VERSION "canboat-J1939-curated"

NS_ :

BS_:

BU_: Vector__XXX
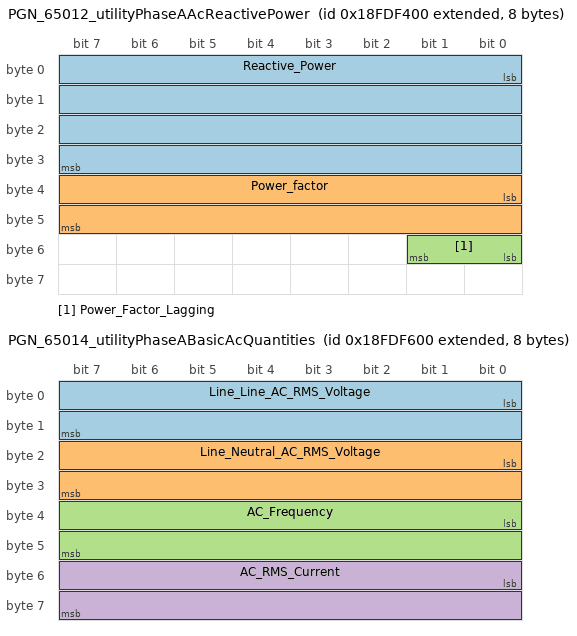
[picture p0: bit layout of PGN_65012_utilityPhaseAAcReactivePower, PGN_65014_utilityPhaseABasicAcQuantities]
BO_ 2566779904 PGN_65012_utilityPhaseAAcReactivePower: 8 Vector__XXX
 SG_ Reactive_Power : 0|32@1- (1.0,0) [-2147483648|2147483647] "" Vector__XXX
 SG_ Power_factor : 32|16@1+ (6.103515625e-05,0) [0.0|3.99993896484375] "Cos Phi" Vector__XXX
 SG_ Power_Factor_Lagging : 48|2@1+ (1.0,0) [0|3] "" Vector__XXX

BO_ 2566780160 PGN_65013_utilityPhaseAAcPower: 8 Vector__XXX
 SG_ Real_Power : 0|32@1- (1.0,0) [-2147483648|2147483647] "" Vector__XXX
 SG_ Apparent_Power : 32|32@1- (1.0,0) [-2147483648|2147483647] "" Vector__XXX

BO_ 2566780416 PGN_65014_utilityPhaseABasicAcQuantities: 8 Vector__XXX
 SG_ Line_Line_AC_RMS_Voltage : 0|16@1+ (1.0,0) [0|65535] "" Vector__XXX
 SG_ Line_Neutral_AC_RMS_Voltage : 16|16@1+ (1.0,0) [0|65535] "" Vector__XXX
 SG_ AC_Frequency : 32|16@1+ (0.0078125,0) [0.0|511.9921875] "" Vector__XXX
 SG_ AC_RMS_Current : 48|16@1+ (1.0,0) [0|65535] "" Vector__XXX

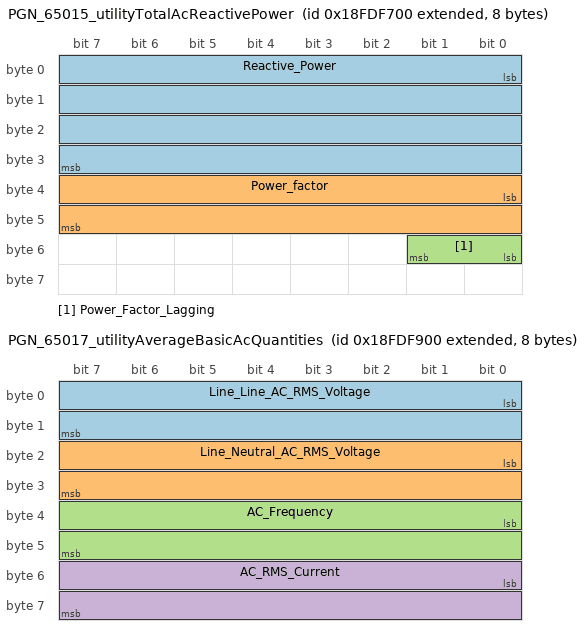
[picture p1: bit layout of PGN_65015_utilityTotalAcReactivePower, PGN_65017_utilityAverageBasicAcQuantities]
BO_ 2566780672 PGN_65015_utilityTotalAcReactivePower: 8 Vector__XXX
 SG_ Reactive_Power : 0|32@1- (1.0,0) [-2147483648|2147483647] "" Vector__XXX
 SG_ Power_factor : 32|16@1+ (6.103515625e-05,0) [0.0|3.99993896484375] "Cos Phi" Vector__XXX
 SG_ Power_Factor_Lagging : 48|2@1+ (1.0,0) [0|3] "" Vector__XXX

BO_ 2566780928 PGN_65016_utilityTotalAcPower: 8 Vector__XXX
 SG_ Real_Power : 0|32@1- (1.0,0) [-2147483648|2147483647] "" Vector__XXX
 SG_ Apparent_Power : 32|32@1- (1.0,0) [-2147483648|2147483647] "" Vector__XXX

BO_ 2566781184 PGN_65017_utilityAverageBasicAcQuantities: 8 Vector__XXX
 SG_ Line_Line_AC_RMS_Voltage : 0|16@1+ (1.0,0) [0|65535] "" Vector__XXX
 SG_ Line_Neutral_AC_RMS_Voltage : 16|16@1+ (1.0,0) [0|65535] "" Vector__XXX
 SG_ AC_Frequency : 32|16@1+ (0.0078125,0) [0.0|511.9921875] "" Vector__XXX
 SG_ AC_RMS_Current : 48|16@1+ (1.0,0) [0|65535] "" Vector__XXX

BO_ 2566781440 PGN_65018_generatorTotalAcEnergy: 8 Vector__XXX
 SG_ Total_Energy_Export : 0|32@1+ (1.0,0) [0|4294967295] "" Vector__XXX
 SG_ Total_Energy_Import : 32|32@1+ (1.0,0) [0|4294967295] "" Vector__XXX

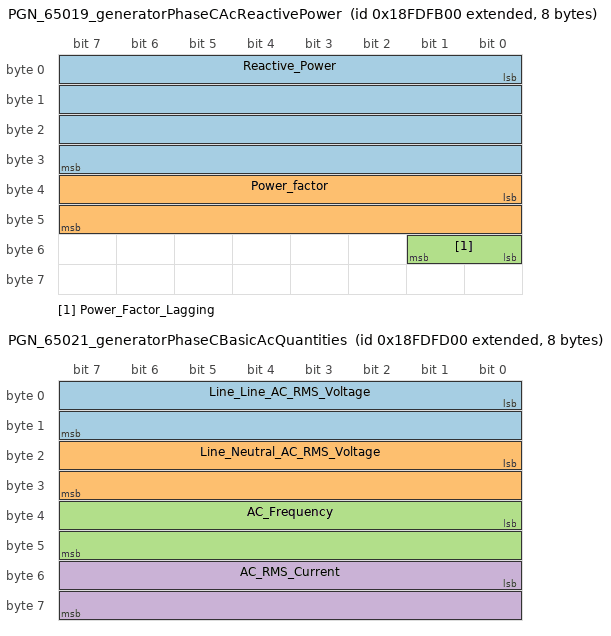
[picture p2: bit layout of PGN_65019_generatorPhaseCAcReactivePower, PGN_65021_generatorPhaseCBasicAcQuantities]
BO_ 2566781696 PGN_65019_generatorPhaseCAcReactivePower: 8 Vector__XXX
 SG_ Reactive_Power : 0|32@1- (1.0,0) [-2147483648|2147483647] "" Vector__XXX
 SG_ Power_factor : 32|16@1+ (6.103515625e-05,0) [0.0|3.99993896484375] "Cos Phi" Vector__XXX
 SG_ Power_Factor_Lagging : 48|2@1+ (1.0,0) [0|3] "" Vector__XXX

BO_ 2566781952 PGN_65020_generatorPhaseCAcPower: 8 Vector__XXX
 SG_ Real_Power : 0|32@1- (1.0,0) [-2147483648|2147483647] "" Vector__XXX
 SG_ Apparent_Power : 32|32@1- (1.0,0) [-2147483648|2147483647] "" Vector__XXX

BO_ 2566782208 PGN_65021_generatorPhaseCBasicAcQuantities: 8 Vector__XXX
 SG_ Line_Line_AC_RMS_Voltage : 0|16@1+ (1.0,0) [0|65535] "" Vector__XXX
 SG_ Line_Neutral_AC_RMS_Voltage : 16|16@1+ (1.0,0) [0|65535] "" Vector__XXX
 SG_ AC_Frequency : 32|16@1+ (0.0078125,0) [0.0|511.9921875] "" Vector__XXX
 SG_ AC_RMS_Current : 48|16@1+ (1.0,0) [0|65535] "" Vector__XXX

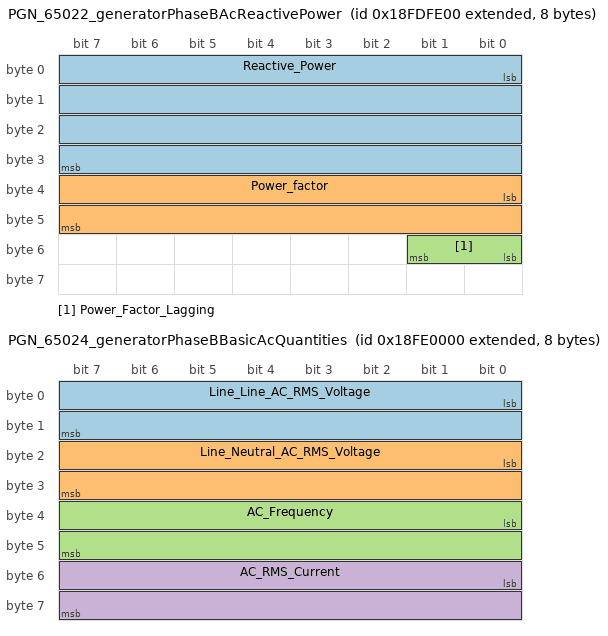
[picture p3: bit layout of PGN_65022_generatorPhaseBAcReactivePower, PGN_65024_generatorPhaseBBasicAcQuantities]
BO_ 2566782464 PGN_65022_generatorPhaseBAcReactivePower: 8 Vector__XXX
 SG_ Reactive_Power : 0|32@1- (1.0,0) [-2147483648|2147483647] "" Vector__XXX
 SG_ Power_factor : 32|16@1+ (6.103515625e-05,0) [0.0|3.99993896484375] "Cos Phi" Vector__XXX
 SG_ Power_Factor_Lagging : 48|2@1+ (1.0,0) [0|3] "" Vector__XXX

BO_ 2566782720 PGN_65023_generatorPhaseBAcPower: 8 Vector__XXX
 SG_ Real_Power : 0|32@1- (1.0,0) [-2147483648|2147483647] "" Vector__XXX
 SG_ Apparent_Power : 32|32@1- (1.0,0) [-2147483648|2147483647] "" Vector__XXX

BO_ 2566782976 PGN_65024_generatorPhaseBBasicAcQuantities: 8 Vector__XXX
 SG_ Line_Line_AC_RMS_Voltage : 0|16@1+ (1.0,0) [0|65535] "" Vector__XXX
 SG_ Line_Neutral_AC_RMS_Voltage : 16|16@1+ (1.0,0) [0|65535] "" Vector__XXX
 SG_ AC_Frequency : 32|16@1+ (0.0078125,0) [0.0|511.9921875] "" Vector__XXX
 SG_ AC_RMS_Current : 48|16@1+ (1.0,0) [0|65535] "" Vector__XXX

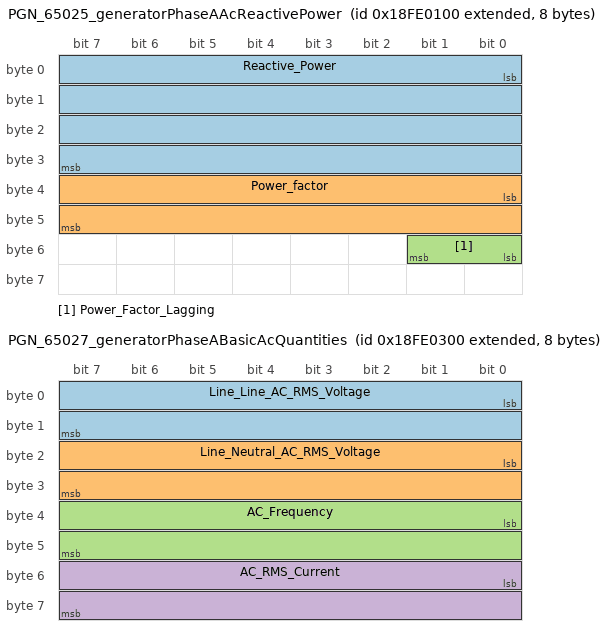
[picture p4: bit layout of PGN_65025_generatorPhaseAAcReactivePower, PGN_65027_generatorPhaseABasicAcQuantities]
BO_ 2566783232 PGN_65025_generatorPhaseAAcReactivePower: 8 Vector__XXX
 SG_ Reactive_Power : 0|32@1- (1.0,0) [-2147483648|2147483647] "" Vector__XXX
 SG_ Power_factor : 32|16@1+ (6.103515625e-05,0) [0.0|3.99993896484375] "Cos Phi" Vector__XXX
 SG_ Power_Factor_Lagging : 48|2@1+ (1.0,0) [0|3] "" Vector__XXX

BO_ 2566783488 PGN_65026_generatorPhaseAAcPower: 8 Vector__XXX
 SG_ Real_Power : 0|32@1- (1.0,0) [-2147483648|2147483647] "" Vector__XXX
 SG_ Apparent_Power : 32|32@1- (1.0,0) [-2147483648|2147483647] "" Vector__XXX

BO_ 2566783744 PGN_65027_generatorPhaseABasicAcQuantities: 8 Vector__XXX
 SG_ Line_Line_AC_RMS_Voltage : 0|16@1+ (1.0,0) [0|65535] "" Vector__XXX
 SG_ Line_Neutral_AC_RMS_Voltage : 16|16@1+ (1.0,0) [0|65535] "" Vector__XXX
 SG_ AC_Frequency : 32|16@1+ (0.0078125,0) [0.0|511.9921875] "" Vector__XXX
 SG_ AC_RMS_Current : 48|16@1+ (1.0,0) [0|65535] "" Vector__XXX

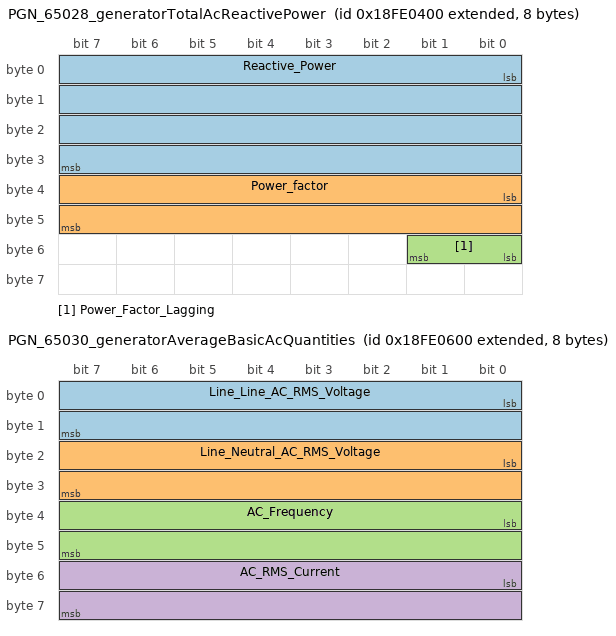
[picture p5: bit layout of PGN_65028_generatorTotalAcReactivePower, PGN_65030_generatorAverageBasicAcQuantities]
BO_ 2566784000 PGN_65028_generatorTotalAcReactivePower: 8 Vector__XXX
 SG_ Reactive_Power : 0|32@1- (1.0,0) [-2147483648|2147483647] "" Vector__XXX
 SG_ Power_factor : 32|16@1+ (6.103515625e-05,0) [0.0|3.99993896484375] "Cos Phi" Vector__XXX
 SG_ Power_Factor_Lagging : 48|2@1+ (1.0,0) [0|3] "" Vector__XXX

BO_ 2566784256 PGN_65029_generatorTotalAcPower: 8 Vector__XXX
 SG_ Real_Power : 0|32@1- (1.0,0) [-2147483648|2147483647] "" Vector__XXX
 SG_ Apparent_Power : 32|32@1- (1.0,0) [-2147483648|2147483647] "" Vector__XXX

BO_ 2566784512 PGN_65030_generatorAverageBasicAcQuantities: 8 Vector__XXX
 SG_ Line_Line_AC_RMS_Voltage : 0|16@1+ (1.0,0) [0|65535] "" Vector__XXX
 SG_ Line_Neutral_AC_RMS_Voltage : 16|16@1+ (1.0,0) [0|65535] "" Vector__XXX
 SG_ AC_Frequency : 32|16@1+ (0.0078125,0) [0.0|511.9921875] "" Vector__XXX
 SG_ AC_RMS_Current : 48|16@1+ (1.0,0) [0|65535] "" Vector__XXX

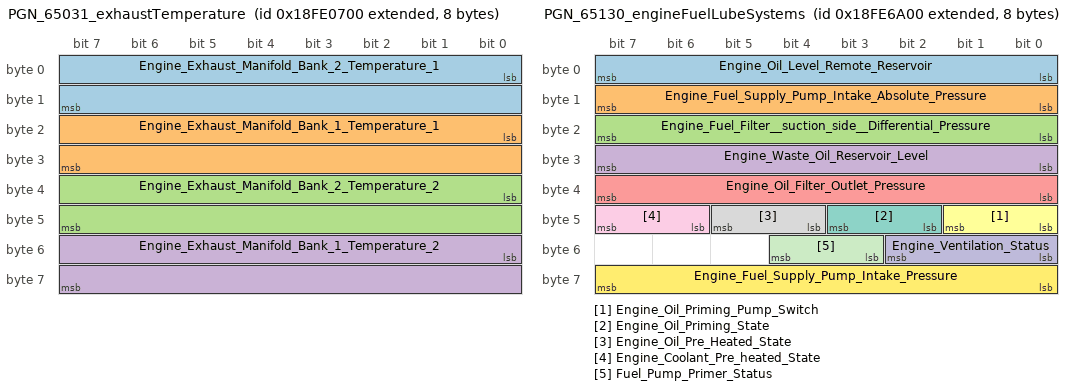
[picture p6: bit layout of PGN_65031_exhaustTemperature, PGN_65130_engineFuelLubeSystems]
BO_ 2566784768 PGN_65031_exhaustTemperature: 8 Vector__XXX
 SG_ Engine_Exhaust_Manifold_Bank_2_Temperature_1 : 0|16@1+ (0.03125,0) [0.0|2047.96875] "" Vector__XXX
 SG_ Engine_Exhaust_Manifold_Bank_1_Temperature_1 : 16|16@1+ (0.03125,0) [0.0|2047.96875] "" Vector__XXX
 SG_ Engine_Exhaust_Manifold_Bank_2_Temperature_2 : 32|16@1+ (0.03125,0) [0.0|2047.96875] "" Vector__XXX
 SG_ Engine_Exhaust_Manifold_Bank_1_Temperature_2 : 48|16@1+ (0.03125,0) [0.0|2047.96875] "" Vector__XXX

BO_ 2566810112 PGN_65130_engineFuelLubeSystems: 8 Vector__XXX
 SG_ Engine_Oil_Level_Remote_Reservoir : 0|8@1+ (0.4,0) [0.0|102.0] "%" Vector__XXX
 SG_ Engine_Fuel_Supply_Pump_Intake_Absolute_Pressure : 8|8@1+ (2000.0,0) [0.0|510000.0] "" Vector__XXX
 SG_ Engine_Fuel_Filter__suction_side__Differential_Pressure : 16|8@1+ (2000.0,0) [0.0|510000.0] "" Vector__XXX
 SG_ Engine_Waste_Oil_Reservoir_Level : 24|8@1+ (0.4,0) [0.0|102.0] "%" Vector__XXX
 SG_ Engine_Oil_Filter_Outlet_Pressure : 32|8@1+ (4.0,0) [0.0|1020.0] "kPa" Vector__XXX
 SG_ Engine_Oil_Priming_Pump_Switch : 40|2@1+ (1.0,0) [0|3] "" Vector__XXX
 SG_ Engine_Oil_Priming_State : 42|2@1+ (1.0,0) [0|3] "" Vector__XXX
 SG_ Engine_Oil_Pre_Heated_State : 44|2@1+ (1.0,0) [0|3] "" Vector__XXX
 SG_ Engine_Coolant_Pre_heated_State : 46|2@1+ (1.0,0) [0|3] "" Vector__XXX
 SG_ Engine_Ventilation_Status : 48|3@1+ (1.0,0) [0|7] "" Vector__XXX
 SG_ Fuel_Pump_Primer_Status : 51|2@1+ (1.0,0) [0|3] "" Vector__XXX
 SG_ Engine_Fuel_Supply_Pump_Intake_Pressure : 56|8@1+ (2000.0,0) [0.0|510000.0] "" Vector__XXX

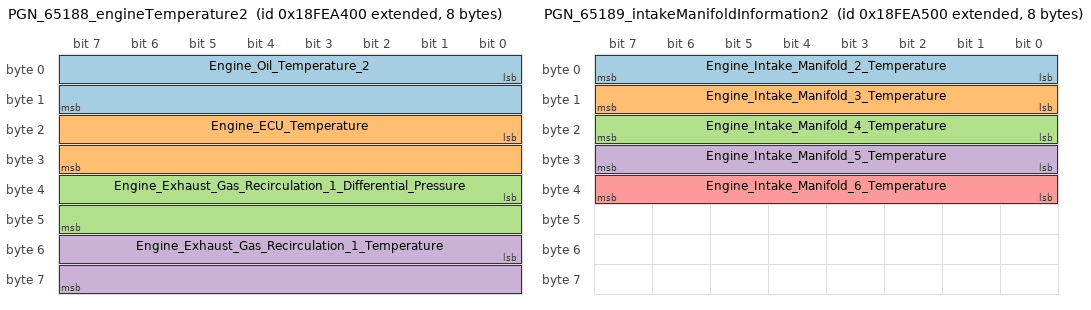
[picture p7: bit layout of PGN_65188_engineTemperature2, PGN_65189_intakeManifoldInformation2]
BO_ 2566824960 PGN_65188_engineTemperature2: 8 Vector__XXX
 SG_ Engine_Oil_Temperature_2 : 0|16@1+ (0.03125,0) [0.0|2047.96875] "" Vector__XXX
 SG_ Engine_ECU_Temperature : 16|16@1+ (0.03125,0) [0.0|2047.96875] "" Vector__XXX
 SG_ Engine_Exhaust_Gas_Recirculation_1_Differential_Pressure : 32|16@1+ (0.0078125,0) [0.0|511.9921875] "kPa" Vector__XXX
 SG_ Engine_Exhaust_Gas_Recirculation_1_Temperature : 48|16@1+ (0.03125,0) [0.0|2047.96875] "" Vector__XXX

BO_ 2566825216 PGN_65189_intakeManifoldInformation2: 8 Vector__XXX
 SG_ Engine_Intake_Manifold_2_Temperature : 0|8@1+ (1.0,0) [0|255] "" Vector__XXX
 SG_ Engine_Intake_Manifold_3_Temperature : 8|8@1+ (1.0,0) [0|255] "" Vector__XXX
 SG_ Engine_Intake_Manifold_4_Temperature : 16|8@1+ (1.0,0) [0|255] "" Vector__XXX
 SG_ Engine_Intake_Manifold_5_Temperature : 24|8@1+ (1.0,0) [0|255] "" Vector__XXX
 SG_ Engine_Intake_Manifold_6_Temperature : 32|8@1+ (1.0,0) [0|255] "" Vector__XXX

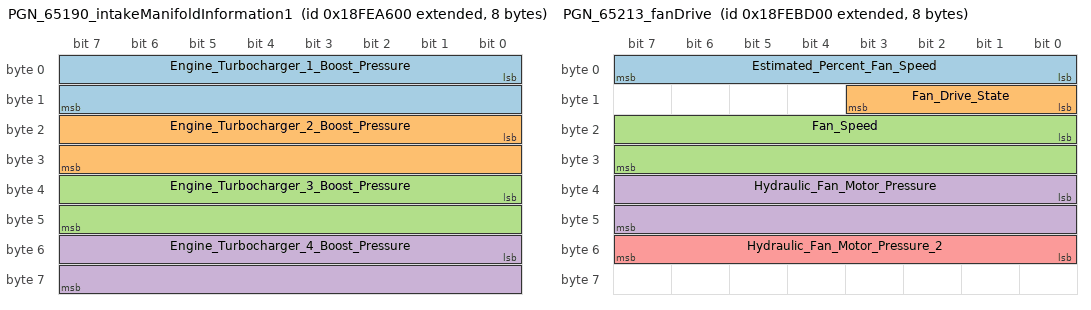
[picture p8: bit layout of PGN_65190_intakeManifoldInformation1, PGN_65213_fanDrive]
BO_ 2566825472 PGN_65190_intakeManifoldInformation1: 8 Vector__XXX
 SG_ Engine_Turbocharger_1_Boost_Pressure : 0|16@1+ (0.125,0) [0.0|8191.875] "kPa" Vector__XXX
 SG_ Engine_Turbocharger_2_Boost_Pressure : 16|16@1+ (0.125,0) [0.0|8191.875] "kPa" Vector__XXX
 SG_ Engine_Turbocharger_3_Boost_Pressure : 32|16@1+ (0.125,0) [0.0|8191.875] "kPa" Vector__XXX
 SG_ Engine_Turbocharger_4_Boost_Pressure : 48|16@1+ (0.125,0) [0.0|8191.875] "kPa" Vector__XXX

BO_ 2566828288 PGN_65201_ecuHistory: 8 Vector__XXX
 SG_ Total_ECU_Distance : 0|32@1+ (0.125,0) [0.0|536870911.875] "km" Vector__XXX
 SG_ Total_ECU_Run_Time : 32|32@1+ (0.05,0) [0.0|214748364.75] "h" Vector__XXX

BO_ 2566831360 PGN_65213_fanDrive: 8 Vector__XXX
 SG_ Estimated_Percent_Fan_Speed : 0|8@1+ (0.4,0) [0.0|102.0] "%" Vector__XXX
 SG_ Fan_Drive_State : 8|4@1+ (1.0,0) [0|15] "" Vector__XXX
 SG_ Fan_Speed : 16|16@1+ (0.125,0) [0.0|8191.875] "rpm" Vector__XXX
 SG_ Hydraulic_Fan_Motor_Pressure : 32|16@1+ (1000.0,0) [0.0|65535000.0] "" Vector__XXX
 SG_ Hydraulic_Fan_Motor_Pressure_2 : 48|8@1+ (500.0,0) [0.0|127500.0] "" Vector__XXX

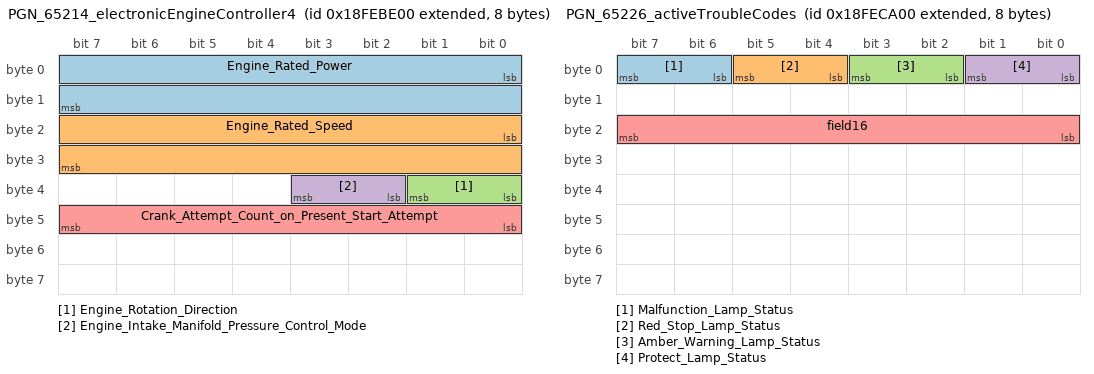
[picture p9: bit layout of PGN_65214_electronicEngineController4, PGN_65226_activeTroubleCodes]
BO_ 2566831616 PGN_65214_electronicEngineController4: 8 Vector__XXX
 SG_ Engine_Rated_Power : 0|16@1+ (0.5,0) [0.0|32767.5] "kW" Vector__XXX
 SG_ Engine_Rated_Speed : 16|16@1+ (0.125,0) [0.0|8191.875] "rpm" Vector__XXX
 SG_ Engine_Rotation_Direction : 32|2@1+ (1.0,0) [0|3] "" Vector__XXX
 SG_ Engine_Intake_Manifold_Pressure_Control_Mode : 34|2@1+ (1.0,0) [0|3] "" Vector__XXX
 SG_ Crank_Attempt_Count_on_Present_Start_Attempt : 40|8@1+ (1.0,0) [0|255] "" Vector__XXX

BO_ 2566834688 PGN_65226_activeTroubleCodes: 8 Vector__XXX
 SG_ Malfunction_Lamp_Status : 6|2@1+ (1.0,0) [0|3] "" Vector__XXX
 SG_ Red_Stop_Lamp_Status : 4|2@1+ (1.0,0) [0|3] "" Vector__XXX
 SG_ Amber_Warning_Lamp_Status : 2|2@1+ (1.0,0) [0|3] "" Vector__XXX
 SG_ Protect_Lamp_Status : 0|2@1+ (1.0,0) [0|3] "" Vector__XXX
 SG_ field16 : 16|8@1+ (1.0,0) [0|255] "" Vector__XXX

BO_ 2566838272 PGN_65240_isoCommandedAddress: 9 Vector__XXX
 SG_ Unique_Number : 0|21@1+ (1.0,0) [0|2097151] "" Vector__XXX
 SG_ Manufacturer_Code : 21|11@1+ (1.0,0) [0|2047] "Manufacturer Code" Vector__XXX
 SG_ Device_Instance_Lower : 32|3@1+ (1.0,0) [0|7] "" Vector__XXX
 SG_ Device_Instance_Upper : 35|5@1+ (1.0,0) [0|31] "" Vector__XXX
 SG_ Device_Function : 40|8@1+ (1.0,0) [0|255] "" Vector__XXX
 SG_ Device_Class : 49|7@1+ (1.0,0) [0|127] "" Vector__XXX
 SG_ System_Instance : 56|4@1+ (1.0,0) [0|15] "" Vector__XXX
 SG_ Industry_Code : 60|3@1+ (1.0,0) [0|7] "" Vector__XXX
 SG_ New_Source_Address : 64|8@1+ (1.0,0) [0|255] "" Vector__XXX

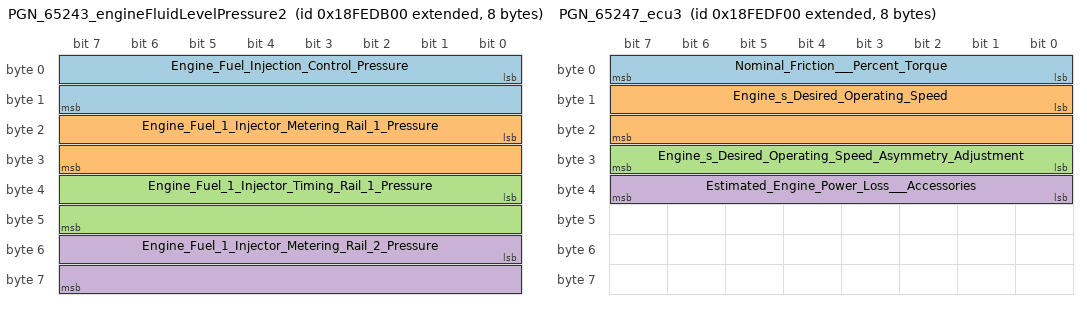
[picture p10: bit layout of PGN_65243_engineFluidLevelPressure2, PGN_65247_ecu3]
BO_ 2566839040 PGN_65243_engineFluidLevelPressure2: 8 Vector__XXX
 SG_ Engine_Fuel_Injection_Control_Pressure : 0|16@1+ (0.00390625,0) [0.0|255.99609375] "MPa" Vector__XXX
 SG_ Engine_Fuel_1_Injector_Metering_Rail_1_Pressure : 16|16@1+ (0.00390625,0) [0.0|255.99609375] "MPa" Vector__XXX
 SG_ Engine_Fuel_1_Injector_Timing_Rail_1_Pressure : 32|16@1+ (0.00390625,0) [0.0|255.99609375] "MPa" Vector__XXX
 SG_ Engine_Fuel_1_Injector_Metering_Rail_2_Pressure : 48|16@1+ (0.00390625,0) [0.0|255.99609375] "MPa" Vector__XXX

BO_ 2566839296 PGN_65244_idleOperation: 8 Vector__XXX
 SG_ Engine_Total_Idle_Fuel_Used : 0|32@1+ (0.5,0) [0.0|2147483647.5] "" Vector__XXX
 SG_ Engine_Total_Idle_Hours : 32|32@1+ (180.0,0) [0.0|773094113100.0] "" Vector__XXX

BO_ 2566840064 PGN_65247_ecu3: 8 Vector__XXX
 SG_ Nominal_Friction___Percent_Torque : 0|8@1- (1.0,0) [-128|127] "%" Vector__XXX
 SG_ Engine_s_Desired_Operating_Speed : 8|16@1+ (0.125,0) [0.0|8191.875] "rpm" Vector__XXX
 SG_ Engine_s_Desired_Operating_Speed_Asymmetry_Adjustment : 24|8@1+ (1.0,0) [0|255] "" Vector__XXX
 SG_ Estimated_Engine_Power_Loss___Accessories : 32|8@1+ (1.0,0) [0|255] "%" Vector__XXX

BO_ 2566841600 PGN_65253_engineHours: 8 Vector__XXX
 SG_ Engine_Total_Hours_of_Operation : 0|32@1+ (180.0,0) [0.0|773094113100.0] "" Vector__XXX
 SG_ Engine_Total_Revolutions : 32|32@1+ (1000.0,0) [0.0|4294967295000.0] "r" Vector__XXX

BO_ 2566842624 PGN_65257_fuelConsumptionLiquid1: 8 Vector__XXX
 SG_ Engine_Trip_Fuel : 0|32@1+ (0.5,0) [0.0|2147483647.5] "" Vector__XXX
 SG_ Engine_Total_Fuel_Used : 32|32@1+ (0.5,0) [0.0|2147483647.5] "" Vector__XXX

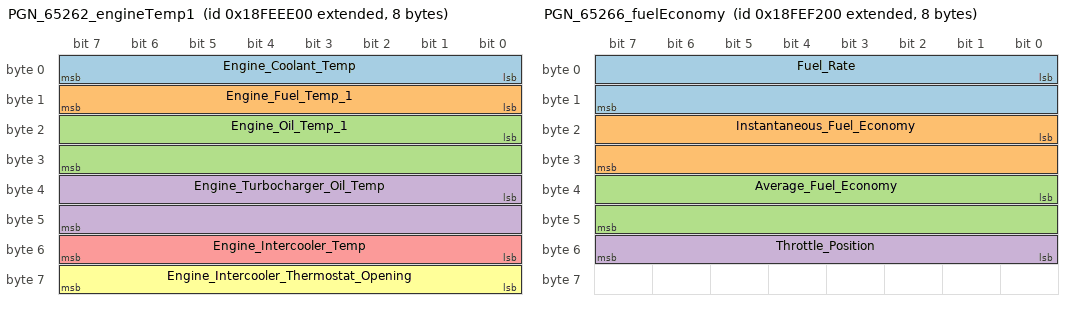
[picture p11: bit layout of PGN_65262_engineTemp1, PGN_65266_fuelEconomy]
BO_ 2566843904 PGN_65262_engineTemp1: 8 Vector__XXX
 SG_ Engine_Coolant_Temp : 0|8@1+ (1.0,0) [0|255] "" Vector__XXX
 SG_ Engine_Fuel_Temp_1 : 8|8@1+ (1.0,0) [0|255] "" Vector__XXX
 SG_ Engine_Oil_Temp_1 : 16|16@1+ (0.03125,0) [0.0|2047.96875] "" Vector__XXX
 SG_ Engine_Turbocharger_Oil_Temp : 32|16@1+ (0.03125,0) [0.0|2047.96875] "" Vector__XXX
 SG_ Engine_Intercooler_Temp : 48|8@1+ (1.0,0) [0|255] "" Vector__XXX
 SG_ Engine_Intercooler_Thermostat_Opening : 56|8@1+ (0.4,0) [0.0|102.0] "%" Vector__XXX

BO_ 2566844928 PGN_65266_fuelEconomy: 8 Vector__XXX
 SG_ Fuel_Rate : 0|16@1+ (0.05,0) [0.0|3276.75] "" Vector__XXX
 SG_ Instantaneous_Fuel_Economy : 16|16@1+ (0.001953125,0) [0.0|127.998046875] "" Vector__XXX
 SG_ Average_Fuel_Economy : 32|16@1+ (0.001953125,0) [0.0|127.998046875] "" Vector__XXX
 SG_ Throttle_Position : 48|8@1+ (0.4,0) [0.0|102.0] "%" Vector__XXX

BO_ 2566845696 PGN_65269_ambientConditions: 8 Vector__XXX
 SG_ Barometric_Pressure : 0|8@1+ (500.0,0) [0.0|127500.0] "" Vector__XXX

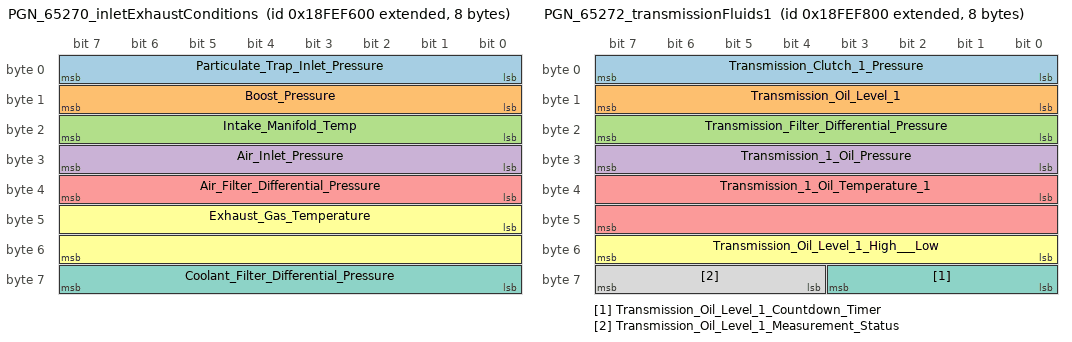
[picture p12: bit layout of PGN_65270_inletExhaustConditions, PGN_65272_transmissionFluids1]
BO_ 2566845952 PGN_65270_inletExhaustConditions: 8 Vector__XXX
 SG_ Particulate_Trap_Inlet_Pressure : 0|8@1+ (2000.0,0) [0.0|510000.0] "" Vector__XXX
 SG_ Boost_Pressure : 8|8@1+ (2000.0,0) [0.0|510000.0] "" Vector__XXX
 SG_ Intake_Manifold_Temp : 16|8@1+ (1.0,0) [0|255] "" Vector__XXX
 SG_ Air_Inlet_Pressure : 24|8@1+ (2000.0,0) [0.0|510000.0] "" Vector__XXX
 SG_ Air_Filter_Differential_Pressure : 32|8@1+ (50.0,0) [0.0|12750.0] "" Vector__XXX
 SG_ Exhaust_Gas_Temperature : 40|16@1+ (0.03125,0) [0.0|2047.96875] "" Vector__XXX
 SG_ Coolant_Filter_Differential_Pressure : 56|8@1+ (500.0,0) [0.0|127500.0] "" Vector__XXX

BO_ 2566846208 PGN_65271_vehicleElectricalPower: 8 Vector__XXX
 SG_ Battery_Voltage : 32|16@1+ (0.05,0) [0.0|3276.75] "" Vector__XXX

BO_ 2566846464 PGN_65272_transmissionFluids1: 8 Vector__XXX
 SG_ Transmission_Clutch_1_Pressure : 0|8@1+ (16.0,0) [0.0|4080.0] "kPa" Vector__XXX
 SG_ Transmission_Oil_Level_1 : 8|8@1+ (0.4,0) [0.0|102.0] "%" Vector__XXX
 SG_ Transmission_Filter_Differential_Pressure : 16|8@1+ (2000.0,0) [0.0|510000.0] "" Vector__XXX
 SG_ Transmission_1_Oil_Pressure : 24|8@1+ (16.0,0) [0.0|4080.0] "kPa" Vector__XXX
 SG_ Transmission_1_Oil_Temperature_1 : 32|16@1+ (0.03125,0) [0.0|2047.96875] "" Vector__XXX
 SG_ Transmission_Oil_Level_1_High___Low : 48|8@1+ (0.5,0) [0.0|127.5] "L" Vector__XXX
 SG_ Transmission_Oil_Level_1_Countdown_Timer : 56|4@1+ (1.0,0) [0|15] "" Vector__XXX
 SG_ Transmission_Oil_Level_1_Measurement_Status : 60|4@1+ (1.0,0) [0|15] "" Vector__XXX

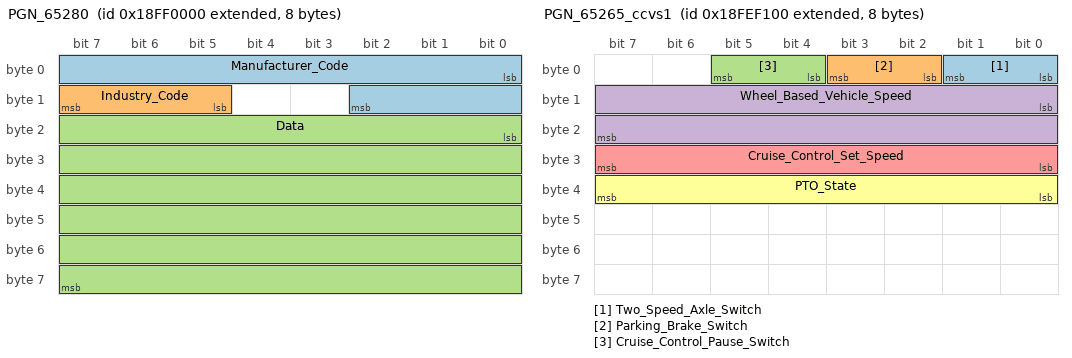
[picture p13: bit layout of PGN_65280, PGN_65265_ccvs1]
BO_ 2566848512 PGN_65280: 8 Vector__XXX
 SG_ Manufacturer_Code : 0|11@1+ (1.0,0) [0|2047] "" Vector__XXX
 SG_ Industry_Code : 13|3@1+ (1.0,0) [0|7] "" Vector__XXX
 SG_ Data : 16|48@1+ (1.0,0) [0|281474976710655] "" Vector__XXX

BO_ 2582446080 PGN_126208: 223 Vector__XXX
 SG_ Data : 0|1784@1+ (1.0,0) [0|1090215279796298345343057319992441691038624747443985361781209060500115864369550760897269927218265076257224706224150656474098235960303036328065314058501678867531182833105052489870268422279120576700031813116210596361941430020414688522690787050244934600671795757515093047026287646566366777283893649942831776083163858446641848270013788759459916945946844663111358071639842481472666169361795887031940572252862030682746818684507336852618633070135215708762463263460541984102045620907003420426453486084172633338261276848631947315738747720031010815] "" Vector__XXX

BO_ 2582577152 PGN_126720: 223 Vector__XXX
 SG_ Manufacturer_Code : 0|11@1+ (1.0,0) [0|2047] "" Vector__XXX
 SG_ Industry_Code : 13|3@1+ (1.0,0) [0|7] "" Vector__XXX
 SG_ Data : 16|1768@1+ (1.0,0) [0|16635364987126134419907490844611231857889171561340108669757218330385068731224834608417815051548234195819468783937845710359164977421616154908223175941492902641772198991471137845920843845811776377869137773379678289214194183661112800944378464511794046030758602257005203964634516091405743061582849883160885255175229773660916874237270946647032424101972117051870087763059119895517977437771543686400460392041962138103436564399831189767740372774280024852942859855049773927338342604171805121253257539126169331943684033945189625789470637817855] "" Vector__XXX

BO_ 2582642688 PGN_126976: 223 Vector__XXX
 SG_ Data : 0|1784@1+ (1.0,0) [0|1090215279796298345343057319992441691038624747443985361781209060500115864369550760897269927218265076257224706224150656474098235960303036328065314058501678867531182833105052489870268422279120576700031813116210596361941430020414688522690787050244934600671795757515093047026287646566366777283893649942831776083163858446641848270013788759459916945946844663111358071639842481472666169361795887031940572252862030682746818684507336852618633070135215708762463263460541984102045620907003420426453486084172633338261276848631947315738747720031010815] "" Vector__XXX

BO_ 2583625728 PGN_130816: 223 Vector__XXX
 SG_ Data : 0|1784@1+ (1.0,0) [0|1090215279796298345343057319992441691038624747443985361781209060500115864369550760897269927218265076257224706224150656474098235960303036328065314058501678867531182833105052489870268422279120576700031813116210596361941430020414688522690787050244934600671795757515093047026287646566366777283893649942831776083163858446641848270013788759459916945946844663111358071639842481472666169361795887031940572252862030682746818684507336852618633070135215708762463263460541984102045620907003420426453486084172633338261276848631947315738747720031010815] "" Vector__XXX

BO_ 2566844672 PGN_65265_ccvs1: 8 Vector__XXX
 SG_ Two_Speed_Axle_Switch : 0|2@1+ (1.0,0) [0|3] "" Vector__XXX
 SG_ Parking_Brake_Switch : 2|2@1+ (1.0,0) [0|3] "" Vector__XXX
 SG_ Cruise_Control_Pause_Switch : 4|2@1+ (1.0,0) [0|3] "" Vector__XXX
 SG_ Wheel_Based_Vehicle_Speed : 8|16@1+ (0.00390625,0) [0.0|255.99609375] "km/h" Vector__XXX
 SG_ Cruise_Control_Set_Speed : 24|8@1+ (1.0,0) [0|255] "" Vector__XXX
 SG_ PTO_State : 32|8@1+ (1.0,0) [0|255] "" Vector__XXX

CM_ BO_ 2566779904 "J1939: PGN 65012 - Utility Phase A AC Reactive Power (type: Single)";
CM_ BO_ 2566780160 "J1939: PGN 65013 - Utility Phase A AC Power (type: Single)";
CM_ BO_ 2566780416 "J1939: PGN 65014 - Utility Phase A Basic AC Quantities (type: Single)";
CM_ BO_ 2566780672 "J1939: PGN 65015 - Utility Total AC Reactive Power (type: Single)";
CM_ BO_ 2566780928 "J1939: PGN 65016 - Utility Total AC Power (type: Single)";
CM_ BO_ 2566781184 "J1939: PGN 65017 - Utility Average Basic AC Quantities (type: Single)";
CM_ BO_ 2566781440 "J1939: PGN 65018 - Generator Total AC Energy (type: Single)";
CM_ BO_ 2566781696 "J1939: PGN 65019 - Generator Phase C AC Reactive Power (type: Single)";
CM_ BO_ 2566781952 "J1939: PGN 65020 - Generator Phase C AC Power (type: Single)";
CM_ BO_ 2566782208 "J1939: PGN 65021 - Generator Phase C Basic AC Quantities (type: Single)";
CM_ BO_ 2566782464 "J1939: PGN 65022 - Generator Phase B AC Reactive Power (type: Single)";
CM_ BO_ 2566782720 "J1939: PGN 65023 - Generator Phase B AC Power (type: Single)";
CM_ BO_ 2566782976 "J1939: PGN 65024 - Generator Phase B Basic AC Quantities (type: Single)";
CM_ BO_ 2566783232 "J1939: PGN 65025 - Generator Phase A AC Reactive Power (type: Single)";
CM_ BO_ 2566783488 "J1939: PGN 65026 - Generator Phase A AC Power (type: Single)";
CM_ BO_ 2566783744 "J1939: PGN 65027 - Generator Phase A Basic AC Quantities (type: Single)";
CM_ BO_ 2566784000 "J1939: PGN 65028 - Generator Total AC Reactive Power (type: Single)";
CM_ BO_ 2566784256 "J1939: PGN 65029 - Generator Total AC Power (type: Single)";
CM_ BO_ 2566784512 "J1939: PGN 65030 - Generator Average Basic AC Quantities (type: Single)";
CM_ BO_ 2566784768 "J1939: PGN 65031 - Exhaust Temperature (type: Single)";
CM_ BO_ 2566810112 "J1939: PGN 65130 - Engine Fuel/Lube Systems (type: Single)";
CM_ BO_ 2566824960 "J1939: PGN 65188 - Engine Temperature 2 (type: Single)";
CM_ BO_ 2566825216 "J1939: PGN 65189 - Intake Manifold Information 2 (type: Single)";
CM_ BO_ 2566825472 "J1939: PGN 65190 - Intake Manifold Information 1 (type: Single)";
CM_ BO_ 2566828288 "J1939: PGN 65201 - ECU History (type: Single)";
CM_ BO_ 2566831360 "J1939: PGN 65213 - Fan Drive (type: Single)";
CM_ BO_ 2566831616 "J1939: PGN 65214 - Electronic Engine Controller 4 (type: Single)";
CM_ BO_ 2566834688 "J1939: PGN 65226 - Active Trouble Codes (type: Single)";
CM_ BO_ 2566838272 "J1939: PGN 65240 - ISO Commanded Address (type: ISO)";
CM_ BO_ 2566839040 "J1939: PGN 65243 - Engine Fluid Level/Pressure 2 (type: Single)";
CM_ BO_ 2566839296 "J1939: PGN 65244 - Idle Operation (type: Single)";
CM_ BO_ 2566840064 "J1939: PGN 65247 - ECU #3 (type: Single)";
CM_ BO_ 2566841600 "J1939: PGN 65253 - Engine Hours, Revolutions (type: Single)";
CM_ BO_ 2566842624 "J1939: PGN 65257 - Fuel Consumption (Liquid) 1 (type: Single)";
CM_ BO_ 2566843904 "J1939: PGN 65262 - Engine Temp #1 (type: Single)";
CM_ BO_ 2566844928 "J1939: PGN 65266 - Fuel Economy (type: Single)";
CM_ BO_ 2566845696 "J1939: PGN 65269 - Ambient Conditions (type: Single)";
CM_ BO_ 2566845952 "J1939: PGN 65270 - Inlet/Exhaust Conditions (type: Single)";
CM_ BO_ 2566846208 "J1939: PGN 65271 - Vehicle Electrical Power (type: Single)";
CM_ BO_ 2566846464 "J1939: PGN 65272 - Transmission Fluids 1 (type: Single)";
CM_ BO_ 2566848512 "J1939: PGN 65280 - 0xFF00-0xFFFF: Manufacturer Proprietary single-frame non-addressed (type: Single)";
CM_ BO_ 2582446080 "J1939: PGN 126208 - 0x1ED00 - 0x1EE00: Standardized fast-packet addressed (type: Fast)";
CM_ BO_ 2582577152 "J1939: PGN 126720 - 0x1EF00-0x1EFFF: Manufacturer Proprietary fast-packet addressed (type: Fast)";
CM_ BO_ 2582642688 "J1939: PGN 126976 - 0x1F000-0x1FEFF: Standardized mixed single/fast packet non-addressed (type: Mixed)";
CM_ BO_ 2583625728 "J1939: PGN 130816 - 0x1FF00-0x1FFFF: Manufacturer Specific fast-packet non-addressed (type: Fast)";
CM_ BO_ 2566844672 "J1939: PGN 65265 - Cruise Control / Vehicle Speed 1 (CCVS1) (type: Single)";
CM_ SG_ 2566779904 Reactive_Power "canboat type: POWER_FIX32_VAR_OFFSET";
CM_ SG_ 2566779904 Power_factor "canboat type: UINT16";
CM_ SG_ 2566779904 Power_Factor_Lagging "canboat type: LOOKUP";
CM_ SG_ 2566780160 Real_Power "canboat type: POWER_FIX32_OFFSET";
CM_ SG_ 2566780160 Apparent_Power "canboat type: POWER_FIX32_VA_OFFSET";
CM_ SG_ 2566780416 Line_Line_AC_RMS_Voltage "canboat type: VOLTAGE_UFIX16_V";
CM_ SG_ 2566780416 Line_Neutral_AC_RMS_Voltage "canboat type: VOLTAGE_UFIX16_V";
CM_ SG_ 2566780416 AC_Frequency "canboat type: FREQUENCY_UFIX16";
CM_ SG_ 2566780416 AC_RMS_Current "canboat type: CURRENT_UFIX16_A";
CM_ SG_ 2566780672 Reactive_Power "canboat type: POWER_FIX32_VAR_OFFSET";
CM_ SG_ 2566780672 Power_factor "canboat type: UINT16";
CM_ SG_ 2566780672 Power_Factor_Lagging "canboat type: LOOKUP";
CM_ SG_ 2566780928 Real_Power "canboat type: POWER_FIX32_OFFSET";
CM_ SG_ 2566780928 Apparent_Power "canboat type: POWER_FIX32_VA_OFFSET";
CM_ SG_ 2566781184 Line_Line_AC_RMS_Voltage "canboat type: VOLTAGE_UFIX16_V";
CM_ SG_ 2566781184 Line_Neutral_AC_RMS_Voltage "canboat type: VOLTAGE_UFIX16_V";
CM_ SG_ 2566781184 AC_Frequency "canboat type: FREQUENCY_UFIX16";
CM_ SG_ 2566781184 AC_RMS_Current "canboat type: CURRENT_UFIX16_A";
CM_ SG_ 2566781440 Total_Energy_Export "canboat type: ENERGY_UINT32";
CM_ SG_ 2566781440 Total_Energy_Import "canboat type: ENERGY_UINT32";
CM_ SG_ 2566781696 Reactive_Power "canboat type: POWER_FIX32_VAR_OFFSET";
CM_ SG_ 2566781696 Power_factor "canboat type: UINT16";
CM_ SG_ 2566781696 Power_Factor_Lagging "canboat type: LOOKUP";
CM_ SG_ 2566781952 Real_Power "canboat type: POWER_FIX32_OFFSET";
CM_ SG_ 2566781952 Apparent_Power "canboat type: POWER_FIX32_VA_OFFSET";
CM_ SG_ 2566782208 Line_Line_AC_RMS_Voltage "canboat type: VOLTAGE_UFIX16_V";
CM_ SG_ 2566782208 Line_Neutral_AC_RMS_Voltage "canboat type: VOLTAGE_UFIX16_V";
CM_ SG_ 2566782208 AC_Frequency "canboat type: FREQUENCY_UFIX16";
CM_ SG_ 2566782208 AC_RMS_Current "canboat type: CURRENT_UFIX16_A";
CM_ SG_ 2566782464 Reactive_Power "canboat type: POWER_FIX32_VAR_OFFSET";
CM_ SG_ 2566782464 Power_factor "canboat type: UINT16";
CM_ SG_ 2566782464 Power_Factor_Lagging "canboat type: LOOKUP";
CM_ SG_ 2566782720 Real_Power "canboat type: POWER_FIX32_OFFSET";
CM_ SG_ 2566782720 Apparent_Power "canboat type: POWER_FIX32_VA_OFFSET";
CM_ SG_ 2566782976 Line_Line_AC_RMS_Voltage "canboat type: VOLTAGE_UFIX16_V";
CM_ SG_ 2566782976 Line_Neutral_AC_RMS_Voltage "canboat type: VOLTAGE_UFIX16_V";
CM_ SG_ 2566782976 AC_Frequency "canboat type: FREQUENCY_UFIX16";
CM_ SG_ 2566782976 AC_RMS_Current "canboat type: CURRENT_UFIX16_A";
CM_ SG_ 2566783232 Reactive_Power "canboat type: POWER_FIX32_VAR_OFFSET";
CM_ SG_ 2566783232 Power_factor "canboat type: UINT16";
CM_ SG_ 2566783232 Power_Factor_Lagging "canboat type: LOOKUP";
CM_ SG_ 2566783488 Real_Power "canboat type: POWER_FIX32_OFFSET";
CM_ SG_ 2566783488 Apparent_Power "canboat type: POWER_FIX32_VA_OFFSET";
CM_ SG_ 2566783744 Line_Line_AC_RMS_Voltage "canboat type: VOLTAGE_UFIX16_V";
CM_ SG_ 2566783744 Line_Neutral_AC_RMS_Voltage "canboat type: VOLTAGE_UFIX16_V";
CM_ SG_ 2566783744 AC_Frequency "canboat type: FREQUENCY_UFIX16";
CM_ SG_ 2566783744 AC_RMS_Current "canboat type: CURRENT_UFIX16_A";
CM_ SG_ 2566784000 Reactive_Power "canboat type: POWER_FIX32_VAR_OFFSET";
CM_ SG_ 2566784000 Power_factor "canboat type: UINT16";
CM_ SG_ 2566784000 Power_Factor_Lagging "canboat type: LOOKUP";
CM_ SG_ 2566784256 Real_Power "canboat type: POWER_FIX32_OFFSET";
CM_ SG_ 2566784256 Apparent_Power "canboat type: POWER_FIX32_VA_OFFSET";
CM_ SG_ 2566784512 Line_Line_AC_RMS_Voltage "canboat type: VOLTAGE_UFIX16_V";
CM_ SG_ 2566784512 Line_Neutral_AC_RMS_Voltage "canboat type: VOLTAGE_UFIX16_V";
CM_ SG_ 2566784512 AC_Frequency "canboat type: FREQUENCY_UFIX16";
CM_ SG_ 2566784512 AC_RMS_Current "canboat type: CURRENT_UFIX16_A";
CM_ SG_ 2566784768 Engine_Exhaust_Manifold_Bank_2_Temperature_1 "SPN 2433; canboat type: TEMPERATURE_UFIX16_J1939";
CM_ SG_ 2566784768 Engine_Exhaust_Manifold_Bank_1_Temperature_1 "SPN 2434; canboat type: TEMPERATURE_UFIX16_J1939";
CM_ SG_ 2566784768 Engine_Exhaust_Manifold_Bank_2_Temperature_2 "SPN 5969; canboat type: TEMPERATURE_UFIX16_J1939";
CM_ SG_ 2566784768 Engine_Exhaust_Manifold_Bank_1_Temperature_2 "SPN 5970; canboat type: TEMPERATURE_UFIX16_J1939";
CM_ SG_ 2566810112 Engine_Oil_Level_Remote_Reservoir "SPN 1380; canboat type: PERCENTAGE_UINT8";
CM_ SG_ 2566810112 Engine_Fuel_Supply_Pump_Intake_Absolute_Pressure "SPN 1381; canboat type: PRESSURE_UINT8_2KPA";
CM_ SG_ 2566810112 Engine_Fuel_Filter__suction_side__Differential_Pressure "SPN 1382; canboat type: PRESSURE_UINT8_2KPA";
CM_ SG_ 2566810112 Engine_Waste_Oil_Reservoir_Level "SPN 3548; canboat type: PERCENTAGE_UINT8";
CM_ SG_ 2566810112 Engine_Oil_Filter_Outlet_Pressure "SPN 3549, 4 kPa per bit; canboat type: NUMBER";
CM_ SG_ 2566810112 Engine_Oil_Priming_Pump_Switch "SPN 3550; canboat type: NUMBER";
CM_ SG_ 2566810112 Engine_Oil_Priming_State "SPN 3551; canboat type: NUMBER";
CM_ SG_ 2566810112 Engine_Oil_Pre_Heated_State "SPN 3552; canboat type: NUMBER";
CM_ SG_ 2566810112 Engine_Coolant_Pre_heated_State "SPN 3553; canboat type: NUMBER";
CM_ SG_ 2566810112 Engine_Ventilation_Status "SPN 3554; canboat type: NUMBER";
CM_ SG_ 2566810112 Fuel_Pump_Primer_Status "SPN 4083; canboat type: NUMBER";
CM_ SG_ 2566810112 Engine_Fuel_Supply_Pump_Intake_Pressure "SPN 7104; canboat type: PRESSURE_UINT8_2KPA";
CM_ SG_ 2566824960 Engine_Oil_Temperature_2 "SPN 1135; canboat type: TEMPERATURE_UFIX16_J1939";
CM_ SG_ 2566824960 Engine_ECU_Temperature "SPN 1136; canboat type: TEMPERATURE_UFIX16_J1939";
CM_ SG_ 2566824960 Engine_Exhaust_Gas_Recirculation_1_Differential_Pressure "SPN 411, 1/128 kPa per bit with a -250 kPa offset; canboat type: NUMBER";
CM_ SG_ 2566824960 Engine_Exhaust_Gas_Recirculation_1_Temperature "SPN 412; canboat type: TEMPERATURE_UFIX16_J1939";
CM_ SG_ 2566825216 Engine_Intake_Manifold_2_Temperature "SPN 1131; canboat type: TEMPERATURE_UINT8_OFFSET";
CM_ SG_ 2566825216 Engine_Intake_Manifold_3_Temperature "SPN 1132; canboat type: TEMPERATURE_UINT8_OFFSET";
CM_ SG_ 2566825216 Engine_Intake_Manifold_4_Temperature "SPN 1133; canboat type: TEMPERATURE_UINT8_OFFSET";
CM_ SG_ 2566825216 Engine_Intake_Manifold_5_Temperature "SPN 1802; canboat type: TEMPERATURE_UINT8_OFFSET";
CM_ SG_ 2566825216 Engine_Intake_Manifold_6_Temperature "SPN 1803; canboat type: TEMPERATURE_UINT8_OFFSET";
CM_ SG_ 2566825472 Engine_Turbocharger_1_Boost_Pressure "SPN 1127, 0.125 kPa per bit; canboat type: NUMBER";
CM_ SG_ 2566825472 Engine_Turbocharger_2_Boost_Pressure "SPN 1128, 0.125 kPa per bit; canboat type: NUMBER";
CM_ SG_ 2566825472 Engine_Turbocharger_3_Boost_Pressure "SPN 1129, 0.125 kPa per bit; canboat type: NUMBER";
CM_ SG_ 2566825472 Engine_Turbocharger_4_Boost_Pressure "SPN 1130, 0.125 kPa per bit; canboat type: NUMBER";
CM_ SG_ 2566828288 Total_ECU_Distance "SPN 1032, 0.125 kilometre per bit; canboat type: NUMBER";
CM_ SG_ 2566828288 Total_ECU_Run_Time "SPN 1033, 0.05 hour per bit; canboat type: NUMBER";
CM_ SG_ 2566831360 Estimated_Percent_Fan_Speed "SPN 975; canboat type: PERCENTAGE_UINT8";
CM_ SG_ 2566831360 Fan_Drive_State "SPN 977; canboat type: NUMBER";
CM_ SG_ 2566831360 Fan_Speed "SPN 1639; canboat type: ROTATION_UFIX16_RPM_HIGHRES";
CM_ SG_ 2566831360 Hydraulic_Fan_Motor_Pressure "SPN 4211; canboat type: PRESSURE_UFIX16_KPA";
CM_ SG_ 2566831360 Hydraulic_Fan_Motor_Pressure_2 "SPN 4212; canboat type: PRESSURE_UINT8_KPA";
CM_ SG_ 2566831616 Engine_Rated_Power "SPN 166, 0.5 kW per bit; canboat type: NUMBER";
CM_ SG_ 2566831616 Engine_Rated_Speed "SPN 189; canboat type: ROTATION_UFIX16_RPM_HIGHRES";
CM_ SG_ 2566831616 Engine_Rotation_Direction "SPN 3669; canboat type: NUMBER";
CM_ SG_ 2566831616 Engine_Intake_Manifold_Pressure_Control_Mode "SPN 5465; canboat type: NUMBER";
CM_ SG_ 2566831616 Crank_Attempt_Count_on_Present_Start_Attempt "SPN 3671; canboat type: NUMBER";
CM_ SG_ 2566834688 Malfunction_Lamp_Status "Fault Lamps; canboat type: BINARY";
CM_ SG_ 2566834688 Red_Stop_Lamp_Status "Fault Lamps; canboat type: BINARY";
CM_ SG_ 2566834688 Amber_Warning_Lamp_Status "Fault Lamps; canboat type: BINARY";
CM_ SG_ 2566834688 Protect_Lamp_Status "Fault Lamps; canboat type: BINARY";
CM_ SG_ 2566834688 field16 "canboat type: NUMBER";
CM_ SG_ 2566838272 Unique_Number "ISO Identity Number; canboat type: BINARY";
CM_ SG_ 2566838272 Manufacturer_Code "canboat type: LOOKUP";
CM_ SG_ 2566838272 Device_Instance_Lower "ISO ECU Instance; canboat type: UNSIGNED_INTEGER";
CM_ SG_ 2566838272 Device_Instance_Upper "ISO Function Instance; canboat type: UNSIGNED_INTEGER";
CM_ SG_ 2566838272 Device_Function "ISO Function; canboat type: INDIRECT_LOOKUP";
CM_ SG_ 2566838272 Device_Class "canboat type: LOOKUP";
CM_ SG_ 2566838272 System_Instance "ISO Device Class Instance; canboat type: UNSIGNED_INTEGER";
CM_ SG_ 2566838272 Industry_Code "canboat type: LOOKUP";
CM_ SG_ 2566838272 New_Source_Address "canboat type: UINT8";
CM_ SG_ 2566839040 Engine_Fuel_Injection_Control_Pressure "SPN 164, 1/256 MPa per bit; canboat type: NUMBER";
CM_ SG_ 2566839040 Engine_Fuel_1_Injector_Metering_Rail_1_Pressure "SPN 157, 1/256 MPa per bit; canboat type: NUMBER";
CM_ SG_ 2566839040 Engine_Fuel_1_Injector_Timing_Rail_1_Pressure "SPN 156, 1/256 MPa per bit; canboat type: NUMBER";
CM_ SG_ 2566839040 Engine_Fuel_1_Injector_Metering_Rail_2_Pressure "SPN 1349, 1/256 MPa per bit; canboat type: NUMBER";
CM_ SG_ 2566839296 Engine_Total_Idle_Fuel_Used "SPN 236, 0.5 litre per bit; canboat type: VOLUME_UFIX32_HL";
CM_ SG_ 2566839296 Engine_Total_Idle_Hours "SPN 235, 0.05 hour per bit; canboat type: DURATION_UFIX32_J1939_HOURS";
CM_ SG_ 2566840064 Nominal_Friction___Percent_Torque "SPN 514; canboat type: PERCENTAGE_INT8";
CM_ SG_ 2566840064 Engine_s_Desired_Operating_Speed "SPN 515; canboat type: ROTATION_UFIX16_RPM_HIGHRES";
CM_ SG_ 2566840064 Engine_s_Desired_Operating_Speed_Asymmetry_Adjustment "SPN 519; canboat type: NUMBER";
CM_ SG_ 2566840064 Estimated_Engine_Power_Loss___Accessories "SPN 2978; canboat type: PERCENTAGE_UINT8";
CM_ SG_ 2566841600 Engine_Total_Hours_of_Operation "SPN 247, 0.05 hours per bit; canboat type: DURATION_UFIX32_J1939_HOURS";
CM_ SG_ 2566841600 Engine_Total_Revolutions "SPN 249, 1000 revolutions per bit; canboat type: NUMBER";
CM_ SG_ 2566842624 Engine_Trip_Fuel "SPN 182, 0.5 litre per bit; canboat type: VOLUME_UFIX32_HL";
CM_ SG_ 2566842624 Engine_Total_Fuel_Used "SPN 250, 0.5 litre per bit; canboat type: VOLUME_UFIX32_HL";
CM_ SG_ 2566843904 Engine_Coolant_Temp "SPN 110; canboat type: TEMPERATURE_UINT8_OFFSET";
CM_ SG_ 2566843904 Engine_Fuel_Temp_1 "SPN 174; canboat type: TEMPERATURE_UINT8_OFFSET";
CM_ SG_ 2566843904 Engine_Oil_Temp_1 "SPN 175, 0.03125 K per bit with a -273 K offset; canboat type: TEMPERATURE_UFIX16_J1939";
CM_ SG_ 2566843904 Engine_Turbocharger_Oil_Temp "SPN 176; canboat type: TEMPERATURE_UFIX16_J1939";
CM_ SG_ 2566843904 Engine_Intercooler_Temp "SPN 52; canboat type: TEMPERATURE_UINT8_OFFSET";
CM_ SG_ 2566843904 Engine_Intercooler_Thermostat_Opening "SPN 1134; canboat type: PERCENTAGE_UINT8";
CM_ SG_ 2566844928 Fuel_Rate "SPN 183, 0.05 l/h per bit; canboat type: VOLUMETRIC_FLOW_UFIX16_J1939";
CM_ SG_ 2566844928 Instantaneous_Fuel_Economy "SPN 184, 1/512 km/l per bit; canboat type: DISTANCE_PER_VOLUME_UFIX16_J1939";
CM_ SG_ 2566844928 Average_Fuel_Economy "SPN 185, 1/512 km/l per bit; canboat type: DISTANCE_PER_VOLUME_UFIX16_J1939";
CM_ SG_ 2566844928 Throttle_Position "SPN 51; canboat type: PERCENTAGE_UINT8";
CM_ SG_ 2566845696 Barometric_Pressure "canboat type: PRESSURE_UINT8_KPA";
CM_ SG_ 2566845952 Particulate_Trap_Inlet_Pressure "SPN 81; canboat type: PRESSURE_UINT8_2KPA";
CM_ SG_ 2566845952 Boost_Pressure "SPN 102; canboat type: PRESSURE_UINT8_2KPA";
CM_ SG_ 2566845952 Intake_Manifold_Temp "SPN 105; canboat type: TEMPERATURE_UINT8_OFFSET";
CM_ SG_ 2566845952 Air_Inlet_Pressure "SPN 106; canboat type: PRESSURE_UINT8_2KPA";
CM_ SG_ 2566845952 Air_Filter_Differential_Pressure "SPN 107, 0.05 kPa per bit; canboat type: PRESSURE_UINT8_005KPA";
CM_ SG_ 2566845952 Exhaust_Gas_Temperature "SPN 173; canboat type: TEMPERATURE_UFIX16_J1939";
CM_ SG_ 2566845952 Coolant_Filter_Differential_Pressure "SPN 112, 0.5 kPa per bit; canboat type: PRESSURE_UINT8_KPA";
CM_ SG_ 2566846208 Battery_Voltage "canboat type: VOLTAGE_UFIX16_50MV";
CM_ SG_ 2566846464 Transmission_Clutch_1_Pressure "SPN 123, 16 kPa per bit; canboat type: NUMBER";
CM_ SG_ 2566846464 Transmission_Oil_Level_1 "SPN 124; canboat type: PERCENTAGE_UINT8";
CM_ SG_ 2566846464 Transmission_Filter_Differential_Pressure "SPN 126; canboat type: PRESSURE_UINT8_2KPA";
CM_ SG_ 2566846464 Transmission_1_Oil_Pressure "SPN 127, 16 kPa per bit; canboat type: NUMBER";
CM_ SG_ 2566846464 Transmission_1_Oil_Temperature_1 "SPN 177; canboat type: TEMPERATURE_UFIX16_J1939";
CM_ SG_ 2566846464 Transmission_Oil_Level_1_High___Low "SPN 3027, 0.5 litre per bit with a -62.5 litre offset; canboat type: NUMBER";
CM_ SG_ 2566846464 Transmission_Oil_Level_1_Countdown_Timer "SPN 3028; canboat type: NUMBER";
CM_ SG_ 2566846464 Transmission_Oil_Level_1_Measurement_Status "SPN 3026; canboat type: NUMBER";
CM_ SG_ 2566848512 Manufacturer_Code "canboat type: LOOKUP";
CM_ SG_ 2566848512 Industry_Code "canboat type: LOOKUP";
CM_ SG_ 2566848512 Data "canboat type: BINARY";
CM_ SG_ 2582446080 Data "canboat type: BINARY";
CM_ SG_ 2582577152 Manufacturer_Code "canboat type: LOOKUP";
CM_ SG_ 2582577152 Industry_Code "canboat type: LOOKUP";
CM_ SG_ 2582577152 Data "canboat type: BINARY";
CM_ SG_ 2582642688 Data "canboat type: BINARY";
CM_ SG_ 2583625728 Data "canboat type: BINARY";
CM_ SG_ 2566844672 Two_Speed_Axle_Switch "SPN 1185, bits 1-2; canboat type: NUMBER";
CM_ SG_ 2566844672 Parking_Brake_Switch "SPN 597, bits 3-4; canboat type: NUMBER";
CM_ SG_ 2566844672 Cruise_Control_Pause_Switch "SPN 3885, bits 5-6; canboat type: NUMBER";
CM_ SG_ 2566844672 Wheel_Based_Vehicle_Speed "SPN 84: bits 9-24 (bytes 1-2), little-endian 16-bit, resolution 1/256 km/h per bit, offset 0 — SAE J1939-71; canboat type: NUMBER";
CM_ SG_ 2566844672 Cruise_Control_Set_Speed "SPN 1184: bits 33-40 (byte 4), 1 km/h per bit; canboat type: NUMBER";
CM_ SG_ 2566844672 PTO_State "SPN 73, bits 57-64 (byte 7); canboat type: NUMBER";
VAL_ 2566779904 Power_Factor_Lagging 0 "Leading" 1 "Lagging" 2 "Error" ;
VAL_ 2566780672 Power_Factor_Lagging 0 "Leading" 1 "Lagging" 2 "Error" ;
VAL_ 2566781696 Power_Factor_Lagging 0 "Leading" 1 "Lagging" 2 "Error" ;
VAL_ 2566782464 Power_Factor_Lagging 0 "Leading" 1 "Lagging" 2 "Error" ;
VAL_ 2566783232 Power_Factor_Lagging 0 "Leading" 1 "Lagging" 2 "Error" ;
VAL_ 2566784000 Power_Factor_Lagging 0 "Leading" 1 "Lagging" 2 "Error" ;
VAL_ 2566838272 Manufacturer_Code 0 "For experimental or developmental use only." 1 "Bendix Commercial Vehicle Systems LLC (formerly Allied Signal Inc.)" 2 "Allison Transmission, Inc." 3 "Ametek, US Gauge Division" 4 "Ametek-Dixson" 5 "AMP Inc." 6 "Berifors Electronics AB" 7 "Case Corp." 8 "Caterpillar Inc." 9 "Chrysler Corp." 10 "Cummins Inc (formerly Cummins Engine Co)" 11 "Dearborn Group Inc." 12 "Deere & Company, Precision Farming" 13 "Delco Electronics" 14 "Detroit Diesel Corporation" 15 "DICKEY-john Corporation" 16 "Eaton Corp" 17 "Eaton Corp, Corp Res & Dev" 18 "Eaton Corp, Transmission Div." 19 "Eaton Corp. Trucking Info Services" 20 "Eaton Ltd" 21 "Echlin Inc., Midland Brake Inc." 22 "Ford Motor Co., Electronic Concepts & Systems" 23 "Ford Motor Co., Heavy Truck" 24 "Ford Motor Co., Vehicle Controls" 25 "Daimler Trucks North America LLC (formerly Freightliner LLC)" 26 "General Motors Corp, Service Technology Grp" 27 "GMC" 28 "Grote Ind. Inc." 29 "Hino Motors Ltd." 30 "Isuzu Motors Ltd" 31 "J Pollak Corp" 32 "Jacobs Vehicle Systems" 33 "John Deere" 34 "Kelsey Hayes Co." 35 "Kenworth Truck Co." 36 "Lucas Ind." 37 "Mack Trucks Inc." 38 "Micro Processor Systems Inc." 39 "Microfirm Inc." 40 "Motorola AIEG Inc." 41 "Motorola Inc." 42 "International Truck and Engine Corporation - Engine Electronics (formerly Navistar Intl Trans Co., Engine Electronics)" 43 "International Truck and Engine Corporation - Vehicle Electronics (formerly Navistar Intl Trans Corp.)" 44 "Nippondenso Co. Ltd." 45 "PACCAR" 46 "Noregon Systems, LLC (formerly Noregon Systems, Inc)" 47 "Phillips Semiconductor" 48 "Pollak Alphabet" 49 "RE America Inc." 50 "Robert Bosch Corp" 51 "Robert Bosch GmbH" 52 "Meritor Automotive, Inc. (formerly Rockwell Automotive)" 53 "Continental Automotive Systems US, Inc. (formerly Rockwell Land Transportation)" 54 "Meritor Wabco" 55 "Ryder System Inc." 56 "SAIC" 57 "Danfoss (formerly Sauer Sundstrand Co, then Sauer-Danfoss Co)" 58 "SPX Corporation, OTC Div" 59 "VES Inc." 60 "Volvo Trucks North America Inc." 61 "Volvo Truck Corp." 62 "Wabco" 63 "ZF Industries Inc." 64 "Unused (formerly SpectraPrecision Laserplane, then SpectraPhysics)" 65 "MAN Nutzfahrzeuge AG" 66 "John Deere Construction Equipment Division" 67 "John Deere Coffeyville Works (formerly Funk Manufacturing Company)" 68 "Scania" 69 "Trimble Navigation" 70 "Flex-coil Limited" 71 "Vansco Electronics Ltd." 72 "Sisu Corporation" 73 "LeTourneau, Inc." 74 "Eaton Axle-Brake Division" 75 "Deere & Co, Agricultural Division" 76 "unused (formerly Deere & Co, Construction Division)" 77 "Deere Power Systems Group" 78 "Frank W. Murphy Manufacturing, Inc" 79 "Daimler Benz AG - Engine Division (PBM)" 80 "Twin Disc, Inc." 81 "Fire Research Corp." 82 "Bobcat/Ingersoll-Rand (formerly Melroe/Ingersoll-Rand)" 83 "Bendix VORAD Technologies (formerly Eaton VORAD Technologies)" 84 "New Holland UK Limited" 85 "Kohler Co" 86 "C. E. Niehoff & Company" 87 "J.C. Bamford Excavators Ltd (JCB)" 88 "Hemisphere GPS Inc (formerly Satloc Precision GPS)" 89 "Kverneland Group, Electronics Division" 90 "Knorr-Bremse SfN GmbH" 91 "BSG Bodensee Steuergeraete GmbH" 92 "Ag-Chem Equipment Co., Inc." 93 "Perkins Engines Company Ltd." 94 "CNH Industrial N.V. (formerly CNH Global N.V.)" 95 "Pacific Insight Electronics Corp." 96 "Mech@tronic IT GmbH" 97 "Ag Leader Technology, Inc." 98 "PTx Trimble (formerly Mueller-Elektronik GmbH & Co)" 99 "International Transmissions Ltd (ITL)" 100 "VDO Technik AG" 101 "Sensoria" 102 "AGCO (formerly AGCO GmbH & Co.)" 103 "CLAAS E-Systems GmbH (formerly CLAAS E-Systems KGaA mbH & Co. KG)" 104 "CLAAS KGaA mbH (formerly CLAAS Selbstfahrende Erntemaschinen GmbH)" 105 "Kiepe Elektrik GmbH & Co. KG" 106 "BAE Systems Controls, Inc." 107 "Grimme Landmaschinen GmbH & Co. KG" 108 "PTx Trimble (formerly WTK-Elecktronik GmbH, now a duplicate entry; use MFR ID 98)" 109 "TeeJet Technologies Denmark (formerly LH Technologies ApS)" 110 "EPIQ Sensor-Nite" 111 "Bernard Krone Holding SE & Co. KG (formerly Maschinenfabrik Bernard Krone GmbH)" 112 "MECALAC" 113 "Stress-Tek, Inc." 114 "EControls, Inc." 115 "NACCO Materials Handling Group, Inc." 116 "BEELINE Technologies" 117 "HUSCO International" 118 "Intron GmbH" 119 "IntegriNautics" 120 "RDS Technology Ltd" 121 "HED (Hydro Electronic Devices, Inc.)" 122 "FG Wilson (Engineering) Limited" 123 "Basler Electric" 124 "Hydac Electronic" 125 "Nevada Automotive Test Center" 126 "Driver Tech" 127 "Holland USA" 128 "Gerhard Duecker GmbH & Co. KG" 129 "OMNEX Control Systems Inc." 130 "Nido - Universal Machines B.V." 131 "ITT Industries" 132 "Mulag-Fahrzeugwerk" 133 "Bucher Schoerling GmbH" 134 "Iris Technology Ltd" 135 "Airmar Technology Corporation" 136 "Komatsu Ltd" 137 "Maretron" 138 "Georg Fritzmeier GmbH & Co. KG" 139 "Caterpillar Trimble Control Technologies (CTCT), LLC" 140 "Lowrance Electronics, Inc." 141 "Thales Navigation Ltd." 142 "TRW Automotive (Commercial Steering Systems)" 143 "W. Gmeiner GmbH & Co." 144 "Mercury Marine" 145 "MurCal Controls" 146 "Maxima Technologies" 147 "Nautibus electronic GmbH" 148 "Blue Water Data, Inc." 149 "Holset" 150 "Fleetguard" 151 "Raven Industries, Inc." 152 "elobau GmbH & Co. KG" 153 "Woodward, Industrial Controls Division" 154 "Westerbeke Corporation" 155 "Vetronix Corporation" 156 "ITT Industries - Cannon" 157 "ISSPRO Inc." 158 "Firestone Industrial Products Company" 159 "NTech Industries Inc" 160 "Nido" 161 "Offshore Systems (UK) Ltd" 162 "Axiomatic Technologies" 163 "BRP Inc." 164 "MTU Friedrichshafen GmbH (formerly DaimlerChrysler Off-Highway)" 165 "CPAC Systems AB" 166 "John Deere Electronic Solutions (formerly Phoenix International)" 167 "JLG Industries Inc" 168 "Xantrex" 169 "Marlin Technologies Inc." 170 "Computronics Corporation Ltd." 171 "Topcon Electronics GmbH & Co. KG (formerly Wachendorff Elektronik GmbH & Co. KG)" 172 "Yanmar Co., Ltd. (formerly Yanmar Marine USA)" 173 "Ryeso, Inc." 174 "AB Volvo Penta" 175 "Veris Technologies, Inc." 176 "Moritz Aerospace" 177 "Diagnostic Systems Associates" 178 "Continental Automotive GmbH (formerly Siemens VDO Automotive AG)" 179 "TeeJet Technologies Springfield (formerly Midwest Technologies Illinois, LLC)" 180 "Smart Power Systems" 181 "Coretronics, Inc." 182 "Vehicle Systems Engineering B.V." 183 "KDS Controls, Inc" 184 "EIA Electronics" 185 "Beede Electrical Instrument Company" 186 "Altronic, Inc" 187 "Air-Weigh" 188 "EMP Corp" 189 "QUALCOMM" 190 "Hella KGaA Hueck & Co" 191 "XRS Corporation (formerly XATA Corporation)" 192 "Floscan" 193 "Jeppesen Marine" 194 "TriMark Corporation" 195 "General Engine Products" 196 "LEMKEN GmbH & Co KG" 197 "Mechron Power Systems" 198 "Mystic Valley Communications" 199 "ACTIA Group (formerly Actia Corp)" 200 "MGM Brakes" 201 "Disenos y Tecnologia S.A." 202 "Curtis Instruments, Inc" 203 "MILtronik GmbH" 204 "The Morey Corporation" 205 "SmarTire Systems Inc" 206 "port GmbH" 207 "Otto Engineering" 208 "Drew Technologies, Inc" 209 "Bell Equip. Co. SA (PTY) LTD" 210 "Iteris, Inc." 211 "DNA Group" 212 "Sure Power Industries, Inc" 213 "CNH Belgium N.V." 214 "MC elettronica Srl" 215 "Aetna Engineering/Fireboy-Xintex" 216 "Paneltronics Inc." 217 "RM Michaelides Software & Elektronik GmbH" 218 "Gits Manufacturing Company" 219 "Cat OEM Solutions" 220 "Beede Electrical Instrument Company, Inc" 221 "SiE" 222 "Generac Power Systems, Inc." 223 "Vaueo Retarder Co., Ltd." 224 "EMMI Network, S.L." 225 "SKF" 226 "Monaco Coach Corporation" 227 "Lykketronic A/S" 228 "Unused (formerly ZF Marine Electronics)" 229 "Garmin International Inc." 230 "Saucon Technologies" 231 "Topcon Positioning Systems, Inc." 232 "TSD Integrated Controls" 233 "Yacht Monitoring Solutions Inc." 234 "Mondial electronic GmbH" 235 "SailorMade Marine Telemetry - Tetra Technology Ltd." 236 "NORAC Systems International Inc" 237 "Agtron Enterprises Inc" 238 "ZF Friedrichshafen AG" 239 "May & Scofield Ltd" 240 "Vanair Mfg" 241 "Schneider Automation SAS" 242 "Kokusandenki Co. Ltd" 243 "eRide, Inc." 244 "Techno-Matic" 245 "Capstan Ag Systems, Inc." 246 "Class 1, Inc" 247 "ePULSE" 248 "Cooper Standard Automotive Active Systems Group" 249 "Schaltbau GmbH" 250 "Kuhn Group" 251 "German Agricultural Society, Test Center (DLG)" 252 "Sensor-Technik Wiedemann GmbH" 253 "Mobile Control Systems" 254 "GE Sensing" 255 "MEAS France" 256 "Tyco Electronics AMP" 257 "Honda Motor Co., Ltd" 258 "ARAG" 259 "Bucher Automation AG (formerly Jetter AG)" 260 "Reichhardt GmbH Steuerungstechnik" 261 "Red Dot Corporation" 262 "HydraForce, Inc" 263 "IMMI" 264 "Autolync" 265 "MTS Sensor Technologie GmbH" 266 "International Thermal Research Ltd" 267 "Red Lion Controls, Inc" 268 "Accurate Technologies" 269 "Saft America Inc., Space & Defense Division" 270 "Tennant" 271 "Cole Hersee" 272 "Gross Mechanical Laboratories, Inc" 273 "Active Research Limited" 274 "LTW Technology Co., LTD" 275 "Navico Egersund AS" 276 "Aqua-Hot Heating Systems" 277 "LHP Telematics" 278 "Takata Electronics" 279 "Geometris LP" 280 "Leica Geosystems Pty Ltd" 281 "Precision Governors LLC" 282 "Medallion Instrumentation Systems" 283 "CWF Hamilton & Co Ltd" 284 "Mobile Tech Chile" 285 "Sea Recovery Corp" 286 "Coelmo srl" 287 "NTech Industries, Inc" 288 "Mitsubishi FUSO Truck & Bus Corp." 289 "Watlow" 290 "Kuebler GmbH" 291 "Groeneveld Transport Efficiency BV" 292 "IKUSI - Angel Iglesias S.A." 293 "Spyder Controls Corp." 294 "Grayhill Inc." 295 "BEP Marine" 296 "micro dynamics GmbH" 297 "Zonar Systems Inc" 298 "Holley Performance" 299 "Rauch" 300 "Systron Donner Automotive" 301 "Parker Hannifin (UK) Ltd FDE group" 302 "Nissin Kogyo Co., LTD" 303 "CTS Corporation" 304 "EmpirBus AB" 305 "NovAtel Inc" 306 "Sleipner Motor AB" 307 "MAS Technologies" 308 "Cyntrx" 309 "Krauss-Maffei Wegmann GmbH & Co. KG" 310 "TECNORD srl" 311 "Patrick Power Products" 312 "Lectronix, Inc." 313 "Ilmor Engineering, Inc." 314 "CSM GmbH" 315 "Icom Incorporated" 316 "ITT Flow Control" 317 "Navtronics Bvba" 318 "SAT Plan" 319 "Cadec Global" 320 "Miedema Landbouwwerktuigenfabriek B.V." 321 "Ultra Electronics, Electrics" 322 "MICHENKA s.r.o." 323 "Mobileye Vision Technologies Ltd." 324 "Snap-on Diagnostics" 325 "ASM Automation Sensorik Messtechnik GmbH" 326 "Akron Brass Company" 327 "Sonceboz SA" 328 "Qwerty Electronik AB" 329 "Deif A/S" 330 "Kidde Aerospace and Defense" 331 "Horton, Inc." 332 "HWH Corporation" 333 "Link Manufacturing, Ltd. (formerly Hadley Products Corporation)" 334 "Takata-Petri AG" 335 "Evo Electric Ltd" 336 "APE s.r.o." 337 "Carraro S.p.A." 338 "GRAF-SYTECO" 339 "Competence Center ISOBUS e.V." 340 "Continental AG" 341 "Boning GmbH & Co" 342 "THOMAS MAGNETE GmbH" 343 "Baumer Group" 344 "Parvus Corporation" 345 "Korean Maritime University" 346 "Control Solutions" 347 "Honeywell" 348 "Amazonen Werke H. Dreyer" 349 "Suonentieto" 350 "Noris Marine Systems GmbH & Co KG" 351 "Thrane & Thrane" 352 "SAME DEUTZ-FAHR GROUP S.p.A." 353 "Hegemon Electronics, Inc." 354 "Junkkari OY" 355 "Mastervolt International B.V." 356 "Fischer Panda Generators, Inc" 357 "Hardi International A/S" 358 "Victron Energy B.V." 359 "Ludwig Bergmann GmbH" 360 "HJS Emission Technology GmbH & Co KG (formerly HJS Fahrzeugtechnik GmbH & Co KG)" 361 "InMach" 362 "Poettinger Landtechnik GmbH (formerly Alois Poettinger Maschinenfabrik GmbH)" 363 "BEI Duncan" 364 "OEM Controls Inc." 365 "Digi-Star, LLC" 366 "Viewnyx Corp." 367 "Fliegl Agrartechnik" 368 "HANSENHOF_electronic" 369 "Power Torque Engineering Ltd" 370 "Rolls-Royce Marine AS" 371 "Heinzmann GmbH & Co. KG" 372 "Delphi" 373 "Electronic Design Inc." 374 "Northern Lights, Inc." 375 "Williams Controls Inc." 376 "Quake Global" 377 "ifm electronic gmbh" 378 "Glendinning Marine Products" 379 "Yamabiko Corporation" 380 "Suntech International Ltd." 381 "B & G" 382 "National Agriculture and Food Research Organization" 383 "MCL Industries" 384 "Camano Light" 385 "Johnson Outdoor Marine Electronics" 386 "JLG Automation BVBA" 387 "Orscheln Products, LLC" 388 "Innomatix, LLC" 389 "Benchmark Electronics, Minnesota Division" 390 "Partech Inc." 391 "Electronic Design for Industry, Inc" 392 "Tianyuan Technology Co Ltd." 393 "Harvest Tec, Inc" 394 "Capi 2 Nederland B.V." 395 "GENTEC S.R.L." 396 "Beyond Measure" 397 "Sanyo-kiki Co Ltd." 398 "Hilite International" 399 "ISEKI & Co., Ltd." 400 "Livorsi Marine" 401 "Torqeedo GmbH" 402 "Simma Software, Inc." 403 "Trackwell ADS, Inc." 404 "Com Nav Marine Ltd" 405 "Wema System AS" 406 "Vecima Networks Inc." 407 "Comtech Mobile Datacom" 408 "Corvus Energy Ltd." 409 "Transfluid S.r.L." 410 "COBO S.p.A. Divisione 3B6" 411 "Hy-Drive Technologies Ltd." 412 "WebTech Wireless Inc." 413 "Datapross Nijbroek bv" 414 "Cattron Group International" 415 "Valid Manufacturing Ltd." 416 "Kubota Corporation" 417 "KZValve" 418 "Intellistick Inc" 419 "Fusion Electronics Ltd" 420 "Vermeer Corporation, ACS Group" 421 "Vertex Standard Co, Ltd" 422 "True Heading AB" 423 "BSM Wireless, Inc." 424 "Odyne LLC" 425 "Methode Electronics Inc, MDI" 429 "Rota Engineering Ltd." 430 "Auteq Telematica S.A." 431 "Tohatsu Corporation" 432 "S&A Systems, Inc." 433 "Rowe Electronics" 434 "Stored Energy Systems" 435 "Zunhammer GmbH" 436 "Kinze Manufacturing" 437 "Digital Yacht Limited" 438 "Comar Systems Ltd" 439 "HD Hyundai (formerly Hyundai Heavy Industries)" 440 "Cummins Power Generation" 441 "PTG Reifendruckregelsysteme GmbH" 442 "HORSCH Maschinen SE & Co. KG (formerly HORSCH Maschinen GmbH)" 443 "SignalQuest, Inc." 444 "ITT Power Solutions" 445 "KAT MECHATRONIC, Electronic Product Division" 446 "CertTech, L.L.C." 447 "Great Plains Mfg." 448 "Stanadyne Corporation, Electronics Systems" 449 "Polaris Industries Inc" 450 "Dycor Technologies Ltd." 451 "Parker Hannifin Corp" 452 "WIKA Alexander Wiegand SE & Co. KG" 453 "Cooper Bussmann" 454 "NGK Spark Plug Co. Ltd" 455 "ADZ NAGANO GmbH" 456 "General Kinetics" 457 "RUSELPROM-ElectricDrive Ltd" 458 "Control Solutions, Inc." 459 "Alltek Marine Electronics Corp" 460 "San Giorgio S.E.I.N." 461 "HAWE Hydraulik SE" 462 "IHI Shibaura Machinery Corporation" 463 "PROBOTIQ" 464 "Leach International Corporation" 465 "Ashcroft Inc" 466 "Veethree Electronics and Marine LLC" 467 "Lely Industries N.V." 468 "Tyco Fire Protection Products" 469 "RA Consulting GmbH" 470 "SI-TEX Marine Electronics" 471 "Sea Cross Marine AB" 472 "Tenneco Inc." 473 "Boss Industries, Inc." 474 "Persen Technologies Inc." 475 "GME" 476 "Hummingbird Marine Electronics" 477 "OilQuick AB" 478 "OceanSat B.V." 479 "Vapor Bus International" 480 "EnerDel, Inc." 481 "Chetco Digital Instruments" 482 "Tricon Electronics" 483 "Valeo" 484 "Headsight Inc." 485 "MATT automotive" 486 "Westport Innovations Inc." 487 "DSE Test Solutions A/S" 488 "The Charles Machine Works, Inc." 489 "Appareo Systems, LLC" 490 "QuikQ" 491 "Penny and Giles Ltd" 492 "Inergy Automotive Systems" 493 "Watcheye" 494 "Synerject" 495 "HOLMER Maschinenbau GmbH" 496 "W. Gessmann GmbH" 497 "SENTRON Sistemas Embarcados" 498 "Innovative Design Solutions, Inc." 499 "LCJ Capteurs" 500 "Oxbo International Corporation" 501 "Agrotronix S.A." 502 "Attwood Corporation" 503 "Naviop S.R.L." 504 "Vesper Marine" 505 "Yetter Farm Equipment" 506 "IHI STAR Machinery Corporation" 507 "ISOBUS Test Center" 508 "Transtech Innovations" 509 "MOTORTECH GmbH" 510 "Marinesoft Co. Ltd" 511 "Sulky" 512 "Inpower LLC" 513 "Precision Technology" 514 "DISTek Integration, Inc." 515 "GINAF Trucks Nederland B.V." 516 "AVAT Automation GmbH" 517 "Noland Engineering" 518 "Transas USA Inc." 519 "Peeters Landbouwmachines b.v." 520 "Trapeze" 521 "Clever Devices Ltd." 522 "Nebraska Tractor Test Laboratory" 523 "Reggio Emilia Innovazione" 524 "Vomax Instrumentation Pty. Ltd." 525 "Rust Sales INC" 526 "LOFA Industries, Inc" 527 "GKN Walterscheid GmbH" 528 "Hoganas AB, Electric Drive Systems" 529 "National Instruments Korea" 530 "NMEA" 531 "Genge & Thoma AG" 532 "Onwa Marine Electronics Co Ltd." 533 "Doran Manufacturing, LLC" 534 "Webasto Thermo & Comfort SE" 535 "MOTORPAL, a.s." 536 "SSI Technologies" 537 "Schrader Electronics Ltd." 538 "Crop Ventures, Inc." 539 "Mobileview" 540 "Dinex A/S" 541 "Total Fire Systems, Inc." 542 "Dinamica Generale s.p.a." 543 "BAUER Maschinen GmbH" 544 "Au Group Electronics" 545 "GS Global Resources (formerly GS Hydraulics)" 546 "Maruyama Mfg Co, Inc." 547 "Thomson Linear LLC" 548 "TM4 Inc." 549 "ROAD Deutschland GmbH" 550 "SUN-A Corporation" 551 "Wexler CSD Ltd." 552 "Matsuyama Plow Mfg Co, Ltd" 553 "KIB Electronics" 554 "iris-GmbH infrared & intelligent sensors" 555 "Sasaki Corporation" 556 "HD Hyundai Infracore Norway (formerly Doosan Infracore Norway)" 557 "Rockson Automation GmbH" 558 "Davis Instruments Corp." 559 "Four Peaks Navigation" 560 "Iowa State University, Agricultural and Biosystems Engineering" 561 "b-plus GmbH" 562 "Bombardier Transportation GmbH" 563 "LOHR Sistemas Eletronicos LTDA" 564 "Auto Power Electronic" 565 "Micro-Trak Systems, Inc." 566 "Geode Technology, Inc." 567 "Lithiumstart LLC" 568 "Makersan Ltd. Co." 569 "LORD MicroStrain Sensing Systems" 570 "frenzel + berg electronic GmbH & Co. KG" 571 "Marinecraft Co., Ltd." 572 "Fasse Valves" 573 "Orolia Ltd" 574 "Vishay Precision Group" 575 "Lytx" 576 "Vectia" 577 "Denchi Power Ltd (formerly ABSL Power Solutions Limited)" 578 "advanSea" 579 "KVH Industries, Inc." 580 "San Jose Technology, Inc." 581 "Väderstad AB" 582 "Innovative Software Engineering" 583 "Yachtcontrol" 584 "CarMedialab GmbH" 585 "Industrial Electronic Controls" 586 "Suzuki Motor Corp" 587 "JCA Electronics" 588 "Vignal Systems" 589 "MICO, Inc." 590 "ARGO-HYTOS GMBH" 591 "United States Coast Guard" 592 "tecsis GmbH" 593 "Sensata Technologies" 594 "Kongsberg Automotive" 595 "CustomWare" 596 "Brunelco Electronic Innovators B.V." 597 "Hydac Filter Systems GmbH" 598 "ABB Turbo Systems Ltd" 599 "Spudnik Equipment Co, LLC" 600 "Aquatic AV" 601 "Navitas Systems" 602 "Nomad Digital Ltd." 603 "Kereval" 604 "Rototilt Group AB (formerly Indexator Rototilt Systems AB)" 605 "Aventics GmbH" 606 "Intellian Technologies" 607 "Knappco/Civacon" 608 "Gale Banks Engineering" 609 "Walvoil S.p.A." 610 "Trail Tech" 611 "Esterline" 612 "Samwon IT" 613 "HKS Co., Ltd." 614 "ARLT Technologies GmbH" 615 "Networkfleet, Verizon Telematics" 616 "SMART-TEC s.r.o." 617 "Zero Emission Vehicles" 618 "Evrard SA" 619 "Right Weigh Load Scales" 620 "BorgWarner Inc. (formerly Sevcon Ltd.)" 621 "Hagie Manufacturing Company" 622 "Floyd Bell Inc" 623 "Xirgo Technologies" 624 "Blackbox Machine Control Pty Ltd" 625 "Global MRV Inc." 626 "AVL DiTEST GmbH" 627 "Radio Ocean" 628 "Falck Schmidt Defence Systems" 629 "Agri Info Design, Ltd." 630 "SmartDrive Systems Inc." 631 "Reltima" 632 "Pepperl+Fuchs GmbH" 633 "TORC Robotics" 634 "Rocky Research" 635 "Argo Tractors S.p.A." 636 "Divelbiss Corporation" 637 "Bavaria Yachtbau GmbH" 638 "KVH Industries, Inc." 639 "Startec s.r.l." 640 "Power Solutions International" 641 "Diverse Yacht Services" 642 "Moog / Aspen Motion Technologies" 643 "Bogballe A/S" 644 "KUS USA" 645 "esd electronic system design gmbh" 646 "Veenhuis Machines B.V." 647 "Siloking" 648 "OJSC Ekran" 649 "Control-Q B.V." 650 "Seiko Epson Corp." 651 "Takakita Co, Ltd." 652 "MicroControl GmbH & Co. KG" 653 "AEV, spol. s r. o." 654 "Kohler Power Systems, Detroit Engine Development Center (DEDC)" 655 "Genge & Thoma AG" 656 "PRO SOLUS do Brasil" 657 "Terzo Power Systems" 658 "Shenzhen Jiuzhou Himunication Technology Co., Ltd" 659 "Data Panel Corp." 660 "Auto-Gaz Centrum" 661 "SPAL Automotive S.r.l." 662 "Kissling Elektrotechnik GmbH" 663 "Delta Systems, Inc" 664 "Level Developments Ltd" 665 "Gebr. Bode GmbH & Co. KG" 666 "Schaeffler Technologies AG & Co., KG" 667 "Bartec" 668 "MacDon Industries Ltd." 669 "Quantum Fuel Systems Technologies Worldwide, Inc" 670 "STEMCO LP" 671 "Innovative Controls Inc." 672 "OPTIMA Concept" 673 "Caruelle Nicolas" 674 "Yara International ASA" 675 "Kawasaki Motors, Ltd. (formerly Kawasaki Motors Corp., USA)" 676 "Danfoss IXA A/S" 677 "DSA Daten- und Systemtechnik GmbH" 678 "KeepTruckin, Inc." 679 "OXE Marine AB (formerly Cimco Marine AB)" 680 "AMVAC Chemical Corporation" 681 "BEDIA Motorentechnik GmbH & Co. KG" 682 "Eckelmann AG" 683 "Fosen Elektro" 684 "KEB" 685 "ANEDO (formerly ANEDO Ltd.)" 686 "Taigene Electric Machinery Corp." 687 "Flight Systems, Inc." 688 "Rockford Corp" 689 "Aarcomm Systems Inc" 690 "LINAK A/S" 691 "Digitroll Agricultural Electronics" 692 "Tanhay Corporation" 693 "Agility Fuel Solutions (formerly Agility Fuel Systems)" 694 "GasTOPS Ltd." 695 "Weldon Technologies" 696 "DRS Network & Imaging Systems, LLC (DRS Technologies)" 697 "JOST Umeå AB (formerly Ålö AB)" 698 "Scorpion Technologies Ltd." 699 "Harman International (formerly Harman International Industries)" 700 "K-Tec Earthmovers Inc." 701 "BigRoad Inc." 702 "Weichai Power Co., Ltd." 703 "Hydro Tab Marine Engineering" 704 "JL Audio, Inc." 705 "SVAB Hydraulik AB" 706 "Shanghai Diesel Engine Corporation Limited" 707 "Rochester Gauges Inc" 708 "Lars Thrane A/S" 709 "Marquardt GmbH" 710 "Greentronics Ltd." 711 "DAS Co., LTD" 712 "LOR Manufacturing Company Inc." 713 "US Hybrid Corporation" 714 "Kobashi Kogyo Co., Ltd." 715 "Autonnic Research Ltd" 716 "Eaton Control & Power Conversion Division (CPCD)" 717 "Yacht Devices Ltd" 718 "Micronet Inc" 719 "Cojali S. L." 720 "WITZ Corporation" 721 "Hypro" 722 "Contelec AG" 723 "Jabil Inc." 724 "Electronic Applications, Inc." 725 "Hitachi Construction Machinery Co., Ltd." 726 "MIDORI PRECISIONS" 727 "Dhoot Transmission Pvt Ltd." 728 "Streumaster (formerly Streumaster / Panien)" 729 "Liebherr" 730 "BERTHOUD AGRICOLE" 731 "Modine Manufacturing Company" 732 "Gefran S.p.A." 733 "Intendia S.L." 734 "REAPsystems" 735 "AEM Performance Electronics" 736 "Terex Aerial Work Platforms - Genie" 737 "Balluff GmbH" 738 "Blue Ink Technologies" 739 "LXNAV d.o.o." 740 "e-Traction" 741 "Carling Technologies" 742 "EROAD" 743 "Daemyung Elevator Co., Ltd." 744 "Woosung Engineering Co., Ltd." 745 "Cidra Corporate Services Inc." 746 "SurePoint Ag Systems (formerly SureFire Ag Systems, Inc.)" 747 "Agratronix" 748 "ISOTTA" 749 "Chart Inc." 750 "Joskin SA" 751 "Pacific Track" 752 "Deep Sea Electronics Plc" 753 "AIROD Technologies" 754 "Parker Hannifin Corp., Automation Group" 755 "Firefly Integrations" 756 "Maschio Gaspardo S.P.A." 757 "IMPCO Technologies" 758 "Banner Engineering Corp." 759 "Hydro-Gear" 760 "Bernecker + Rainer Industrie Elektronik GmbH" 761 "MITA OLEODINAMICA S.p.A." 762 "ROJ s.r.l." 763 "AT-Systems BVBA" 764 "Bednar FMT s.r.o." 765 "GIGAVAC" 766 "Epec Oy" 767 "Alliance Wireless Technologies Inc." 768 "Flores Automation, LLC" 769 "Trombetta" 770 "MONOSEM" 771 "Shaw Development, LLC" 772 "Blink Marine" 773 "Clarion Corporation of America" 774 "Taisho Corporation" 775 "ZIEHL-ABEGG Automotive GmbH" 776 "HMI Systems LLC" 777 "Ocean Signal Ltd" 778 "Seakeeper Inc." 779 "RLC Electronic Systems" 780 "Turntide Transport Limited (formerly AVID Technology Ltd)" 781 "Poly-Planar LLC" 782 "AVR nv" 783 "Loup Electronics Inc." 784 "CM Automotive Systems, Inc." 785 "Fischer Panda GmbH" 786 "Johnson Matthey Battery Systems" 787 "Abertax Technologies Limited" 788 "MoTeC Pty Ltd" 789 "GRADALL" 790 "VACALL" 791 "AUTEC" 792 "Kostal Mexicana" 793 "James Fisher Prolec" 794 "Shihlin Electric & Engineering Corporation" 795 "Broyda Enterprises Pty Ltd" 796 "Canadian Automotive Industries Ltd" 797 "Tides Marine" 798 "Lumishore Ltd" 799 "Stillwater Designs and Audio, Inc. - KICKER" 800 "Delta-Q Technologies" 801 "LOR Manufacturing Company Inc." 802 "SPBI (Bj Technologie)" 803 "Gill Sensors & Controls Limited" 804 "ASA Electronics" 805 "Gundersen & Løken AS" 806 "Charge Automotive Ltd" 807 "Schneider-Electric" 808 "RIMEX Supply Ltd." 809 "HMS Industrial Networks AB" 810 "Dutch Power Company" 811 "Blue Water Desalination" 812 "Torch Technologies" 813 "Thales Suisse SA" 814 "Kronotech Srl (formerly Soltec Soluzioni Tecnologiche Srl)" 815 "FLIR Systems, Inc." 816 "UniStrong" 817 "TE Connectivity Sensor Solutions" 818 "HGNSS" 819 "Preco Electronics" 820 "DIaLOGIKa Gesellschaft fuer angewandte Informatik mbH" 821 "Thorsen Teknik A/S" 822 "Bren-Tronics, Inc." 823 "ACEINNA, Inc (formerly MEMSIC, Inc)" 824 "Undheim Systems AS" 825 "BPW Hungária" 826 "Lewmar Marine Inc" 827 "INmatix Technology Group Ltd" 828 "AgriBrink Inc." 829 "Drov Technologies, Inc." 830 "Ultra Motion LLC" 831 "DOK-ING Ltd." 832 "Heizomat Gerätebau-Energiesysteme GmbH" 833 "Electrum Automation AB" 834 "Pioneer Microsystems, Inc." 835 "PetTrack Ltd." 836 "Signature4" 837 "Famic Technologies Inc." 838 "Teamsurv Ltd" 839 "Indexator Rotator Systems AB" 840 "E.S.T.E. srl" 841 "Agra-GPS" 842 "DigiDevice Srl" 843 "Hendrickson Truck Commercial Vehicle Systems" 844 "FELL AS" 845 "GMB Güstrower Maschinenbau GmbH" 846 "L3 Magnet-Motor" 847 "Oceanvolt" 848 "ningupex" 849 "MTS Maschinentechnik Schrode AG" 850 "Geoprospectors GmbH" 851 "Novotechnik Messwertaufnehmer OHG" 852 "Velvac Inc" 853 "Teledyne RESON B.V." 854 "GEMAC Chemnitz GmbH" 855 "Toshiba Infrastructure Systems & Solutions Corporation" 856 "FarmFacts GmbH" 857 "Zoomlion Heavy Industry NA, Inc" 858 "Littelfuse" 859 "Valor" 860 "Michelin" 861 "Adel System S.r.l." 862 "Prospec Electronics" 863 "SMAG" 864 "Streamline Transportation Technologies Inc." 865 "MyEasyFarm" 866 "Netradyne, Inc." 867 "Skeleton Technologies" 868 "Data Panel Corp" 869 "Intercomp" 870 "Textron Fleet Management" 871 "Agri-Fab (formerly Superior Tech Inc)" 872 "Kählig Antriebstechnik GmbH" 873 "Garnet Instruments Ltd." 874 "MTA S.p.A." 875 "Salvarani S.r.l." 876 "SUCO Robert Scheuffele GmbH & Co. KG" 877 "SICK ATech GmbH" 878 "FOTON" 879 "PG Trionic, Inc." 880 "Revision Military" 881 "Sovema" 882 "BHTronik GmbH & Co. KG" 883 "Swift Navigation, Inc." 884 "Sure Grip Controls Inc." 885 "SICK AG (formerly SICK Stegmann GmbH)" 886 "Hitachi Zosen Corporation" 887 "Turntide Transport Limited (formerly Hyperdrive Innovation Limited)" 888 "Carma Systems Inc" 889 "SANY America Inc" 890 "L3 Technologies, Inc." 891 "CarrierWeb" 892 "Mectronx Corp" 893 "KlinkTechnics Ltd." 894 "Rhodan Marine Systems of Florida LLC (Duplicate entry; use MFR ID 1012)" 895 "Peloton Technology" 896 "NextFour Solutions Ltd" 897 "Dot Technology Corp." 898 "Josef Kotte Landtechnik GmbH & Co. KG" 899 "Lippert Components, Inc" 900 "OSB connagtive GmbH (formerly OSB AG)" 901 "Zivan Srl" 902 "Bucher Hydraulics" 903 "InMotion" 904 "Equipment Safety Systems Pty. Ltd. (EQSS)" 905 "ASA Electronics" 906 "MOBA AG" 907 "strautmann" 908 "Chonbuk National University Department of Electronics" 909 "Marines Co., Ltd." 910 "Hermann Paus Maschinenfabrik GmbH" 911 "Nautic-On" 912 "Steyr Motors GmbH" 913 "Toyota Motor Corporation" 914 "ZETOR TRACTORS a.s." 915 "Dosificacion y sistemas electronicos S.L. (DSE)" 916 "Hans Turck GmbH & Co. KG (formerly Turck Inc.)" 917 "Sentinel d.o.o." 918 "AMW Machine Control, Inc" 919 "Furrion LLC" 920 "MTD Consumer Group Inc." 921 "ROPA Fahrzeug- und Maschinenbau GmbH" 922 "Terberg Benschop B.V." 923 "ELTEK S.p.A." 924 "PAS Peschak Autonome Systeme GmbH" 925 "GW Lisk Company" 926 "Buhler Industries Inc." 927 "Saicon" 928 "EAO Automotive GmbH & Co. KG" 929 "Jl Marine Systems, Inc." 930 "Ecotronix Corp." 931 "Enertec Marine Ltd" 932 "Discover Battery" 933 "Delta Mobile Systems, Inc." 934 "Farmobile, Inc." 935 "Meels GmbH & Co. KG" 936 "Hi-tech Millennium" 937 "Precision Circuits Inc" 938 "LEVEL Systems" 939 "Warn Industries, Inc." 940 "Dometal Oy" 941 "Navya" 942 "Vogelsang GmbH & Co. KG" 943 "FISCHER AG Präzisionspindeln" 944 "ZONTISA Marine SL" 945 "Equalizer AG" 946 "Hydac Tecnologia Ltda" 947 "Gerd Bär GmbH" 948 "Donix" 949 "Škoda Electric a.s." 950 "RE:Lab s.r.l." 951 "Exor International S.p.A." 952 "Tan Delta Systems Ltd" 953 "Curtiss-Wright" 954 "Setec Pty Ltd" 955 "Hottinger Baldwin (Suzhou) Electronic Measurement Technology Co., Ltd." 956 "Piher Sensors & Controls S.A." 957 "Sierra Wireless Inc" 958 "NHK MEC Corporation" 959 "Cascade Corporation" 960 "Vemcon GmbH" 961 "POK SAS" 962 "Timbolier Industries, Inc." 963 "Thomason Jones Company, LLC" 964 "AgroVIR Kft" 965 "Ro-Sys Software" 966 "VisibleFarm" 967 "Moteck Electric Corp." 968 "Cox Powertrain Limited" 969 "Blue Sea Systems" 970 "Jaboni Power Products, LLC" 971 "B+B Smartworx" 972 "Axion AG" 973 "Zasso GmbH" 974 "Pico Technology Limited" 975 "Siemens AG" 976 "Derive Systems, Inc." 977 "Copeland LP (formerly Emerson Electric Co.)" 978 "Canfield Connector" 979 "McHale" 980 "Gussi Italia S.R.L." 981 "Kobelt Manufacturing Co. Ltd" 982 "Briggs & Stratton Corporation" 983 "Dezwaef NV" 984 "E-T-A Elektrotechnische Apparate GmbH" 985 "NLR, LLC" 986 "AAMP Global" 987 "Baltic Car Equipment" 988 "Voith Turbo" 989 "Flux-Geräte GmbH" 990 "SAMSUNG SDI Co., Ltd." 991 "Deutronic Elektronik GmbH" 992 "MarineIOT LLC" 993 "Alelion Energy Systems AB" 994 "Morris Industries Ltd." 995 "Circuitlink Pty Ltd." 996 "Eniquest Pty Ltd" 997 "Xenta Systems Srl" 998 "Transcell Technology Inc" 999 "TerraTroniq B.V." 1000 "Landmaschinen Wienhoff GmbH" 1001 "Cleral Inc." 1002 "Kussmaul Electronics Co." 1003 "technotrans SE" 1004 "Ultraflex SpA" 1005 "TSE Brakes, Inc." 1006 "Proterra" 1007 "Maschinenfabrik Meyer-Lohne GmbH" 1008 "Lintest Systems LLC" 1009 "TouchTronics, Inc." 1010 "Agricultural Industry Electronics Foundation e.V." 1011 "Soundmax Electronics Ltd" 1012 "Rhodan Marine Systems of Florida LLC" 1013 "Allochis E-Tec" 1014 "Briri Maschinenbau GmbH" 1015 "SECURITAG SAS" 1016 "Röhren- und Pumpenwerk BAUER GmbH" 1017 "Caldaro AB" 1018 "Flex TTS" 1019 "Codek Foundries" 1020 "Onyx Marine Automation s.r.l." 1021 "Entratech Systems LLC" 1022 "ITC Inc" 1023 "PEAK-System Technik GmbH" 1024 "Inventus Power" 1025 "eze System, Inc." 1026 "ZTR Control Systems, LLC" 1027 "Goldacres PTY LTD" 1028 "Autel Intelligent Technology Corp., Ltd" 1029 "The Marine Guardian LLC" 1030 "Tume-Agri Oy" 1031 "Flintec UK Ltd." 1032 "SIMOL S.p.A." 1033 "ECCO Safety Group" 1034 "Siren Marine" 1035 "Agres" 1036 "Bender GmbH & Co. KG" 1037 "Dragonfly Energy Corp." 1038 "EMIT Technologies, Inc." 1039 "Liugong Dressta Machinery" 1040 "BPE Electronics Srl" 1041 "EZ Lynk" 1042 "engcon group" 1043 "Hyva" 1044 "Xee" 1045 "CMR Group" 1046 "Praxidyn" 1047 "Sonic Corporation" 1048 "Agrivation UG" 1049 "S&S Cycle" 1050 "Spacenus GmbH" 1051 "ProNav AS" 1052 "Pfreundt" 1053 "Vetus Maxwell, Inc." 1054 "Schmotzer Hacktechnik GmbH & Co. KG" 1055 "EXA Computing GmbH" 1056 "Lithium Pros" 1057 "EquipmentShare" 1058 "Bondioli & Pavesi SpA" 1059 "Boatrax" 1060 "Scale-Tec" 1061 "Volvo Construction Equipment" 1062 "Marol Co Ltd" 1063 "SolSteer" 1064 "Omnitech Robotics Inc." 1065 "CALYPSO Instruments" 1066 "Spot Zero Water" 1067 "Tecomec S.r.l." 1068 "Zapi S.p.A." 1069 "Lithionics Battery LLC" 1070 "Quick-teck Electronics Ltd" 1071 "MACH SYSTEMS s.r.o." 1072 "La Marche Manufacturing Company" 1073 "Manitou Equipment America LLC" 1074 "Kindhelm / Navigs Oy" 1075 "Uniden America Corporation" 1076 "DOGA S.A." 1077 "Ymer Technology" 1078 "GE Appliances" 1079 "Carl Zeiss Spectroscopy GmbH" 1080 "Epsilor-Electric Fuel Ltd." 1081 "Imcon Electronics, s.r.o." 1082 "TÜMOSAN Engine and Tractor Co." 1083 "Nauticoncept" 1084 "Shadow-Caster LED lighting LLC" 1085 "Wet Sounds, LLC" 1086 "Life Racing Ltd" 1087 "ITPhotonics S.r.l." 1088 "E-T-A Circuit Breakers" 1089 "Carrosserie HESS AG" 1090 "E-T-A Circuit Breakers Ltd" 1091 "Wheel Monitor Inc." 1092 "Scheiber" 1093 "innolectric" 1094 "Tokushu Denki" 1095 "WEG Drives and Controls - Automação Ltda" 1096 "Texense Sensors" 1097 "M2M Craft Co., Ltd" 1098 "Preh GmbH" 1099 "MadgeTech, Inc" 1100 "LINK Marine Technologies (formerly Smart Yachts International Limited)" 1101 "DIS Sensors B.V." 1102 "Carl Geringhoff GmbH & Co. KG" 1103 "Diesel Laptops" 1104 "The Toro Company" 1105 "Redekop Manufacturing" 1106 "Great Dane LLC" 1107 "Dräger Safety" 1108 "ORBCOMM" 1109 "Dockmate" 1110 "Analytic Systems Ware (1993) Ltd." 1111 "SEPPI M." 1112 "Bollinger Motors" 1113 "iVolve Pty Ltd" 1114 "Bob's Machine" 1115 "Gems Sensors & Controls" 1116 "HR Agrartechnik GmbH" 1117 "LG Chem, Ltd" 1118 "L3Harris ASV" 1119 "Balmar LLC" 1120 "Elettromedia s.r.l." 1121 "Platform Science" 1122 "GT Inc." 1123 "QP Hydraulics" 1124 "Fortron Agriculture" 1125 "Griffith-Elder & Co. Ltd." 1126 "Auralix" 1127 "ElectroMaax" 1128 "Citoon Electronic Technology (Tianjin) Co., Ltd." 1129 "Spectrolytic GmbH" 1130 "Vitesco Technologies" 1131 "Guliwer electronics s.r.o." 1132 "Tokachi Zaidan" 1133 "MEGATRON Elektronik GmbH & Co. KG" 1134 "Master Schools at Ostbahnhof" 1135 "Japan Aviation Electronics Industry, Limited" 1136 "Primosensor GmbH" 1137 "SIKO GmbH" 1138 "Micro-Sensor GmbH" 1139 "ASP Technology" 1140 "Across Oceans Systems Ltd." 1141 "MRS Electronic GmbH & Co. KG" 1142 "Truma" 1143 "Elektro-Szoft 2000" 1144 "Troo Corporation" 1145 "Kiwi Yachting" 1146 "Rometron" 1147 "Dana Inc." 1148 "Stercom Power Solutions GmbH" 1149 "Wuxi Shengbang Electronics Co., Ltd" 1150 "BSB Artificial Intelligence GmbH" 1151 "Orca Technologies AS" 1152 "Vredo Dodewaard B.V." 1153 "Kawasaki Heavy Industries, Ltd." 1154 "TBS Electronics BV" 1155 "LACOS GmbH (formerly LACOS Computerservice GmbH)" 1156 "Nokian Tyres" 1157 "Carriergistics" 1158 "Technoton Electronics" 1159 "Bel Power Solutions" 1160 "MG Energy Systems B.V." 1161 "Griessbach GmbH" 1162 "PEL-tuote Oy" 1163 "DFX Technologies LLC" 1164 "SEG Automotive" 1165 "InnoTotal AB" 1166 "Wachendorff Automation GmbH & Co. KG" 1167 "Tevva Motors" 1168 "Masats S.A." 1169 "Sea Machine Robotics Inc." 1170 "Poseidon Ocean Systems Ltd." 1171 "Vista Manufacturing" 1172 "Hyzon Motors" 1173 "philippi elektrische systeme gmbh" 1174 "Agricon GmbH" 1175 "MAGTEC Products, Inc." 1176 "Asuns Corp." 1177 "RNG International Inc." 1178 "ERO GmbH" 1179 "QS Control srl" 1180 "Murata Power Solutions Inc." 1181 "Banjo Corporation" 1182 "Rottmann Automation" 1183 "Zipwake AB" 1184 "AMA S.p.A." 1185 "WFCO Electronics" 1186 "Sailmon BV" 1187 "TiTAN-Project LLC" 1188 "G-SNS" 1189 "Autotrasporti Cavallo G&V" 1190 "Sirros IoT" 1191 "Pacoma USA, Inc." 1192 "Airmoniq Pro Kft." 1193 "emotas embedded communication GmbH" 1194 "Sierra Marine" 1195 "düvelsdorf" 1196 "Terra Care GmbH" 1197 "SOLGE Corporation" 1198 "ComLink Equipamentos Eletrônicos Ltda" 1199 "ELEO Technologies B.V." 1200 "Xinuo Information Technology (Xiamen) Corporation Limited" 1201 "Emisense Technologies, LLC" 1202 "OSCAR ELECTRONICS SRL (formerly OSCAR Elettronica)" 1203 "Equipment Technologies, Inc." 1204 "Miller Technology Incorporated" 1205 "Carbon Autonomous Robotic Systems" 1206 "STE Solutions B.V." 1207 "UEC Electronics" 1208 "Afflield Kft. (MachineryGuide)" 1209 "Bauser GmbH & Co. KG" 1210 "Ambra Solutions" 1211 "Kiwon Electronics Co., Ltd." 1212 "TAO Performance Limited" 1213 "Apollo Tyres Ltd" 1214 "Element 1" 1215 "Power Control Systems" 1216 "SMP Poland sp. z o.o." 1217 "FSG Fernsteuergeräte Kurt Oelsch GmbH" 1218 "Septentrio" 1219 "Weidmueller Interface GmbH & Co. KG" 1220 "Catamaran Electronics LLC" 1221 "Norcold Inc." 1222 "Tough Tech Ltd." 1223 "Toyo Agricultural Machinery Manufacturing Co., Ltd." 1224 "Neuser Elektrotechnik GmbH" 1225 "SeedMaster Manufacturing Ltd." 1226 "Piippo Hydraulic" 1227 "YAHATA Co., Ltd." 1228 "INTILION GmbH" 1229 "Arcon Designs, LLC" 1230 "Nick Abbey Digital Agriculture Ltd" 1231 "Excidor AB" 1232 "Treffler Maschinenbau GmbH & Co. KG" 1233 "nke Marine Electronics" 1234 "American Battery Solutions" 1235 "NESAN Automotive Inc." 1236 "Agrosystem" 1237 "Changzhou Lambda Electronic Co., Ltd" 1238 "Honda Electronics Co., Ltd" 1239 "SuperTrack Aps" 1240 "TiMOTION" 1241 "Ineo Systrans" 1242 "Super Start Batteries" 1243 "AvMap S.r.l." 1244 "Planti Center" 1245 "Raritan Engineering Company, Inc" 1246 "Rother Industries & Technology" 1247 "GRIFA" 1248 "O.M.F.B. S.p.A. Hydraulic Components" 1249 "Integrated Power Solutions AG" 1250 "ELHO" 1251 "Valmet Automotive EV Power Ltd" 1252 "APV - Technische Produkte GmbH" 1253 "Trafag AG" 1254 "ARADEX AG" 1255 "Altec Industries, Inc." 1256 "Dimensions Agri Technologies AS" 1257 "KOSTAL" 1258 "AGC Technologies" 1259 "Grayson Automotive Services Limited" 1260 "Interactive Technologies, Inc." 1261 "AgXeed" 1262 "Fort Robotics" 1263 "BOS Balance of Storage Systems AG" 1264 "Microelect" 1265 "IPETRONIK GmbH & Co KG" 1266 "Hyundai Doosan Infracore" 1267 "Wacker Neuson SE" 1268 "Back 40 Precision Inc." 1269 "VIS Hydraulics s.r.l." 1270 "Versalift Denmark A/S" 1271 "Raven Connected" 1272 "Samsara Inc." 1273 "Clearflame Engines Inc" 1274 "LDL Technology" 1275 "O.M.P. Officine Mazzocco Pagnoni S.r.l." 1276 "Aspin Kemp & Associates" 1277 "BMZ Germany GmbH" 1278 "Comrod Communication Group" 1279 "Ognibene Power S.p.A." 1280 "SANTEST CO., LTD." 1281 "iQuus" 1282 "COTEK ELECTRONIC IND. CO., LTD" 1283 "LTG Tech" 1284 "Robot Makers GmbH" 1285 "Graco Inc." 1286 "NEXAT GmbH" 1287 "Spartan Radar" 1288 "ANELLO Photonics" 1289 "Loadrite (Auckland) Ltd." 1290 "WaveTamer Partners LLC" 1291 "Forward Thinking Systems LLC" 1292 "SUMITOMO CONSTRUCTION MACHINERY Co., Ltd." 1293 "POSITAL" 1294 "TR-Electronic GmbH" 1295 "SIP d.d." 1296 "Hexagon" 1297 "Micro-Epsilon Messtechnik GmbH & Co. KG" 1298 "SFOGGIA Agriculture Division S.r.l." 1299 "Energy Solutions" 1300 "Watt Fuel Cell Corporation" 1301 "Tecumseh do Brasil Ltda" 1302 "ProMariner" 1303 "Carbon Bee AgTech" 1304 "Palfinger Europe GmbH" 1305 "dragonfly Energy" 1306 "Koden Electronics Co., Ltd." 1307 "Smart AG Systems" 1308 "Agtecnic" 1309 "Shanghai Zhichuan Electronic Tech Co., Ltd." 1310 "LPL Systems (formerly Loughborough Projects Ltd)" 1311 "Humphree AB" 1312 "Control Devices Pty Ltd" 1313 "United States Army - Ground Vehicle Systems Center" 1314 "Newton Crouch Company, LLC" 1315 "SMPC Technologies Ltd." 1316 "Hinkley Yachts" 1317 "GMM - Global Maritime Management GmbH" 1318 "Atlis Motor Vehicles" 1319 "I/O Controls Corporation" 1320 "Triskel Marine Ltd" 1321 "PATLITE Corporation" 1322 "Movimatica" 1323 "Briter Products, Inc." 1324 "Bourgault Industries" 1325 "OPW (formerly BASE Engineering Inc.)" 1326 "HBC-radiomatic GmbH" 1327 "Frans Vervaet B.V." 1328 "PerPlant ApS" 1329 "IDM S.r.l." 1330 "Warwick Control Technologies" 1331 "Dolphin Charger" 1332 "Fairbanks Scales, Inc." 1333 "xFarm Technologies SA" 1334 "Greer Company" 1335 "CPDEVICE" 1336 "Aegis Power Systems, Inc." 1337 "Barnacle Systems Inc." 1338 "Volta Trucks AB" 1339 "Tillett and Hague Technology Limited" 1340 "ORELTEK Elektronik ve Yazılım Teknolojileri" 1341 "Ag Express Electronics" 1342 "DKE-Data GmbH & Co. KG" 1343 "Heavy Data GmbH" 1344 "Haulotte Group" 1345 "PRIGNITZ Mikrosystemtechnik GmbH" 1346 "Einboeck GmbH" 1347 "Munckhof Fruit Tech Innovators" 1348 "Radian IoT, Inc." 1349 "ANNABURGER Nutzfahrzeug GmbH" 1350 "AGRONETIC" 1351 "Motorenfabrik Hatz GmbH & Co. KG" 1352 "NISHIYAMA Corporation" 1353 "Ocean LED Marine Ltd" 1354 "Técnicas de Electrónica y Automatismos, S.A." 1355 "DROP Agricultura Ltda" 1356 "Nordic Lights Ltd" 1357 "TireCheck" 1358 "Fontaine Fifth Wheel" 1359 "BlueNav" 1360 "Lemca Vision" 1361 "Nantong Saiyang Electronics Co., Ltd." 1362 "Zparq AB" 1363 "Calix AB" 1364 "Yashu Systems" 1365 "JVCKENWOOD Corporation" 1366 "Telemecanique Sensors & Switches" 1367 "Dewulf NV" 1368 "RAD Propulsion Ltd" 1369 "Electric Yacht" 1370 "Emtech S.A." 1371 "First Mode" 1372 "Elco Motor Yachts" 1373 "Centek Industries" 1374 "CASAPPA S.p.A." 1375 "ŠKODA ELECTRIC a.s." 1376 "SUNS International, LLC" 1377 "ABD Solutions" 1378 "Bertini SA" 1379 "Novag SAS" 1380 "ADVES GmbH & Co. KG" 1381 "Dr. Diesel Technologies" 1382 "Thornwave Labs Inc." 1383 "Alpego S.p.A." 1384 "Tecnoseal Foundry S.r.l." 1385 "Pro Charging Systems, LLC" 1386 "Smart Eye AB" 1387 "Radel (Pty) Ltd" 1388 "Nira Technology" 1389 "EVEX Co., LTD" 1390 "FJ Dynamics International Limited" 1391 "AriensCo" 1392 "Phoenix America LLC" 1393 "Powerland Technology Inc" 1394 "Zhejiang Ruixing Electromechanical Technology Co., Ltd." 1395 "MLB Industrial" 1396 "Fast Ag Solutions, LLC" 1397 "SaMASZ Sp. Z o.o." 1398 "Gobius Sensor Technology AB" 1399 "Hans Brantner & Sohn Fahrzeugbaugesellschaft mbH" 1400 "IWN GmbH & Co. KG" 1401 "ROM Communications Inc." 1402 "ComNav Technology Ltd." 1403 "Arco Marine" 1404 "BRUSA HyPower AG" 1405 "TELIG Electronics" 1406 "Lumilex ALT SRL" 1407 "Open-Agriculture" 1408 "Lenco Marine Inc." 1409 "Z Elektronika Kft." 1410 "Allan Equipment Manufacturing Ltd." 1411 "Shanghai Huace Navigation Technology Ltd." 1412 "Naocontrol S.L." 1413 "OHNOH2O LLC" 1414 "INTRACOM DEFENSE S.A." 1415 "Máquinas Agrícolas Jacto S.A." 1416 "Wavetronix LLC" 1417 "Revatek LLC" 1418 "Karluna Engineering" 1419 "iPatch Marine" 1420 "TALOS - Precision Measurement Technologies" 1421 "Clarios, LLC" 1422 "xTCU AG" 1423 "AC S.A." 1424 "Bewis" 1425 "Electronics in Agriculture, School of Engineering, University of Galway" 1426 "Samson Group" 1427 "REITER RESPIRO" 1428 "Samo Maschinenbau GmbH" 1429 "Nikola Corporation" 1430 "Mantracourt Electronics Ltd" 1431 "Nauto Inc." 1432 "MDH Defence Ltd." 1433 "Unicontrol ApS" 1434 "eSurvey GNSS Ltd." 1435 "Heilongjiang Huida Technology Co., Ltd" 1436 "M-extend" 1437 "DOKEN Technology Co. Ltd." 1438 "Aeolionics" 1439 "PredictWind Ltd" 1440 "Egis Mobile Electric" 1441 "Shanghai Allynav Technology Co.,Ltd." 1442 "EVYTRA GmbH" 1443 "SoilEssentials Limited" 1444 "Micropower Group" 1445 "Starboard Yacht Group" 1446 "Roswell Marine" 1447 "Innotag Distributions Inc." 1448 "Elmer's Manufacturing" 1449 "Bontaz Centre" 1450 "Agrivaux" 1451 "Guangdong ePropulsion Technology Ltd." 1452 "Micro-Air LLC" 1453 "Vital Battery" 1454 "QTIS B.V." 1455 "Eberspächer Climate Control Systems International GmbH" 1456 "Krampe Fahrzeugbau GmbH" 1457 "Albach Maschinenbau AG" 1458 "RideController LLC" 1459 "Advanced Input Systems" 1460 "Tocaro Blue" 1461 "Vanquish Yachts" 1462 "Trackunit ApS" 1463 "STOK Electric" 1464 "Hi-Target Surveying Instrument Co., Ltd." 1465 "Watteco" 1466 "Sveaverken Svea Agri AB" 1467 "S.A.E.T. s.r.l." 1468 "Senquip" 1469 "LS Mtron" 1470 "GemOne NV" 1471 "FT Technologies" 1472 "Acculon Energy" 1473 "Cranesmart Systems, Inc." 1474 "Calex Electronics Limited" 1475 "DSP Solutions, Inc." 1476 "Wilhelm Stoll Maschinenfabrik GmbH" 1477 "TOBROCO-GIANT" 1478 "Alps Alpine Co., Ltd." 1479 "A-Electronix" 1480 "Thermo King" 1481 "E-Force Marine" 1482 "CMC Marine" 1483 "Nanjing Sandemarine Information Technology Co., Ltd." 1484 "AgroOSA" 1485 "Lester Electrical" 1486 "Xpanner" 1487 "Geosoft" 1488 "Boetkin Technology Co., LTD" 1489 "Lite-Check LLC" 1490 "Clean Republic SODO, LLC" 1491 "Power Pollen" 1492 "Softivert" 1493 "Jantop Oy" 1494 "RAPITRONICS" 1495 "FlyAgData" 1496 "AgriRobot" 1497 "ERMO Spa" 1498 "PM Pfanzelt Maschinenbau GmbH" 1499 "Hydrasystem SP. Z O.O." 1500 "Scanstrut Inc." 1501 "Reverso Pumps LLC" 1502 "Barantech" 1503 "Rosemount Specialty Products" 1504 "Nimbus Power Systems, Inc." 1505 "BC Motion" 1506 "Expion360" 1507 "Apex.AI, Inc." 1508 "Xwatch Safety Solutions Ltd. part of Hexagon" 1509 "Bondioli & Pavesi" 1510 "Austin Motor Works" 1511 "APATOR METRA s.r.o." 1512 "Lumitec LLC" 1513 "Sy-Klone International" 1514 "SYMX.ai" 1515 "Ingeniería y Sistemas Cerea" 1516 "THERMIS spol. s r.o." 1517 "Daedong Corporation" 1518 "Nova Kool Manufacturing ULC" 1519 "Volboff Electron Science and Technology Co., Ltd." 1520 "SRT Marine Systems PLC" 1521 "Agricolmeccanica" 1522 "American Thermal Instruments" 1523 "Carlson Software" 1524 "Ocean Infinity Solutions Limited" 1525 "Emsiso-emDrive" 1526 "MITSUBISHI MAHINDRA AGRICULTURAL MACHINERY CO.,LTD." 1527 "Richardt Steuer- und Regelgeraete GmbH" 1528 "Savant Technology" 1529 "Industrie Elektronik Brilon GmbH" 1530 "Roelama B.V." 1531 "Kobelco Construction Machinery Co.,Ltd." 1532 "E-Switch, Inc." 1533 "Rieker Inc." 1534 "BluVein" 1535 "LOX Container Technology AB" 1536 "Tatra Trucks a.s." 1537 "Anyload Weigh & Measure Inc." 1538 "Quick S.p.A." 1539 "Ceday Information Technologies" 1540 "Ideas & Motion" 1541 "Solid State Marine" 1542 "Global Digital Instruments" 1543 "GT Joysticks AG" 1544 "Geophysical Survey Systems, Inc." 1545 "RoadEazy" 1546 "ESMART" 1547 "Weichai Lovol Intelligent Agricultural Technology Co., Ltd." 1549 "AM Co., Ltd." 1550 "Mario Tanzi S.A." 1551 "LMCE Group" 1552 "Antoniosi Tecnologia Agroindustrial Ltda" 1553 "Boughton Engineering LTD" 1554 "Frigus AB" 1555 "Safiery" 1556 "B. Kaufmann AG Landmaschinen" 1557 "Interfacom S.A.U." 1558 "Intangles Lab Private Limited" 1559 "Kar-Tech, Inc." 1560 "MACOME CORPORATION" 1561 "Fox Marine" 1562 "Kingsat Communications Co., Ltd" 1563 "Wabtec Graham White" 1564 "Pro-Guide Batteries" 1565 "Livemac Co., Ltd." 1566 "OUTSET" 1567 "Hagedorn Software Engineering GmbH" 1568 "Aigro" 1569 "621 Technologies Inc." 1570 "Unverferth Manufacturing Company Inc." 1571 "Super B" 1572 "SMARTLINE Co., Ltd." 1573 "R.H. Sheppard" 1574 "SIGMA4 SRL" 1575 "DieselHeat" 1576 "RB International S.r.l." 1577 "Ironstone AG" 1578 "MidNite Solar Inc." 1579 "Hydro Engineering" 1580 "Nabtesco Corporation" 1581 "Metro Marine LLC" 1582 "Samsung Heavy Industries Co., Ltd." 1583 "MULTI-WING GROUP A/S" 1584 "TWK-ELEKTRONIK GmbH" 1585 "Qianxun Spatial Intelligence (Zhejiang) Inc." 1586 "XAG CO., LTD." 1587 "BURGER GROUP" 1588 "MORESIL" 1589 "HÜBNER GmbH & Co. KG" 1590 "Monpaineis" 1591 "WaterWorld Electronics" 1592 "Incomagri Máquinas Agrícolas Ltda" 1593 "Cordon Technologies" 1594 "Elwell Corporation" 1595 "Pruefrex engineering e motion gmbh" 1596 "Neosens" 1597 "S.A.S. Desvoys & Fils" 1598 "Di Goro" 1599 "Kamtec" 1600 "Consolidated Metco, Inc." 1601 "T/CCI Manufacturing, LLC" 1602 "Norcross Marine Products" 1603 "Rockville Audio" 1604 "RoverSense Technologies" 1605 "Blue Wolf" 1606 "SENSAR MARINE INC." 1607 "Micro-Key" 1608 "Quectel" 1609 "NanoNord A/S" 1610 "Simarine d.o.o." 1611 "Ningbo Haibo Group Co., Ltd." 1612 "BLUETTI" 1613 "Whisperpower" 1614 "Risseeuw Techniek" 1615 "J.Assy" 1616 "Satel Oy" 1617 "DRUDLES s.r.o." 1618 "The Carlisle and Finch Co." 1619 "Clemens GmbH & Co. KG" 1620 "BlueNav" 1621 "Mach Inc." 1622 "Brettmeister Elektronik" 1623 "PRO Charging Systems, LLC" 1624 "CrossControl" 1625 "DMX Power LLC" 1626 "SMP STABIL GmbH" 1627 "Roter Italia" 1628 "Vanemar, Inc." 1629 "dSPACE SE & Co. KG" 1630 "Rainer Meyer Landmaschinen GmbH" 1631 "Leidos" 1632 "Zocon" 1633 "Zydro Marine Technologies, Inc." 1634 "IBISUL ELETRÔNICA LTDA" 1635 "Saframax Industrial" 1636 "TBB POWER (XIAMEN) Co., Ltd." 1637 "Scherzinger Pumpen GmbH & Co. KG" 1638 "TEMPA TEKNIK" 1639 "GEA Farm Technologies Canada Inc." 1650 "Shanghai Infipax Technology Co., Ltd." 1653 "Schaffer Farming Technologies" 1850 "Seastar Solutions (formerly Teleflex)" 1851 "RayMarine" 1852 "Navionics" 1853 "Japan Radio Co" 1854 "Northstar Technologies" 1855 "Furuno USA" 1856 "Trimble" 1857 "Simrad" 1858 "Litton" 1859 "Kvasar AB" 1860 "MMP" 1861 "Vector North America (formerly Vector Cantech)" 1862 "Sanshin" 1863 "Thomas G. Faria Co." ;
VAL_ 2566838272 Device_Class 0 "Reserved for 2000 Use" 10 "System tools" 20 "Safety systems" 25 "Internetwork device" 30 "Electrical Distribution" 35 "Electrical Generation" 40 "Steering and Control surfaces" 50 "Propulsion" 60 "Navigation" 70 "Communication" 75 "Sensor Communication Interface" 80 "Instrumentation/general systems" 85 "External Environment" 90 "Internal Environment" 100 "Deck + cargo + fishing equipment systems" 110 "Human Interface" 120 "Display" 125 "Entertainment" ;
VAL_ 2566838272 Industry_Code 0 "Global" 1 "Highway" 2 "Agriculture" 3 "Construction" 4 "Marine Industry" 5 "Industrial" ;
VAL_ 2566848512 Manufacturer_Code 0 "For experimental or developmental use only." 1 "Bendix Commercial Vehicle Systems LLC (formerly Allied Signal Inc.)" 2 "Allison Transmission, Inc." 3 "Ametek, US Gauge Division" 4 "Ametek-Dixson" 5 "AMP Inc." 6 "Berifors Electronics AB" 7 "Case Corp." 8 "Caterpillar Inc." 9 "Chrysler Corp." 10 "Cummins Inc (formerly Cummins Engine Co)" 11 "Dearborn Group Inc." 12 "Deere & Company, Precision Farming" 13 "Delco Electronics" 14 "Detroit Diesel Corporation" 15 "DICKEY-john Corporation" 16 "Eaton Corp" 17 "Eaton Corp, Corp Res & Dev" 18 "Eaton Corp, Transmission Div." 19 "Eaton Corp. Trucking Info Services" 20 "Eaton Ltd" 21 "Echlin Inc., Midland Brake Inc." 22 "Ford Motor Co., Electronic Concepts & Systems" 23 "Ford Motor Co., Heavy Truck" 24 "Ford Motor Co., Vehicle Controls" 25 "Daimler Trucks North America LLC (formerly Freightliner LLC)" 26 "General Motors Corp, Service Technology Grp" 27 "GMC" 28 "Grote Ind. Inc." 29 "Hino Motors Ltd." 30 "Isuzu Motors Ltd" 31 "J Pollak Corp" 32 "Jacobs Vehicle Systems" 33 "John Deere" 34 "Kelsey Hayes Co." 35 "Kenworth Truck Co." 36 "Lucas Ind." 37 "Mack Trucks Inc." 38 "Micro Processor Systems Inc." 39 "Microfirm Inc." 40 "Motorola AIEG Inc." 41 "Motorola Inc." 42 "International Truck and Engine Corporation - Engine Electronics (formerly Navistar Intl Trans Co., Engine Electronics)" 43 "International Truck and Engine Corporation - Vehicle Electronics (formerly Navistar Intl Trans Corp.)" 44 "Nippondenso Co. Ltd." 45 "PACCAR" 46 "Noregon Systems, LLC (formerly Noregon Systems, Inc)" 47 "Phillips Semiconductor" 48 "Pollak Alphabet" 49 "RE America Inc." 50 "Robert Bosch Corp" 51 "Robert Bosch GmbH" 52 "Meritor Automotive, Inc. (formerly Rockwell Automotive)" 53 "Continental Automotive Systems US, Inc. (formerly Rockwell Land Transportation)" 54 "Meritor Wabco" 55 "Ryder System Inc." 56 "SAIC" 57 "Danfoss (formerly Sauer Sundstrand Co, then Sauer-Danfoss Co)" 58 "SPX Corporation, OTC Div" 59 "VES Inc." 60 "Volvo Trucks North America Inc." 61 "Volvo Truck Corp." 62 "Wabco" 63 "ZF Industries Inc." 64 "Unused (formerly SpectraPrecision Laserplane, then SpectraPhysics)" 65 "MAN Nutzfahrzeuge AG" 66 "John Deere Construction Equipment Division" 67 "John Deere Coffeyville Works (formerly Funk Manufacturing Company)" 68 "Scania" 69 "Trimble Navigation" 70 "Flex-coil Limited" 71 "Vansco Electronics Ltd." 72 "Sisu Corporation" 73 "LeTourneau, Inc." 74 "Eaton Axle-Brake Division" 75 "Deere & Co, Agricultural Division" 76 "unused (formerly Deere & Co, Construction Division)" 77 "Deere Power Systems Group" 78 "Frank W. Murphy Manufacturing, Inc" 79 "Daimler Benz AG - Engine Division (PBM)" 80 "Twin Disc, Inc." 81 "Fire Research Corp." 82 "Bobcat/Ingersoll-Rand (formerly Melroe/Ingersoll-Rand)" 83 "Bendix VORAD Technologies (formerly Eaton VORAD Technologies)" 84 "New Holland UK Limited" 85 "Kohler Co" 86 "C. E. Niehoff & Company" 87 "J.C. Bamford Excavators Ltd (JCB)" 88 "Hemisphere GPS Inc (formerly Satloc Precision GPS)" 89 "Kverneland Group, Electronics Division" 90 "Knorr-Bremse SfN GmbH" 91 "BSG Bodensee Steuergeraete GmbH" 92 "Ag-Chem Equipment Co., Inc." 93 "Perkins Engines Company Ltd." 94 "CNH Industrial N.V. (formerly CNH Global N.V.)" 95 "Pacific Insight Electronics Corp." 96 "Mech@tronic IT GmbH" 97 "Ag Leader Technology, Inc." 98 "PTx Trimble (formerly Mueller-Elektronik GmbH & Co)" 99 "International Transmissions Ltd (ITL)" 100 "VDO Technik AG" 101 "Sensoria" 102 "AGCO (formerly AGCO GmbH & Co.)" 103 "CLAAS E-Systems GmbH (formerly CLAAS E-Systems KGaA mbH & Co. KG)" 104 "CLAAS KGaA mbH (formerly CLAAS Selbstfahrende Erntemaschinen GmbH)" 105 "Kiepe Elektrik GmbH & Co. KG" 106 "BAE Systems Controls, Inc." 107 "Grimme Landmaschinen GmbH & Co. KG" 108 "PTx Trimble (formerly WTK-Elecktronik GmbH, now a duplicate entry; use MFR ID 98)" 109 "TeeJet Technologies Denmark (formerly LH Technologies ApS)" 110 "EPIQ Sensor-Nite" 111 "Bernard Krone Holding SE & Co. KG (formerly Maschinenfabrik Bernard Krone GmbH)" 112 "MECALAC" 113 "Stress-Tek, Inc." 114 "EControls, Inc." 115 "NACCO Materials Handling Group, Inc." 116 "BEELINE Technologies" 117 "HUSCO International" 118 "Intron GmbH" 119 "IntegriNautics" 120 "RDS Technology Ltd" 121 "HED (Hydro Electronic Devices, Inc.)" 122 "FG Wilson (Engineering) Limited" 123 "Basler Electric" 124 "Hydac Electronic" 125 "Nevada Automotive Test Center" 126 "Driver Tech" 127 "Holland USA" 128 "Gerhard Duecker GmbH & Co. KG" 129 "OMNEX Control Systems Inc." 130 "Nido - Universal Machines B.V." 131 "ITT Industries" 132 "Mulag-Fahrzeugwerk" 133 "Bucher Schoerling GmbH" 134 "Iris Technology Ltd" 135 "Airmar Technology Corporation" 136 "Komatsu Ltd" 137 "Maretron" 138 "Georg Fritzmeier GmbH & Co. KG" 139 "Caterpillar Trimble Control Technologies (CTCT), LLC" 140 "Lowrance Electronics, Inc." 141 "Thales Navigation Ltd." 142 "TRW Automotive (Commercial Steering Systems)" 143 "W. Gmeiner GmbH & Co." 144 "Mercury Marine" 145 "MurCal Controls" 146 "Maxima Technologies" 147 "Nautibus electronic GmbH" 148 "Blue Water Data, Inc." 149 "Holset" 150 "Fleetguard" 151 "Raven Industries, Inc." 152 "elobau GmbH & Co. KG" 153 "Woodward, Industrial Controls Division" 154 "Westerbeke Corporation" 155 "Vetronix Corporation" 156 "ITT Industries - Cannon" 157 "ISSPRO Inc." 158 "Firestone Industrial Products Company" 159 "NTech Industries Inc" 160 "Nido" 161 "Offshore Systems (UK) Ltd" 162 "Axiomatic Technologies" 163 "BRP Inc." 164 "MTU Friedrichshafen GmbH (formerly DaimlerChrysler Off-Highway)" 165 "CPAC Systems AB" 166 "John Deere Electronic Solutions (formerly Phoenix International)" 167 "JLG Industries Inc" 168 "Xantrex" 169 "Marlin Technologies Inc." 170 "Computronics Corporation Ltd." 171 "Topcon Electronics GmbH & Co. KG (formerly Wachendorff Elektronik GmbH & Co. KG)" 172 "Yanmar Co., Ltd. (formerly Yanmar Marine USA)" 173 "Ryeso, Inc." 174 "AB Volvo Penta" 175 "Veris Technologies, Inc." 176 "Moritz Aerospace" 177 "Diagnostic Systems Associates" 178 "Continental Automotive GmbH (formerly Siemens VDO Automotive AG)" 179 "TeeJet Technologies Springfield (formerly Midwest Technologies Illinois, LLC)" 180 "Smart Power Systems" 181 "Coretronics, Inc." 182 "Vehicle Systems Engineering B.V." 183 "KDS Controls, Inc" 184 "EIA Electronics" 185 "Beede Electrical Instrument Company" 186 "Altronic, Inc" 187 "Air-Weigh" 188 "EMP Corp" 189 "QUALCOMM" 190 "Hella KGaA Hueck & Co" 191 "XRS Corporation (formerly XATA Corporation)" 192 "Floscan" 193 "Jeppesen Marine" 194 "TriMark Corporation" 195 "General Engine Products" 196 "LEMKEN GmbH & Co KG" 197 "Mechron Power Systems" 198 "Mystic Valley Communications" 199 "ACTIA Group (formerly Actia Corp)" 200 "MGM Brakes" 201 "Disenos y Tecnologia S.A." 202 "Curtis Instruments, Inc" 203 "MILtronik GmbH" 204 "The Morey Corporation" 205 "SmarTire Systems Inc" 206 "port GmbH" 207 "Otto Engineering" 208 "Drew Technologies, Inc" 209 "Bell Equip. Co. SA (PTY) LTD" 210 "Iteris, Inc." 211 "DNA Group" 212 "Sure Power Industries, Inc" 213 "CNH Belgium N.V." 214 "MC elettronica Srl" 215 "Aetna Engineering/Fireboy-Xintex" 216 "Paneltronics Inc." 217 "RM Michaelides Software & Elektronik GmbH" 218 "Gits Manufacturing Company" 219 "Cat OEM Solutions" 220 "Beede Electrical Instrument Company, Inc" 221 "SiE" 222 "Generac Power Systems, Inc." 223 "Vaueo Retarder Co., Ltd." 224 "EMMI Network, S.L." 225 "SKF" 226 "Monaco Coach Corporation" 227 "Lykketronic A/S" 228 "Unused (formerly ZF Marine Electronics)" 229 "Garmin International Inc." 230 "Saucon Technologies" 231 "Topcon Positioning Systems, Inc." 232 "TSD Integrated Controls" 233 "Yacht Monitoring Solutions Inc." 234 "Mondial electronic GmbH" 235 "SailorMade Marine Telemetry - Tetra Technology Ltd." 236 "NORAC Systems International Inc" 237 "Agtron Enterprises Inc" 238 "ZF Friedrichshafen AG" 239 "May & Scofield Ltd" 240 "Vanair Mfg" 241 "Schneider Automation SAS" 242 "Kokusandenki Co. Ltd" 243 "eRide, Inc." 244 "Techno-Matic" 245 "Capstan Ag Systems, Inc." 246 "Class 1, Inc" 247 "ePULSE" 248 "Cooper Standard Automotive Active Systems Group" 249 "Schaltbau GmbH" 250 "Kuhn Group" 251 "German Agricultural Society, Test Center (DLG)" 252 "Sensor-Technik Wiedemann GmbH" 253 "Mobile Control Systems" 254 "GE Sensing" 255 "MEAS France" 256 "Tyco Electronics AMP" 257 "Honda Motor Co., Ltd" 258 "ARAG" 259 "Bucher Automation AG (formerly Jetter AG)" 260 "Reichhardt GmbH Steuerungstechnik" 261 "Red Dot Corporation" 262 "HydraForce, Inc" 263 "IMMI" 264 "Autolync" 265 "MTS Sensor Technologie GmbH" 266 "International Thermal Research Ltd" 267 "Red Lion Controls, Inc" 268 "Accurate Technologies" 269 "Saft America Inc., Space & Defense Division" 270 "Tennant" 271 "Cole Hersee" 272 "Gross Mechanical Laboratories, Inc" 273 "Active Research Limited" 274 "LTW Technology Co., LTD" 275 "Navico Egersund AS" 276 "Aqua-Hot Heating Systems" 277 "LHP Telematics" 278 "Takata Electronics" 279 "Geometris LP" 280 "Leica Geosystems Pty Ltd" 281 "Precision Governors LLC" 282 "Medallion Instrumentation Systems" 283 "CWF Hamilton & Co Ltd" 284 "Mobile Tech Chile" 285 "Sea Recovery Corp" 286 "Coelmo srl" 287 "NTech Industries, Inc" 288 "Mitsubishi FUSO Truck & Bus Corp." 289 "Watlow" 290 "Kuebler GmbH" 291 "Groeneveld Transport Efficiency BV" 292 "IKUSI - Angel Iglesias S.A." 293 "Spyder Controls Corp." 294 "Grayhill Inc." 295 "BEP Marine" 296 "micro dynamics GmbH" 297 "Zonar Systems Inc" 298 "Holley Performance" 299 "Rauch" 300 "Systron Donner Automotive" 301 "Parker Hannifin (UK) Ltd FDE group" 302 "Nissin Kogyo Co., LTD" 303 "CTS Corporation" 304 "EmpirBus AB" 305 "NovAtel Inc" 306 "Sleipner Motor AB" 307 "MAS Technologies" 308 "Cyntrx" 309 "Krauss-Maffei Wegmann GmbH & Co. KG" 310 "TECNORD srl" 311 "Patrick Power Products" 312 "Lectronix, Inc." 313 "Ilmor Engineering, Inc." 314 "CSM GmbH" 315 "Icom Incorporated" 316 "ITT Flow Control" 317 "Navtronics Bvba" 318 "SAT Plan" 319 "Cadec Global" 320 "Miedema Landbouwwerktuigenfabriek B.V." 321 "Ultra Electronics, Electrics" 322 "MICHENKA s.r.o." 323 "Mobileye Vision Technologies Ltd." 324 "Snap-on Diagnostics" 325 "ASM Automation Sensorik Messtechnik GmbH" 326 "Akron Brass Company" 327 "Sonceboz SA" 328 "Qwerty Electronik AB" 329 "Deif A/S" 330 "Kidde Aerospace and Defense" 331 "Horton, Inc." 332 "HWH Corporation" 333 "Link Manufacturing, Ltd. (formerly Hadley Products Corporation)" 334 "Takata-Petri AG" 335 "Evo Electric Ltd" 336 "APE s.r.o." 337 "Carraro S.p.A." 338 "GRAF-SYTECO" 339 "Competence Center ISOBUS e.V." 340 "Continental AG" 341 "Boning GmbH & Co" 342 "THOMAS MAGNETE GmbH" 343 "Baumer Group" 344 "Parvus Corporation" 345 "Korean Maritime University" 346 "Control Solutions" 347 "Honeywell" 348 "Amazonen Werke H. Dreyer" 349 "Suonentieto" 350 "Noris Marine Systems GmbH & Co KG" 351 "Thrane & Thrane" 352 "SAME DEUTZ-FAHR GROUP S.p.A." 353 "Hegemon Electronics, Inc." 354 "Junkkari OY" 355 "Mastervolt International B.V." 356 "Fischer Panda Generators, Inc" 357 "Hardi International A/S" 358 "Victron Energy B.V." 359 "Ludwig Bergmann GmbH" 360 "HJS Emission Technology GmbH & Co KG (formerly HJS Fahrzeugtechnik GmbH & Co KG)" 361 "InMach" 362 "Poettinger Landtechnik GmbH (formerly Alois Poettinger Maschinenfabrik GmbH)" 363 "BEI Duncan" 364 "OEM Controls Inc." 365 "Digi-Star, LLC" 366 "Viewnyx Corp." 367 "Fliegl Agrartechnik" 368 "HANSENHOF_electronic" 369 "Power Torque Engineering Ltd" 370 "Rolls-Royce Marine AS" 371 "Heinzmann GmbH & Co. KG" 372 "Delphi" 373 "Electronic Design Inc." 374 "Northern Lights, Inc." 375 "Williams Controls Inc." 376 "Quake Global" 377 "ifm electronic gmbh" 378 "Glendinning Marine Products" 379 "Yamabiko Corporation" 380 "Suntech International Ltd." 381 "B & G" 382 "National Agriculture and Food Research Organization" 383 "MCL Industries" 384 "Camano Light" 385 "Johnson Outdoor Marine Electronics" 386 "JLG Automation BVBA" 387 "Orscheln Products, LLC" 388 "Innomatix, LLC" 389 "Benchmark Electronics, Minnesota Division" 390 "Partech Inc." 391 "Electronic Design for Industry, Inc" 392 "Tianyuan Technology Co Ltd." 393 "Harvest Tec, Inc" 394 "Capi 2 Nederland B.V." 395 "GENTEC S.R.L." 396 "Beyond Measure" 397 "Sanyo-kiki Co Ltd." 398 "Hilite International" 399 "ISEKI & Co., Ltd." 400 "Livorsi Marine" 401 "Torqeedo GmbH" 402 "Simma Software, Inc." 403 "Trackwell ADS, Inc." 404 "Com Nav Marine Ltd" 405 "Wema System AS" 406 "Vecima Networks Inc." 407 "Comtech Mobile Datacom" 408 "Corvus Energy Ltd." 409 "Transfluid S.r.L." 410 "COBO S.p.A. Divisione 3B6" 411 "Hy-Drive Technologies Ltd." 412 "WebTech Wireless Inc." 413 "Datapross Nijbroek bv" 414 "Cattron Group International" 415 "Valid Manufacturing Ltd." 416 "Kubota Corporation" 417 "KZValve" 418 "Intellistick Inc" 419 "Fusion Electronics Ltd" 420 "Vermeer Corporation, ACS Group" 421 "Vertex Standard Co, Ltd" 422 "True Heading AB" 423 "BSM Wireless, Inc." 424 "Odyne LLC" 425 "Methode Electronics Inc, MDI" 429 "Rota Engineering Ltd." 430 "Auteq Telematica S.A." 431 "Tohatsu Corporation" 432 "S&A Systems, Inc." 433 "Rowe Electronics" 434 "Stored Energy Systems" 435 "Zunhammer GmbH" 436 "Kinze Manufacturing" 437 "Digital Yacht Limited" 438 "Comar Systems Ltd" 439 "HD Hyundai (formerly Hyundai Heavy Industries)" 440 "Cummins Power Generation" 441 "PTG Reifendruckregelsysteme GmbH" 442 "HORSCH Maschinen SE & Co. KG (formerly HORSCH Maschinen GmbH)" 443 "SignalQuest, Inc." 444 "ITT Power Solutions" 445 "KAT MECHATRONIC, Electronic Product Division" 446 "CertTech, L.L.C." 447 "Great Plains Mfg." 448 "Stanadyne Corporation, Electronics Systems" 449 "Polaris Industries Inc" 450 "Dycor Technologies Ltd." 451 "Parker Hannifin Corp" 452 "WIKA Alexander Wiegand SE & Co. KG" 453 "Cooper Bussmann" 454 "NGK Spark Plug Co. Ltd" 455 "ADZ NAGANO GmbH" 456 "General Kinetics" 457 "RUSELPROM-ElectricDrive Ltd" 458 "Control Solutions, Inc." 459 "Alltek Marine Electronics Corp" 460 "San Giorgio S.E.I.N." 461 "HAWE Hydraulik SE" 462 "IHI Shibaura Machinery Corporation" 463 "PROBOTIQ" 464 "Leach International Corporation" 465 "Ashcroft Inc" 466 "Veethree Electronics and Marine LLC" 467 "Lely Industries N.V." 468 "Tyco Fire Protection Products" 469 "RA Consulting GmbH" 470 "SI-TEX Marine Electronics" 471 "Sea Cross Marine AB" 472 "Tenneco Inc." 473 "Boss Industries, Inc." 474 "Persen Technologies Inc." 475 "GME" 476 "Hummingbird Marine Electronics" 477 "OilQuick AB" 478 "OceanSat B.V." 479 "Vapor Bus International" 480 "EnerDel, Inc." 481 "Chetco Digital Instruments" 482 "Tricon Electronics" 483 "Valeo" 484 "Headsight Inc." 485 "MATT automotive" 486 "Westport Innovations Inc." 487 "DSE Test Solutions A/S" 488 "The Charles Machine Works, Inc." 489 "Appareo Systems, LLC" 490 "QuikQ" 491 "Penny and Giles Ltd" 492 "Inergy Automotive Systems" 493 "Watcheye" 494 "Synerject" 495 "HOLMER Maschinenbau GmbH" 496 "W. Gessmann GmbH" 497 "SENTRON Sistemas Embarcados" 498 "Innovative Design Solutions, Inc." 499 "LCJ Capteurs" 500 "Oxbo International Corporation" 501 "Agrotronix S.A." 502 "Attwood Corporation" 503 "Naviop S.R.L." 504 "Vesper Marine" 505 "Yetter Farm Equipment" 506 "IHI STAR Machinery Corporation" 507 "ISOBUS Test Center" 508 "Transtech Innovations" 509 "MOTORTECH GmbH" 510 "Marinesoft Co. Ltd" 511 "Sulky" 512 "Inpower LLC" 513 "Precision Technology" 514 "DISTek Integration, Inc." 515 "GINAF Trucks Nederland B.V." 516 "AVAT Automation GmbH" 517 "Noland Engineering" 518 "Transas USA Inc." 519 "Peeters Landbouwmachines b.v." 520 "Trapeze" 521 "Clever Devices Ltd." 522 "Nebraska Tractor Test Laboratory" 523 "Reggio Emilia Innovazione" 524 "Vomax Instrumentation Pty. Ltd." 525 "Rust Sales INC" 526 "LOFA Industries, Inc" 527 "GKN Walterscheid GmbH" 528 "Hoganas AB, Electric Drive Systems" 529 "National Instruments Korea" 530 "NMEA" 531 "Genge & Thoma AG" 532 "Onwa Marine Electronics Co Ltd." 533 "Doran Manufacturing, LLC" 534 "Webasto Thermo & Comfort SE" 535 "MOTORPAL, a.s." 536 "SSI Technologies" 537 "Schrader Electronics Ltd." 538 "Crop Ventures, Inc." 539 "Mobileview" 540 "Dinex A/S" 541 "Total Fire Systems, Inc." 542 "Dinamica Generale s.p.a." 543 "BAUER Maschinen GmbH" 544 "Au Group Electronics" 545 "GS Global Resources (formerly GS Hydraulics)" 546 "Maruyama Mfg Co, Inc." 547 "Thomson Linear LLC" 548 "TM4 Inc." 549 "ROAD Deutschland GmbH" 550 "SUN-A Corporation" 551 "Wexler CSD Ltd." 552 "Matsuyama Plow Mfg Co, Ltd" 553 "KIB Electronics" 554 "iris-GmbH infrared & intelligent sensors" 555 "Sasaki Corporation" 556 "HD Hyundai Infracore Norway (formerly Doosan Infracore Norway)" 557 "Rockson Automation GmbH" 558 "Davis Instruments Corp." 559 "Four Peaks Navigation" 560 "Iowa State University, Agricultural and Biosystems Engineering" 561 "b-plus GmbH" 562 "Bombardier Transportation GmbH" 563 "LOHR Sistemas Eletronicos LTDA" 564 "Auto Power Electronic" 565 "Micro-Trak Systems, Inc." 566 "Geode Technology, Inc." 567 "Lithiumstart LLC" 568 "Makersan Ltd. Co." 569 "LORD MicroStrain Sensing Systems" 570 "frenzel + berg electronic GmbH & Co. KG" 571 "Marinecraft Co., Ltd." 572 "Fasse Valves" 573 "Orolia Ltd" 574 "Vishay Precision Group" 575 "Lytx" 576 "Vectia" 577 "Denchi Power Ltd (formerly ABSL Power Solutions Limited)" 578 "advanSea" 579 "KVH Industries, Inc." 580 "San Jose Technology, Inc." 581 "Väderstad AB" 582 "Innovative Software Engineering" 583 "Yachtcontrol" 584 "CarMedialab GmbH" 585 "Industrial Electronic Controls" 586 "Suzuki Motor Corp" 587 "JCA Electronics" 588 "Vignal Systems" 589 "MICO, Inc." 590 "ARGO-HYTOS GMBH" 591 "United States Coast Guard" 592 "tecsis GmbH" 593 "Sensata Technologies" 594 "Kongsberg Automotive" 595 "CustomWare" 596 "Brunelco Electronic Innovators B.V." 597 "Hydac Filter Systems GmbH" 598 "ABB Turbo Systems Ltd" 599 "Spudnik Equipment Co, LLC" 600 "Aquatic AV" 601 "Navitas Systems" 602 "Nomad Digital Ltd." 603 "Kereval" 604 "Rototilt Group AB (formerly Indexator Rototilt Systems AB)" 605 "Aventics GmbH" 606 "Intellian Technologies" 607 "Knappco/Civacon" 608 "Gale Banks Engineering" 609 "Walvoil S.p.A." 610 "Trail Tech" 611 "Esterline" 612 "Samwon IT" 613 "HKS Co., Ltd." 614 "ARLT Technologies GmbH" 615 "Networkfleet, Verizon Telematics" 616 "SMART-TEC s.r.o." 617 "Zero Emission Vehicles" 618 "Evrard SA" 619 "Right Weigh Load Scales" 620 "BorgWarner Inc. (formerly Sevcon Ltd.)" 621 "Hagie Manufacturing Company" 622 "Floyd Bell Inc" 623 "Xirgo Technologies" 624 "Blackbox Machine Control Pty Ltd" 625 "Global MRV Inc." 626 "AVL DiTEST GmbH" 627 "Radio Ocean" 628 "Falck Schmidt Defence Systems" 629 "Agri Info Design, Ltd." 630 "SmartDrive Systems Inc." 631 "Reltima" 632 "Pepperl+Fuchs GmbH" 633 "TORC Robotics" 634 "Rocky Research" 635 "Argo Tractors S.p.A." 636 "Divelbiss Corporation" 637 "Bavaria Yachtbau GmbH" 638 "KVH Industries, Inc." 639 "Startec s.r.l." 640 "Power Solutions International" 641 "Diverse Yacht Services" 642 "Moog / Aspen Motion Technologies" 643 "Bogballe A/S" 644 "KUS USA" 645 "esd electronic system design gmbh" 646 "Veenhuis Machines B.V." 647 "Siloking" 648 "OJSC Ekran" 649 "Control-Q B.V." 650 "Seiko Epson Corp." 651 "Takakita Co, Ltd." 652 "MicroControl GmbH & Co. KG" 653 "AEV, spol. s r. o." 654 "Kohler Power Systems, Detroit Engine Development Center (DEDC)" 655 "Genge & Thoma AG" 656 "PRO SOLUS do Brasil" 657 "Terzo Power Systems" 658 "Shenzhen Jiuzhou Himunication Technology Co., Ltd" 659 "Data Panel Corp." 660 "Auto-Gaz Centrum" 661 "SPAL Automotive S.r.l." 662 "Kissling Elektrotechnik GmbH" 663 "Delta Systems, Inc" 664 "Level Developments Ltd" 665 "Gebr. Bode GmbH & Co. KG" 666 "Schaeffler Technologies AG & Co., KG" 667 "Bartec" 668 "MacDon Industries Ltd." 669 "Quantum Fuel Systems Technologies Worldwide, Inc" 670 "STEMCO LP" 671 "Innovative Controls Inc." 672 "OPTIMA Concept" 673 "Caruelle Nicolas" 674 "Yara International ASA" 675 "Kawasaki Motors, Ltd. (formerly Kawasaki Motors Corp., USA)" 676 "Danfoss IXA A/S" 677 "DSA Daten- und Systemtechnik GmbH" 678 "KeepTruckin, Inc." 679 "OXE Marine AB (formerly Cimco Marine AB)" 680 "AMVAC Chemical Corporation" 681 "BEDIA Motorentechnik GmbH & Co. KG" 682 "Eckelmann AG" 683 "Fosen Elektro" 684 "KEB" 685 "ANEDO (formerly ANEDO Ltd.)" 686 "Taigene Electric Machinery Corp." 687 "Flight Systems, Inc." 688 "Rockford Corp" 689 "Aarcomm Systems Inc" 690 "LINAK A/S" 691 "Digitroll Agricultural Electronics" 692 "Tanhay Corporation" 693 "Agility Fuel Solutions (formerly Agility Fuel Systems)" 694 "GasTOPS Ltd." 695 "Weldon Technologies" 696 "DRS Network & Imaging Systems, LLC (DRS Technologies)" 697 "JOST Umeå AB (formerly Ålö AB)" 698 "Scorpion Technologies Ltd." 699 "Harman International (formerly Harman International Industries)" 700 "K-Tec Earthmovers Inc." 701 "BigRoad Inc." 702 "Weichai Power Co., Ltd." 703 "Hydro Tab Marine Engineering" 704 "JL Audio, Inc." 705 "SVAB Hydraulik AB" 706 "Shanghai Diesel Engine Corporation Limited" 707 "Rochester Gauges Inc" 708 "Lars Thrane A/S" 709 "Marquardt GmbH" 710 "Greentronics Ltd." 711 "DAS Co., LTD" 712 "LOR Manufacturing Company Inc." 713 "US Hybrid Corporation" 714 "Kobashi Kogyo Co., Ltd." 715 "Autonnic Research Ltd" 716 "Eaton Control & Power Conversion Division (CPCD)" 717 "Yacht Devices Ltd" 718 "Micronet Inc" 719 "Cojali S. L." 720 "WITZ Corporation" 721 "Hypro" 722 "Contelec AG" 723 "Jabil Inc." 724 "Electronic Applications, Inc." 725 "Hitachi Construction Machinery Co., Ltd." 726 "MIDORI PRECISIONS" 727 "Dhoot Transmission Pvt Ltd." 728 "Streumaster (formerly Streumaster / Panien)" 729 "Liebherr" 730 "BERTHOUD AGRICOLE" 731 "Modine Manufacturing Company" 732 "Gefran S.p.A." 733 "Intendia S.L." 734 "REAPsystems" 735 "AEM Performance Electronics" 736 "Terex Aerial Work Platforms - Genie" 737 "Balluff GmbH" 738 "Blue Ink Technologies" 739 "LXNAV d.o.o." 740 "e-Traction" 741 "Carling Technologies" 742 "EROAD" 743 "Daemyung Elevator Co., Ltd." 744 "Woosung Engineering Co., Ltd." 745 "Cidra Corporate Services Inc." 746 "SurePoint Ag Systems (formerly SureFire Ag Systems, Inc.)" 747 "Agratronix" 748 "ISOTTA" 749 "Chart Inc." 750 "Joskin SA" 751 "Pacific Track" 752 "Deep Sea Electronics Plc" 753 "AIROD Technologies" 754 "Parker Hannifin Corp., Automation Group" 755 "Firefly Integrations" 756 "Maschio Gaspardo S.P.A." 757 "IMPCO Technologies" 758 "Banner Engineering Corp." 759 "Hydro-Gear" 760 "Bernecker + Rainer Industrie Elektronik GmbH" 761 "MITA OLEODINAMICA S.p.A." 762 "ROJ s.r.l." 763 "AT-Systems BVBA" 764 "Bednar FMT s.r.o." 765 "GIGAVAC" 766 "Epec Oy" 767 "Alliance Wireless Technologies Inc." 768 "Flores Automation, LLC" 769 "Trombetta" 770 "MONOSEM" 771 "Shaw Development, LLC" 772 "Blink Marine" 773 "Clarion Corporation of America" 774 "Taisho Corporation" 775 "ZIEHL-ABEGG Automotive GmbH" 776 "HMI Systems LLC" 777 "Ocean Signal Ltd" 778 "Seakeeper Inc." 779 "RLC Electronic Systems" 780 "Turntide Transport Limited (formerly AVID Technology Ltd)" 781 "Poly-Planar LLC" 782 "AVR nv" 783 "Loup Electronics Inc." 784 "CM Automotive Systems, Inc." 785 "Fischer Panda GmbH" 786 "Johnson Matthey Battery Systems" 787 "Abertax Technologies Limited" 788 "MoTeC Pty Ltd" 789 "GRADALL" 790 "VACALL" 791 "AUTEC" 792 "Kostal Mexicana" 793 "James Fisher Prolec" 794 "Shihlin Electric & Engineering Corporation" 795 "Broyda Enterprises Pty Ltd" 796 "Canadian Automotive Industries Ltd" 797 "Tides Marine" 798 "Lumishore Ltd" 799 "Stillwater Designs and Audio, Inc. - KICKER" 800 "Delta-Q Technologies" 801 "LOR Manufacturing Company Inc." 802 "SPBI (Bj Technologie)" 803 "Gill Sensors & Controls Limited" 804 "ASA Electronics" 805 "Gundersen & Løken AS" 806 "Charge Automotive Ltd" 807 "Schneider-Electric" 808 "RIMEX Supply Ltd." 809 "HMS Industrial Networks AB" 810 "Dutch Power Company" 811 "Blue Water Desalination" 812 "Torch Technologies" 813 "Thales Suisse SA" 814 "Kronotech Srl (formerly Soltec Soluzioni Tecnologiche Srl)" 815 "FLIR Systems, Inc." 816 "UniStrong" 817 "TE Connectivity Sensor Solutions" 818 "HGNSS" 819 "Preco Electronics" 820 "DIaLOGIKa Gesellschaft fuer angewandte Informatik mbH" 821 "Thorsen Teknik A/S" 822 "Bren-Tronics, Inc." 823 "ACEINNA, Inc (formerly MEMSIC, Inc)" 824 "Undheim Systems AS" 825 "BPW Hungária" 826 "Lewmar Marine Inc" 827 "INmatix Technology Group Ltd" 828 "AgriBrink Inc." 829 "Drov Technologies, Inc." 830 "Ultra Motion LLC" 831 "DOK-ING Ltd." 832 "Heizomat Gerätebau-Energiesysteme GmbH" 833 "Electrum Automation AB" 834 "Pioneer Microsystems, Inc." 835 "PetTrack Ltd." 836 "Signature4" 837 "Famic Technologies Inc." 838 "Teamsurv Ltd" 839 "Indexator Rotator Systems AB" 840 "E.S.T.E. srl" 841 "Agra-GPS" 842 "DigiDevice Srl" 843 "Hendrickson Truck Commercial Vehicle Systems" 844 "FELL AS" 845 "GMB Güstrower Maschinenbau GmbH" 846 "L3 Magnet-Motor" 847 "Oceanvolt" 848 "ningupex" 849 "MTS Maschinentechnik Schrode AG" 850 "Geoprospectors GmbH" 851 "Novotechnik Messwertaufnehmer OHG" 852 "Velvac Inc" 853 "Teledyne RESON B.V." 854 "GEMAC Chemnitz GmbH" 855 "Toshiba Infrastructure Systems & Solutions Corporation" 856 "FarmFacts GmbH" 857 "Zoomlion Heavy Industry NA, Inc" 858 "Littelfuse" 859 "Valor" 860 "Michelin" 861 "Adel System S.r.l." 862 "Prospec Electronics" 863 "SMAG" 864 "Streamline Transportation Technologies Inc." 865 "MyEasyFarm" 866 "Netradyne, Inc." 867 "Skeleton Technologies" 868 "Data Panel Corp" 869 "Intercomp" 870 "Textron Fleet Management" 871 "Agri-Fab (formerly Superior Tech Inc)" 872 "Kählig Antriebstechnik GmbH" 873 "Garnet Instruments Ltd." 874 "MTA S.p.A." 875 "Salvarani S.r.l." 876 "SUCO Robert Scheuffele GmbH & Co. KG" 877 "SICK ATech GmbH" 878 "FOTON" 879 "PG Trionic, Inc." 880 "Revision Military" 881 "Sovema" 882 "BHTronik GmbH & Co. KG" 883 "Swift Navigation, Inc." 884 "Sure Grip Controls Inc." 885 "SICK AG (formerly SICK Stegmann GmbH)" 886 "Hitachi Zosen Corporation" 887 "Turntide Transport Limited (formerly Hyperdrive Innovation Limited)" 888 "Carma Systems Inc" 889 "SANY America Inc" 890 "L3 Technologies, Inc." 891 "CarrierWeb" 892 "Mectronx Corp" 893 "KlinkTechnics Ltd." 894 "Rhodan Marine Systems of Florida LLC (Duplicate entry; use MFR ID 1012)" 895 "Peloton Technology" 896 "NextFour Solutions Ltd" 897 "Dot Technology Corp." 898 "Josef Kotte Landtechnik GmbH & Co. KG" 899 "Lippert Components, Inc" 900 "OSB connagtive GmbH (formerly OSB AG)" 901 "Zivan Srl" 902 "Bucher Hydraulics" 903 "InMotion" 904 "Equipment Safety Systems Pty. Ltd. (EQSS)" 905 "ASA Electronics" 906 "MOBA AG" 907 "strautmann" 908 "Chonbuk National University Department of Electronics" 909 "Marines Co., Ltd." 910 "Hermann Paus Maschinenfabrik GmbH" 911 "Nautic-On" 912 "Steyr Motors GmbH" 913 "Toyota Motor Corporation" 914 "ZETOR TRACTORS a.s." 915 "Dosificacion y sistemas electronicos S.L. (DSE)" 916 "Hans Turck GmbH & Co. KG (formerly Turck Inc.)" 917 "Sentinel d.o.o." 918 "AMW Machine Control, Inc" 919 "Furrion LLC" 920 "MTD Consumer Group Inc." 921 "ROPA Fahrzeug- und Maschinenbau GmbH" 922 "Terberg Benschop B.V." 923 "ELTEK S.p.A." 924 "PAS Peschak Autonome Systeme GmbH" 925 "GW Lisk Company" 926 "Buhler Industries Inc." 927 "Saicon" 928 "EAO Automotive GmbH & Co. KG" 929 "Jl Marine Systems, Inc." 930 "Ecotronix Corp." 931 "Enertec Marine Ltd" 932 "Discover Battery" 933 "Delta Mobile Systems, Inc." 934 "Farmobile, Inc." 935 "Meels GmbH & Co. KG" 936 "Hi-tech Millennium" 937 "Precision Circuits Inc" 938 "LEVEL Systems" 939 "Warn Industries, Inc." 940 "Dometal Oy" 941 "Navya" 942 "Vogelsang GmbH & Co. KG" 943 "FISCHER AG Präzisionspindeln" 944 "ZONTISA Marine SL" 945 "Equalizer AG" 946 "Hydac Tecnologia Ltda" 947 "Gerd Bär GmbH" 948 "Donix" 949 "Škoda Electric a.s." 950 "RE:Lab s.r.l." 951 "Exor International S.p.A." 952 "Tan Delta Systems Ltd" 953 "Curtiss-Wright" 954 "Setec Pty Ltd" 955 "Hottinger Baldwin (Suzhou) Electronic Measurement Technology Co., Ltd." 956 "Piher Sensors & Controls S.A." 957 "Sierra Wireless Inc" 958 "NHK MEC Corporation" 959 "Cascade Corporation" 960 "Vemcon GmbH" 961 "POK SAS" 962 "Timbolier Industries, Inc." 963 "Thomason Jones Company, LLC" 964 "AgroVIR Kft" 965 "Ro-Sys Software" 966 "VisibleFarm" 967 "Moteck Electric Corp." 968 "Cox Powertrain Limited" 969 "Blue Sea Systems" 970 "Jaboni Power Products, LLC" 971 "B+B Smartworx" 972 "Axion AG" 973 "Zasso GmbH" 974 "Pico Technology Limited" 975 "Siemens AG" 976 "Derive Systems, Inc." 977 "Copeland LP (formerly Emerson Electric Co.)" 978 "Canfield Connector" 979 "McHale" 980 "Gussi Italia S.R.L." 981 "Kobelt Manufacturing Co. Ltd" 982 "Briggs & Stratton Corporation" 983 "Dezwaef NV" 984 "E-T-A Elektrotechnische Apparate GmbH" 985 "NLR, LLC" 986 "AAMP Global" 987 "Baltic Car Equipment" 988 "Voith Turbo" 989 "Flux-Geräte GmbH" 990 "SAMSUNG SDI Co., Ltd." 991 "Deutronic Elektronik GmbH" 992 "MarineIOT LLC" 993 "Alelion Energy Systems AB" 994 "Morris Industries Ltd." 995 "Circuitlink Pty Ltd." 996 "Eniquest Pty Ltd" 997 "Xenta Systems Srl" 998 "Transcell Technology Inc" 999 "TerraTroniq B.V." 1000 "Landmaschinen Wienhoff GmbH" 1001 "Cleral Inc." 1002 "Kussmaul Electronics Co." 1003 "technotrans SE" 1004 "Ultraflex SpA" 1005 "TSE Brakes, Inc." 1006 "Proterra" 1007 "Maschinenfabrik Meyer-Lohne GmbH" 1008 "Lintest Systems LLC" 1009 "TouchTronics, Inc." 1010 "Agricultural Industry Electronics Foundation e.V." 1011 "Soundmax Electronics Ltd" 1012 "Rhodan Marine Systems of Florida LLC" 1013 "Allochis E-Tec" 1014 "Briri Maschinenbau GmbH" 1015 "SECURITAG SAS" 1016 "Röhren- und Pumpenwerk BAUER GmbH" 1017 "Caldaro AB" 1018 "Flex TTS" 1019 "Codek Foundries" 1020 "Onyx Marine Automation s.r.l." 1021 "Entratech Systems LLC" 1022 "ITC Inc" 1023 "PEAK-System Technik GmbH" 1024 "Inventus Power" 1025 "eze System, Inc." 1026 "ZTR Control Systems, LLC" 1027 "Goldacres PTY LTD" 1028 "Autel Intelligent Technology Corp., Ltd" 1029 "The Marine Guardian LLC" 1030 "Tume-Agri Oy" 1031 "Flintec UK Ltd." 1032 "SIMOL S.p.A." 1033 "ECCO Safety Group" 1034 "Siren Marine" 1035 "Agres" 1036 "Bender GmbH & Co. KG" 1037 "Dragonfly Energy Corp." 1038 "EMIT Technologies, Inc." 1039 "Liugong Dressta Machinery" 1040 "BPE Electronics Srl" 1041 "EZ Lynk" 1042 "engcon group" 1043 "Hyva" 1044 "Xee" 1045 "CMR Group" 1046 "Praxidyn" 1047 "Sonic Corporation" 1048 "Agrivation UG" 1049 "S&S Cycle" 1050 "Spacenus GmbH" 1051 "ProNav AS" 1052 "Pfreundt" 1053 "Vetus Maxwell, Inc." 1054 "Schmotzer Hacktechnik GmbH & Co. KG" 1055 "EXA Computing GmbH" 1056 "Lithium Pros" 1057 "EquipmentShare" 1058 "Bondioli & Pavesi SpA" 1059 "Boatrax" 1060 "Scale-Tec" 1061 "Volvo Construction Equipment" 1062 "Marol Co Ltd" 1063 "SolSteer" 1064 "Omnitech Robotics Inc." 1065 "CALYPSO Instruments" 1066 "Spot Zero Water" 1067 "Tecomec S.r.l." 1068 "Zapi S.p.A." 1069 "Lithionics Battery LLC" 1070 "Quick-teck Electronics Ltd" 1071 "MACH SYSTEMS s.r.o." 1072 "La Marche Manufacturing Company" 1073 "Manitou Equipment America LLC" 1074 "Kindhelm / Navigs Oy" 1075 "Uniden America Corporation" 1076 "DOGA S.A." 1077 "Ymer Technology" 1078 "GE Appliances" 1079 "Carl Zeiss Spectroscopy GmbH" 1080 "Epsilor-Electric Fuel Ltd." 1081 "Imcon Electronics, s.r.o." 1082 "TÜMOSAN Engine and Tractor Co." 1083 "Nauticoncept" 1084 "Shadow-Caster LED lighting LLC" 1085 "Wet Sounds, LLC" 1086 "Life Racing Ltd" 1087 "ITPhotonics S.r.l." 1088 "E-T-A Circuit Breakers" 1089 "Carrosserie HESS AG" 1090 "E-T-A Circuit Breakers Ltd" 1091 "Wheel Monitor Inc." 1092 "Scheiber" 1093 "innolectric" 1094 "Tokushu Denki" 1095 "WEG Drives and Controls - Automação Ltda" 1096 "Texense Sensors" 1097 "M2M Craft Co., Ltd" 1098 "Preh GmbH" 1099 "MadgeTech, Inc" 1100 "LINK Marine Technologies (formerly Smart Yachts International Limited)" 1101 "DIS Sensors B.V." 1102 "Carl Geringhoff GmbH & Co. KG" 1103 "Diesel Laptops" 1104 "The Toro Company" 1105 "Redekop Manufacturing" 1106 "Great Dane LLC" 1107 "Dräger Safety" 1108 "ORBCOMM" 1109 "Dockmate" 1110 "Analytic Systems Ware (1993) Ltd." 1111 "SEPPI M." 1112 "Bollinger Motors" 1113 "iVolve Pty Ltd" 1114 "Bob's Machine" 1115 "Gems Sensors & Controls" 1116 "HR Agrartechnik GmbH" 1117 "LG Chem, Ltd" 1118 "L3Harris ASV" 1119 "Balmar LLC" 1120 "Elettromedia s.r.l." 1121 "Platform Science" 1122 "GT Inc." 1123 "QP Hydraulics" 1124 "Fortron Agriculture" 1125 "Griffith-Elder & Co. Ltd." 1126 "Auralix" 1127 "ElectroMaax" 1128 "Citoon Electronic Technology (Tianjin) Co., Ltd." 1129 "Spectrolytic GmbH" 1130 "Vitesco Technologies" 1131 "Guliwer electronics s.r.o." 1132 "Tokachi Zaidan" 1133 "MEGATRON Elektronik GmbH & Co. KG" 1134 "Master Schools at Ostbahnhof" 1135 "Japan Aviation Electronics Industry, Limited" 1136 "Primosensor GmbH" 1137 "SIKO GmbH" 1138 "Micro-Sensor GmbH" 1139 "ASP Technology" 1140 "Across Oceans Systems Ltd." 1141 "MRS Electronic GmbH & Co. KG" 1142 "Truma" 1143 "Elektro-Szoft 2000" 1144 "Troo Corporation" 1145 "Kiwi Yachting" 1146 "Rometron" 1147 "Dana Inc." 1148 "Stercom Power Solutions GmbH" 1149 "Wuxi Shengbang Electronics Co., Ltd" 1150 "BSB Artificial Intelligence GmbH" 1151 "Orca Technologies AS" 1152 "Vredo Dodewaard B.V." 1153 "Kawasaki Heavy Industries, Ltd." 1154 "TBS Electronics BV" 1155 "LACOS GmbH (formerly LACOS Computerservice GmbH)" 1156 "Nokian Tyres" 1157 "Carriergistics" 1158 "Technoton Electronics" 1159 "Bel Power Solutions" 1160 "MG Energy Systems B.V." 1161 "Griessbach GmbH" 1162 "PEL-tuote Oy" 1163 "DFX Technologies LLC" 1164 "SEG Automotive" 1165 "InnoTotal AB" 1166 "Wachendorff Automation GmbH & Co. KG" 1167 "Tevva Motors" 1168 "Masats S.A." 1169 "Sea Machine Robotics Inc." 1170 "Poseidon Ocean Systems Ltd." 1171 "Vista Manufacturing" 1172 "Hyzon Motors" 1173 "philippi elektrische systeme gmbh" 1174 "Agricon GmbH" 1175 "MAGTEC Products, Inc." 1176 "Asuns Corp." 1177 "RNG International Inc." 1178 "ERO GmbH" 1179 "QS Control srl" 1180 "Murata Power Solutions Inc." 1181 "Banjo Corporation" 1182 "Rottmann Automation" 1183 "Zipwake AB" 1184 "AMA S.p.A." 1185 "WFCO Electronics" 1186 "Sailmon BV" 1187 "TiTAN-Project LLC" 1188 "G-SNS" 1189 "Autotrasporti Cavallo G&V" 1190 "Sirros IoT" 1191 "Pacoma USA, Inc." 1192 "Airmoniq Pro Kft." 1193 "emotas embedded communication GmbH" 1194 "Sierra Marine" 1195 "düvelsdorf" 1196 "Terra Care GmbH" 1197 "SOLGE Corporation" 1198 "ComLink Equipamentos Eletrônicos Ltda" 1199 "ELEO Technologies B.V." 1200 "Xinuo Information Technology (Xiamen) Corporation Limited" 1201 "Emisense Technologies, LLC" 1202 "OSCAR ELECTRONICS SRL (formerly OSCAR Elettronica)" 1203 "Equipment Technologies, Inc." 1204 "Miller Technology Incorporated" 1205 "Carbon Autonomous Robotic Systems" 1206 "STE Solutions B.V." 1207 "UEC Electronics" 1208 "Afflield Kft. (MachineryGuide)" 1209 "Bauser GmbH & Co. KG" 1210 "Ambra Solutions" 1211 "Kiwon Electronics Co., Ltd." 1212 "TAO Performance Limited" 1213 "Apollo Tyres Ltd" 1214 "Element 1" 1215 "Power Control Systems" 1216 "SMP Poland sp. z o.o." 1217 "FSG Fernsteuergeräte Kurt Oelsch GmbH" 1218 "Septentrio" 1219 "Weidmueller Interface GmbH & Co. KG" 1220 "Catamaran Electronics LLC" 1221 "Norcold Inc." 1222 "Tough Tech Ltd." 1223 "Toyo Agricultural Machinery Manufacturing Co., Ltd." 1224 "Neuser Elektrotechnik GmbH" 1225 "SeedMaster Manufacturing Ltd." 1226 "Piippo Hydraulic" 1227 "YAHATA Co., Ltd." 1228 "INTILION GmbH" 1229 "Arcon Designs, LLC" 1230 "Nick Abbey Digital Agriculture Ltd" 1231 "Excidor AB" 1232 "Treffler Maschinenbau GmbH & Co. KG" 1233 "nke Marine Electronics" 1234 "American Battery Solutions" 1235 "NESAN Automotive Inc." 1236 "Agrosystem" 1237 "Changzhou Lambda Electronic Co., Ltd" 1238 "Honda Electronics Co., Ltd" 1239 "SuperTrack Aps" 1240 "TiMOTION" 1241 "Ineo Systrans" 1242 "Super Start Batteries" 1243 "AvMap S.r.l." 1244 "Planti Center" 1245 "Raritan Engineering Company, Inc" 1246 "Rother Industries & Technology" 1247 "GRIFA" 1248 "O.M.F.B. S.p.A. Hydraulic Components" 1249 "Integrated Power Solutions AG" 1250 "ELHO" 1251 "Valmet Automotive EV Power Ltd" 1252 "APV - Technische Produkte GmbH" 1253 "Trafag AG" 1254 "ARADEX AG" 1255 "Altec Industries, Inc." 1256 "Dimensions Agri Technologies AS" 1257 "KOSTAL" 1258 "AGC Technologies" 1259 "Grayson Automotive Services Limited" 1260 "Interactive Technologies, Inc." 1261 "AgXeed" 1262 "Fort Robotics" 1263 "BOS Balance of Storage Systems AG" 1264 "Microelect" 1265 "IPETRONIK GmbH & Co KG" 1266 "Hyundai Doosan Infracore" 1267 "Wacker Neuson SE" 1268 "Back 40 Precision Inc." 1269 "VIS Hydraulics s.r.l." 1270 "Versalift Denmark A/S" 1271 "Raven Connected" 1272 "Samsara Inc." 1273 "Clearflame Engines Inc" 1274 "LDL Technology" 1275 "O.M.P. Officine Mazzocco Pagnoni S.r.l." 1276 "Aspin Kemp & Associates" 1277 "BMZ Germany GmbH" 1278 "Comrod Communication Group" 1279 "Ognibene Power S.p.A." 1280 "SANTEST CO., LTD." 1281 "iQuus" 1282 "COTEK ELECTRONIC IND. CO., LTD" 1283 "LTG Tech" 1284 "Robot Makers GmbH" 1285 "Graco Inc." 1286 "NEXAT GmbH" 1287 "Spartan Radar" 1288 "ANELLO Photonics" 1289 "Loadrite (Auckland) Ltd." 1290 "WaveTamer Partners LLC" 1291 "Forward Thinking Systems LLC" 1292 "SUMITOMO CONSTRUCTION MACHINERY Co., Ltd." 1293 "POSITAL" 1294 "TR-Electronic GmbH" 1295 "SIP d.d." 1296 "Hexagon" 1297 "Micro-Epsilon Messtechnik GmbH & Co. KG" 1298 "SFOGGIA Agriculture Division S.r.l." 1299 "Energy Solutions" 1300 "Watt Fuel Cell Corporation" 1301 "Tecumseh do Brasil Ltda" 1302 "ProMariner" 1303 "Carbon Bee AgTech" 1304 "Palfinger Europe GmbH" 1305 "dragonfly Energy" 1306 "Koden Electronics Co., Ltd." 1307 "Smart AG Systems" 1308 "Agtecnic" 1309 "Shanghai Zhichuan Electronic Tech Co., Ltd." 1310 "LPL Systems (formerly Loughborough Projects Ltd)" 1311 "Humphree AB" 1312 "Control Devices Pty Ltd" 1313 "United States Army - Ground Vehicle Systems Center" 1314 "Newton Crouch Company, LLC" 1315 "SMPC Technologies Ltd." 1316 "Hinkley Yachts" 1317 "GMM - Global Maritime Management GmbH" 1318 "Atlis Motor Vehicles" 1319 "I/O Controls Corporation" 1320 "Triskel Marine Ltd" 1321 "PATLITE Corporation" 1322 "Movimatica" 1323 "Briter Products, Inc." 1324 "Bourgault Industries" 1325 "OPW (formerly BASE Engineering Inc.)" 1326 "HBC-radiomatic GmbH" 1327 "Frans Vervaet B.V." 1328 "PerPlant ApS" 1329 "IDM S.r.l." 1330 "Warwick Control Technologies" 1331 "Dolphin Charger" 1332 "Fairbanks Scales, Inc." 1333 "xFarm Technologies SA" 1334 "Greer Company" 1335 "CPDEVICE" 1336 "Aegis Power Systems, Inc." 1337 "Barnacle Systems Inc." 1338 "Volta Trucks AB" 1339 "Tillett and Hague Technology Limited" 1340 "ORELTEK Elektronik ve Yazılım Teknolojileri" 1341 "Ag Express Electronics" 1342 "DKE-Data GmbH & Co. KG" 1343 "Heavy Data GmbH" 1344 "Haulotte Group" 1345 "PRIGNITZ Mikrosystemtechnik GmbH" 1346 "Einboeck GmbH" 1347 "Munckhof Fruit Tech Innovators" 1348 "Radian IoT, Inc." 1349 "ANNABURGER Nutzfahrzeug GmbH" 1350 "AGRONETIC" 1351 "Motorenfabrik Hatz GmbH & Co. KG" 1352 "NISHIYAMA Corporation" 1353 "Ocean LED Marine Ltd" 1354 "Técnicas de Electrónica y Automatismos, S.A." 1355 "DROP Agricultura Ltda" 1356 "Nordic Lights Ltd" 1357 "TireCheck" 1358 "Fontaine Fifth Wheel" 1359 "BlueNav" 1360 "Lemca Vision" 1361 "Nantong Saiyang Electronics Co., Ltd." 1362 "Zparq AB" 1363 "Calix AB" 1364 "Yashu Systems" 1365 "JVCKENWOOD Corporation" 1366 "Telemecanique Sensors & Switches" 1367 "Dewulf NV" 1368 "RAD Propulsion Ltd" 1369 "Electric Yacht" 1370 "Emtech S.A." 1371 "First Mode" 1372 "Elco Motor Yachts" 1373 "Centek Industries" 1374 "CASAPPA S.p.A." 1375 "ŠKODA ELECTRIC a.s." 1376 "SUNS International, LLC" 1377 "ABD Solutions" 1378 "Bertini SA" 1379 "Novag SAS" 1380 "ADVES GmbH & Co. KG" 1381 "Dr. Diesel Technologies" 1382 "Thornwave Labs Inc." 1383 "Alpego S.p.A." 1384 "Tecnoseal Foundry S.r.l." 1385 "Pro Charging Systems, LLC" 1386 "Smart Eye AB" 1387 "Radel (Pty) Ltd" 1388 "Nira Technology" 1389 "EVEX Co., LTD" 1390 "FJ Dynamics International Limited" 1391 "AriensCo" 1392 "Phoenix America LLC" 1393 "Powerland Technology Inc" 1394 "Zhejiang Ruixing Electromechanical Technology Co., Ltd." 1395 "MLB Industrial" 1396 "Fast Ag Solutions, LLC" 1397 "SaMASZ Sp. Z o.o." 1398 "Gobius Sensor Technology AB" 1399 "Hans Brantner & Sohn Fahrzeugbaugesellschaft mbH" 1400 "IWN GmbH & Co. KG" 1401 "ROM Communications Inc." 1402 "ComNav Technology Ltd." 1403 "Arco Marine" 1404 "BRUSA HyPower AG" 1405 "TELIG Electronics" 1406 "Lumilex ALT SRL" 1407 "Open-Agriculture" 1408 "Lenco Marine Inc." 1409 "Z Elektronika Kft." 1410 "Allan Equipment Manufacturing Ltd." 1411 "Shanghai Huace Navigation Technology Ltd." 1412 "Naocontrol S.L." 1413 "OHNOH2O LLC" 1414 "INTRACOM DEFENSE S.A." 1415 "Máquinas Agrícolas Jacto S.A." 1416 "Wavetronix LLC" 1417 "Revatek LLC" 1418 "Karluna Engineering" 1419 "iPatch Marine" 1420 "TALOS - Precision Measurement Technologies" 1421 "Clarios, LLC" 1422 "xTCU AG" 1423 "AC S.A." 1424 "Bewis" 1425 "Electronics in Agriculture, School of Engineering, University of Galway" 1426 "Samson Group" 1427 "REITER RESPIRO" 1428 "Samo Maschinenbau GmbH" 1429 "Nikola Corporation" 1430 "Mantracourt Electronics Ltd" 1431 "Nauto Inc." 1432 "MDH Defence Ltd." 1433 "Unicontrol ApS" 1434 "eSurvey GNSS Ltd." 1435 "Heilongjiang Huida Technology Co., Ltd" 1436 "M-extend" 1437 "DOKEN Technology Co. Ltd." 1438 "Aeolionics" 1439 "PredictWind Ltd" 1440 "Egis Mobile Electric" 1441 "Shanghai Allynav Technology Co.,Ltd." 1442 "EVYTRA GmbH" 1443 "SoilEssentials Limited" 1444 "Micropower Group" 1445 "Starboard Yacht Group" 1446 "Roswell Marine" 1447 "Innotag Distributions Inc." 1448 "Elmer's Manufacturing" 1449 "Bontaz Centre" 1450 "Agrivaux" 1451 "Guangdong ePropulsion Technology Ltd." 1452 "Micro-Air LLC" 1453 "Vital Battery" 1454 "QTIS B.V." 1455 "Eberspächer Climate Control Systems International GmbH" 1456 "Krampe Fahrzeugbau GmbH" 1457 "Albach Maschinenbau AG" 1458 "RideController LLC" 1459 "Advanced Input Systems" 1460 "Tocaro Blue" 1461 "Vanquish Yachts" 1462 "Trackunit ApS" 1463 "STOK Electric" 1464 "Hi-Target Surveying Instrument Co., Ltd." 1465 "Watteco" 1466 "Sveaverken Svea Agri AB" 1467 "S.A.E.T. s.r.l." 1468 "Senquip" 1469 "LS Mtron" 1470 "GemOne NV" 1471 "FT Technologies" 1472 "Acculon Energy" 1473 "Cranesmart Systems, Inc." 1474 "Calex Electronics Limited" 1475 "DSP Solutions, Inc." 1476 "Wilhelm Stoll Maschinenfabrik GmbH" 1477 "TOBROCO-GIANT" 1478 "Alps Alpine Co., Ltd." 1479 "A-Electronix" 1480 "Thermo King" 1481 "E-Force Marine" 1482 "CMC Marine" 1483 "Nanjing Sandemarine Information Technology Co., Ltd." 1484 "AgroOSA" 1485 "Lester Electrical" 1486 "Xpanner" 1487 "Geosoft" 1488 "Boetkin Technology Co., LTD" 1489 "Lite-Check LLC" 1490 "Clean Republic SODO, LLC" 1491 "Power Pollen" 1492 "Softivert" 1493 "Jantop Oy" 1494 "RAPITRONICS" 1495 "FlyAgData" 1496 "AgriRobot" 1497 "ERMO Spa" 1498 "PM Pfanzelt Maschinenbau GmbH" 1499 "Hydrasystem SP. Z O.O." 1500 "Scanstrut Inc." 1501 "Reverso Pumps LLC" 1502 "Barantech" 1503 "Rosemount Specialty Products" 1504 "Nimbus Power Systems, Inc." 1505 "BC Motion" 1506 "Expion360" 1507 "Apex.AI, Inc." 1508 "Xwatch Safety Solutions Ltd. part of Hexagon" 1509 "Bondioli & Pavesi" 1510 "Austin Motor Works" 1511 "APATOR METRA s.r.o." 1512 "Lumitec LLC" 1513 "Sy-Klone International" 1514 "SYMX.ai" 1515 "Ingeniería y Sistemas Cerea" 1516 "THERMIS spol. s r.o." 1517 "Daedong Corporation" 1518 "Nova Kool Manufacturing ULC" 1519 "Volboff Electron Science and Technology Co., Ltd." 1520 "SRT Marine Systems PLC" 1521 "Agricolmeccanica" 1522 "American Thermal Instruments" 1523 "Carlson Software" 1524 "Ocean Infinity Solutions Limited" 1525 "Emsiso-emDrive" 1526 "MITSUBISHI MAHINDRA AGRICULTURAL MACHINERY CO.,LTD." 1527 "Richardt Steuer- und Regelgeraete GmbH" 1528 "Savant Technology" 1529 "Industrie Elektronik Brilon GmbH" 1530 "Roelama B.V." 1531 "Kobelco Construction Machinery Co.,Ltd." 1532 "E-Switch, Inc." 1533 "Rieker Inc." 1534 "BluVein" 1535 "LOX Container Technology AB" 1536 "Tatra Trucks a.s." 1537 "Anyload Weigh & Measure Inc." 1538 "Quick S.p.A." 1539 "Ceday Information Technologies" 1540 "Ideas & Motion" 1541 "Solid State Marine" 1542 "Global Digital Instruments" 1543 "GT Joysticks AG" 1544 "Geophysical Survey Systems, Inc." 1545 "RoadEazy" 1546 "ESMART" 1547 "Weichai Lovol Intelligent Agricultural Technology Co., Ltd." 1549 "AM Co., Ltd." 1550 "Mario Tanzi S.A." 1551 "LMCE Group" 1552 "Antoniosi Tecnologia Agroindustrial Ltda" 1553 "Boughton Engineering LTD" 1554 "Frigus AB" 1555 "Safiery" 1556 "B. Kaufmann AG Landmaschinen" 1557 "Interfacom S.A.U." 1558 "Intangles Lab Private Limited" 1559 "Kar-Tech, Inc." 1560 "MACOME CORPORATION" 1561 "Fox Marine" 1562 "Kingsat Communications Co., Ltd" 1563 "Wabtec Graham White" 1564 "Pro-Guide Batteries" 1565 "Livemac Co., Ltd." 1566 "OUTSET" 1567 "Hagedorn Software Engineering GmbH" 1568 "Aigro" 1569 "621 Technologies Inc." 1570 "Unverferth Manufacturing Company Inc." 1571 "Super B" 1572 "SMARTLINE Co., Ltd." 1573 "R.H. Sheppard" 1574 "SIGMA4 SRL" 1575 "DieselHeat" 1576 "RB International S.r.l." 1577 "Ironstone AG" 1578 "MidNite Solar Inc." 1579 "Hydro Engineering" 1580 "Nabtesco Corporation" 1581 "Metro Marine LLC" 1582 "Samsung Heavy Industries Co., Ltd." 1583 "MULTI-WING GROUP A/S" 1584 "TWK-ELEKTRONIK GmbH" 1585 "Qianxun Spatial Intelligence (Zhejiang) Inc." 1586 "XAG CO., LTD." 1587 "BURGER GROUP" 1588 "MORESIL" 1589 "HÜBNER GmbH & Co. KG" 1590 "Monpaineis" 1591 "WaterWorld Electronics" 1592 "Incomagri Máquinas Agrícolas Ltda" 1593 "Cordon Technologies" 1594 "Elwell Corporation" 1595 "Pruefrex engineering e motion gmbh" 1596 "Neosens" 1597 "S.A.S. Desvoys & Fils" 1598 "Di Goro" 1599 "Kamtec" 1600 "Consolidated Metco, Inc." 1601 "T/CCI Manufacturing, LLC" 1602 "Norcross Marine Products" 1603 "Rockville Audio" 1604 "RoverSense Technologies" 1605 "Blue Wolf" 1606 "SENSAR MARINE INC." 1607 "Micro-Key" 1608 "Quectel" 1609 "NanoNord A/S" 1610 "Simarine d.o.o." 1611 "Ningbo Haibo Group Co., Ltd." 1612 "BLUETTI" 1613 "Whisperpower" 1614 "Risseeuw Techniek" 1615 "J.Assy" 1616 "Satel Oy" 1617 "DRUDLES s.r.o." 1618 "The Carlisle and Finch Co." 1619 "Clemens GmbH & Co. KG" 1620 "BlueNav" 1621 "Mach Inc." 1622 "Brettmeister Elektronik" 1623 "PRO Charging Systems, LLC" 1624 "CrossControl" 1625 "DMX Power LLC" 1626 "SMP STABIL GmbH" 1627 "Roter Italia" 1628 "Vanemar, Inc." 1629 "dSPACE SE & Co. KG" 1630 "Rainer Meyer Landmaschinen GmbH" 1631 "Leidos" 1632 "Zocon" 1633 "Zydro Marine Technologies, Inc." 1634 "IBISUL ELETRÔNICA LTDA" 1635 "Saframax Industrial" 1636 "TBB POWER (XIAMEN) Co., Ltd." 1637 "Scherzinger Pumpen GmbH & Co. KG" 1638 "TEMPA TEKNIK" 1639 "GEA Farm Technologies Canada Inc." 1650 "Shanghai Infipax Technology Co., Ltd." 1653 "Schaffer Farming Technologies" 1850 "Seastar Solutions (formerly Teleflex)" 1851 "RayMarine" 1852 "Navionics" 1853 "Japan Radio Co" 1854 "Northstar Technologies" 1855 "Furuno USA" 1856 "Trimble" 1857 "Simrad" 1858 "Litton" 1859 "Kvasar AB" 1860 "MMP" 1861 "Vector North America (formerly Vector Cantech)" 1862 "Sanshin" 1863 "Thomas G. Faria Co." ;
VAL_ 2566848512 Industry_Code 0 "Global" 1 "Highway" 2 "Agriculture" 3 "Construction" 4 "Marine Industry" 5 "Industrial" ;
VAL_ 2582577152 Manufacturer_Code 0 "For experimental or developmental use only." 1 "Bendix Commercial Vehicle Systems LLC (formerly Allied Signal Inc.)" 2 "Allison Transmission, Inc." 3 "Ametek, US Gauge Division" 4 "Ametek-Dixson" 5 "AMP Inc." 6 "Berifors Electronics AB" 7 "Case Corp." 8 "Caterpillar Inc." 9 "Chrysler Corp." 10 "Cummins Inc (formerly Cummins Engine Co)" 11 "Dearborn Group Inc." 12 "Deere & Company, Precision Farming" 13 "Delco Electronics" 14 "Detroit Diesel Corporation" 15 "DICKEY-john Corporation" 16 "Eaton Corp" 17 "Eaton Corp, Corp Res & Dev" 18 "Eaton Corp, Transmission Div." 19 "Eaton Corp. Trucking Info Services" 20 "Eaton Ltd" 21 "Echlin Inc., Midland Brake Inc." 22 "Ford Motor Co., Electronic Concepts & Systems" 23 "Ford Motor Co., Heavy Truck" 24 "Ford Motor Co., Vehicle Controls" 25 "Daimler Trucks North America LLC (formerly Freightliner LLC)" 26 "General Motors Corp, Service Technology Grp" 27 "GMC" 28 "Grote Ind. Inc." 29 "Hino Motors Ltd." 30 "Isuzu Motors Ltd" 31 "J Pollak Corp" 32 "Jacobs Vehicle Systems" 33 "John Deere" 34 "Kelsey Hayes Co." 35 "Kenworth Truck Co." 36 "Lucas Ind." 37 "Mack Trucks Inc." 38 "Micro Processor Systems Inc." 39 "Microfirm Inc." 40 "Motorola AIEG Inc." 41 "Motorola Inc." 42 "International Truck and Engine Corporation - Engine Electronics (formerly Navistar Intl Trans Co., Engine Electronics)" 43 "International Truck and Engine Corporation - Vehicle Electronics (formerly Navistar Intl Trans Corp.)" 44 "Nippondenso Co. Ltd." 45 "PACCAR" 46 "Noregon Systems, LLC (formerly Noregon Systems, Inc)" 47 "Phillips Semiconductor" 48 "Pollak Alphabet" 49 "RE America Inc." 50 "Robert Bosch Corp" 51 "Robert Bosch GmbH" 52 "Meritor Automotive, Inc. (formerly Rockwell Automotive)" 53 "Continental Automotive Systems US, Inc. (formerly Rockwell Land Transportation)" 54 "Meritor Wabco" 55 "Ryder System Inc." 56 "SAIC" 57 "Danfoss (formerly Sauer Sundstrand Co, then Sauer-Danfoss Co)" 58 "SPX Corporation, OTC Div" 59 "VES Inc." 60 "Volvo Trucks North America Inc." 61 "Volvo Truck Corp." 62 "Wabco" 63 "ZF Industries Inc." 64 "Unused (formerly SpectraPrecision Laserplane, then SpectraPhysics)" 65 "MAN Nutzfahrzeuge AG" 66 "John Deere Construction Equipment Division" 67 "John Deere Coffeyville Works (formerly Funk Manufacturing Company)" 68 "Scania" 69 "Trimble Navigation" 70 "Flex-coil Limited" 71 "Vansco Electronics Ltd." 72 "Sisu Corporation" 73 "LeTourneau, Inc." 74 "Eaton Axle-Brake Division" 75 "Deere & Co, Agricultural Division" 76 "unused (formerly Deere & Co, Construction Division)" 77 "Deere Power Systems Group" 78 "Frank W. Murphy Manufacturing, Inc" 79 "Daimler Benz AG - Engine Division (PBM)" 80 "Twin Disc, Inc." 81 "Fire Research Corp." 82 "Bobcat/Ingersoll-Rand (formerly Melroe/Ingersoll-Rand)" 83 "Bendix VORAD Technologies (formerly Eaton VORAD Technologies)" 84 "New Holland UK Limited" 85 "Kohler Co" 86 "C. E. Niehoff & Company" 87 "J.C. Bamford Excavators Ltd (JCB)" 88 "Hemisphere GPS Inc (formerly Satloc Precision GPS)" 89 "Kverneland Group, Electronics Division" 90 "Knorr-Bremse SfN GmbH" 91 "BSG Bodensee Steuergeraete GmbH" 92 "Ag-Chem Equipment Co., Inc." 93 "Perkins Engines Company Ltd." 94 "CNH Industrial N.V. (formerly CNH Global N.V.)" 95 "Pacific Insight Electronics Corp." 96 "Mech@tronic IT GmbH" 97 "Ag Leader Technology, Inc." 98 "PTx Trimble (formerly Mueller-Elektronik GmbH & Co)" 99 "International Transmissions Ltd (ITL)" 100 "VDO Technik AG" 101 "Sensoria" 102 "AGCO (formerly AGCO GmbH & Co.)" 103 "CLAAS E-Systems GmbH (formerly CLAAS E-Systems KGaA mbH & Co. KG)" 104 "CLAAS KGaA mbH (formerly CLAAS Selbstfahrende Erntemaschinen GmbH)" 105 "Kiepe Elektrik GmbH & Co. KG" 106 "BAE Systems Controls, Inc." 107 "Grimme Landmaschinen GmbH & Co. KG" 108 "PTx Trimble (formerly WTK-Elecktronik GmbH, now a duplicate entry; use MFR ID 98)" 109 "TeeJet Technologies Denmark (formerly LH Technologies ApS)" 110 "EPIQ Sensor-Nite" 111 "Bernard Krone Holding SE & Co. KG (formerly Maschinenfabrik Bernard Krone GmbH)" 112 "MECALAC" 113 "Stress-Tek, Inc." 114 "EControls, Inc." 115 "NACCO Materials Handling Group, Inc." 116 "BEELINE Technologies" 117 "HUSCO International" 118 "Intron GmbH" 119 "IntegriNautics" 120 "RDS Technology Ltd" 121 "HED (Hydro Electronic Devices, Inc.)" 122 "FG Wilson (Engineering) Limited" 123 "Basler Electric" 124 "Hydac Electronic" 125 "Nevada Automotive Test Center" 126 "Driver Tech" 127 "Holland USA" 128 "Gerhard Duecker GmbH & Co. KG" 129 "OMNEX Control Systems Inc." 130 "Nido - Universal Machines B.V." 131 "ITT Industries" 132 "Mulag-Fahrzeugwerk" 133 "Bucher Schoerling GmbH" 134 "Iris Technology Ltd" 135 "Airmar Technology Corporation" 136 "Komatsu Ltd" 137 "Maretron" 138 "Georg Fritzmeier GmbH & Co. KG" 139 "Caterpillar Trimble Control Technologies (CTCT), LLC" 140 "Lowrance Electronics, Inc." 141 "Thales Navigation Ltd." 142 "TRW Automotive (Commercial Steering Systems)" 143 "W. Gmeiner GmbH & Co." 144 "Mercury Marine" 145 "MurCal Controls" 146 "Maxima Technologies" 147 "Nautibus electronic GmbH" 148 "Blue Water Data, Inc." 149 "Holset" 150 "Fleetguard" 151 "Raven Industries, Inc." 152 "elobau GmbH & Co. KG" 153 "Woodward, Industrial Controls Division" 154 "Westerbeke Corporation" 155 "Vetronix Corporation" 156 "ITT Industries - Cannon" 157 "ISSPRO Inc." 158 "Firestone Industrial Products Company" 159 "NTech Industries Inc" 160 "Nido" 161 "Offshore Systems (UK) Ltd" 162 "Axiomatic Technologies" 163 "BRP Inc." 164 "MTU Friedrichshafen GmbH (formerly DaimlerChrysler Off-Highway)" 165 "CPAC Systems AB" 166 "John Deere Electronic Solutions (formerly Phoenix International)" 167 "JLG Industries Inc" 168 "Xantrex" 169 "Marlin Technologies Inc." 170 "Computronics Corporation Ltd." 171 "Topcon Electronics GmbH & Co. KG (formerly Wachendorff Elektronik GmbH & Co. KG)" 172 "Yanmar Co., Ltd. (formerly Yanmar Marine USA)" 173 "Ryeso, Inc." 174 "AB Volvo Penta" 175 "Veris Technologies, Inc." 176 "Moritz Aerospace" 177 "Diagnostic Systems Associates" 178 "Continental Automotive GmbH (formerly Siemens VDO Automotive AG)" 179 "TeeJet Technologies Springfield (formerly Midwest Technologies Illinois, LLC)" 180 "Smart Power Systems" 181 "Coretronics, Inc." 182 "Vehicle Systems Engineering B.V." 183 "KDS Controls, Inc" 184 "EIA Electronics" 185 "Beede Electrical Instrument Company" 186 "Altronic, Inc" 187 "Air-Weigh" 188 "EMP Corp" 189 "QUALCOMM" 190 "Hella KGaA Hueck & Co" 191 "XRS Corporation (formerly XATA Corporation)" 192 "Floscan" 193 "Jeppesen Marine" 194 "TriMark Corporation" 195 "General Engine Products" 196 "LEMKEN GmbH & Co KG" 197 "Mechron Power Systems" 198 "Mystic Valley Communications" 199 "ACTIA Group (formerly Actia Corp)" 200 "MGM Brakes" 201 "Disenos y Tecnologia S.A." 202 "Curtis Instruments, Inc" 203 "MILtronik GmbH" 204 "The Morey Corporation" 205 "SmarTire Systems Inc" 206 "port GmbH" 207 "Otto Engineering" 208 "Drew Technologies, Inc" 209 "Bell Equip. Co. SA (PTY) LTD" 210 "Iteris, Inc." 211 "DNA Group" 212 "Sure Power Industries, Inc" 213 "CNH Belgium N.V." 214 "MC elettronica Srl" 215 "Aetna Engineering/Fireboy-Xintex" 216 "Paneltronics Inc." 217 "RM Michaelides Software & Elektronik GmbH" 218 "Gits Manufacturing Company" 219 "Cat OEM Solutions" 220 "Beede Electrical Instrument Company, Inc" 221 "SiE" 222 "Generac Power Systems, Inc." 223 "Vaueo Retarder Co., Ltd." 224 "EMMI Network, S.L." 225 "SKF" 226 "Monaco Coach Corporation" 227 "Lykketronic A/S" 228 "Unused (formerly ZF Marine Electronics)" 229 "Garmin International Inc." 230 "Saucon Technologies" 231 "Topcon Positioning Systems, Inc." 232 "TSD Integrated Controls" 233 "Yacht Monitoring Solutions Inc." 234 "Mondial electronic GmbH" 235 "SailorMade Marine Telemetry - Tetra Technology Ltd." 236 "NORAC Systems International Inc" 237 "Agtron Enterprises Inc" 238 "ZF Friedrichshafen AG" 239 "May & Scofield Ltd" 240 "Vanair Mfg" 241 "Schneider Automation SAS" 242 "Kokusandenki Co. Ltd" 243 "eRide, Inc." 244 "Techno-Matic" 245 "Capstan Ag Systems, Inc." 246 "Class 1, Inc" 247 "ePULSE" 248 "Cooper Standard Automotive Active Systems Group" 249 "Schaltbau GmbH" 250 "Kuhn Group" 251 "German Agricultural Society, Test Center (DLG)" 252 "Sensor-Technik Wiedemann GmbH" 253 "Mobile Control Systems" 254 "GE Sensing" 255 "MEAS France" 256 "Tyco Electronics AMP" 257 "Honda Motor Co., Ltd" 258 "ARAG" 259 "Bucher Automation AG (formerly Jetter AG)" 260 "Reichhardt GmbH Steuerungstechnik" 261 "Red Dot Corporation" 262 "HydraForce, Inc" 263 "IMMI" 264 "Autolync" 265 "MTS Sensor Technologie GmbH" 266 "International Thermal Research Ltd" 267 "Red Lion Controls, Inc" 268 "Accurate Technologies" 269 "Saft America Inc., Space & Defense Division" 270 "Tennant" 271 "Cole Hersee" 272 "Gross Mechanical Laboratories, Inc" 273 "Active Research Limited" 274 "LTW Technology Co., LTD" 275 "Navico Egersund AS" 276 "Aqua-Hot Heating Systems" 277 "LHP Telematics" 278 "Takata Electronics" 279 "Geometris LP" 280 "Leica Geosystems Pty Ltd" 281 "Precision Governors LLC" 282 "Medallion Instrumentation Systems" 283 "CWF Hamilton & Co Ltd" 284 "Mobile Tech Chile" 285 "Sea Recovery Corp" 286 "Coelmo srl" 287 "NTech Industries, Inc" 288 "Mitsubishi FUSO Truck & Bus Corp." 289 "Watlow" 290 "Kuebler GmbH" 291 "Groeneveld Transport Efficiency BV" 292 "IKUSI - Angel Iglesias S.A." 293 "Spyder Controls Corp." 294 "Grayhill Inc." 295 "BEP Marine" 296 "micro dynamics GmbH" 297 "Zonar Systems Inc" 298 "Holley Performance" 299 "Rauch" 300 "Systron Donner Automotive" 301 "Parker Hannifin (UK) Ltd FDE group" 302 "Nissin Kogyo Co., LTD" 303 "CTS Corporation" 304 "EmpirBus AB" 305 "NovAtel Inc" 306 "Sleipner Motor AB" 307 "MAS Technologies" 308 "Cyntrx" 309 "Krauss-Maffei Wegmann GmbH & Co. KG" 310 "TECNORD srl" 311 "Patrick Power Products" 312 "Lectronix, Inc." 313 "Ilmor Engineering, Inc." 314 "CSM GmbH" 315 "Icom Incorporated" 316 "ITT Flow Control" 317 "Navtronics Bvba" 318 "SAT Plan" 319 "Cadec Global" 320 "Miedema Landbouwwerktuigenfabriek B.V." 321 "Ultra Electronics, Electrics" 322 "MICHENKA s.r.o." 323 "Mobileye Vision Technologies Ltd." 324 "Snap-on Diagnostics" 325 "ASM Automation Sensorik Messtechnik GmbH" 326 "Akron Brass Company" 327 "Sonceboz SA" 328 "Qwerty Electronik AB" 329 "Deif A/S" 330 "Kidde Aerospace and Defense" 331 "Horton, Inc." 332 "HWH Corporation" 333 "Link Manufacturing, Ltd. (formerly Hadley Products Corporation)" 334 "Takata-Petri AG" 335 "Evo Electric Ltd" 336 "APE s.r.o." 337 "Carraro S.p.A." 338 "GRAF-SYTECO" 339 "Competence Center ISOBUS e.V." 340 "Continental AG" 341 "Boning GmbH & Co" 342 "THOMAS MAGNETE GmbH" 343 "Baumer Group" 344 "Parvus Corporation" 345 "Korean Maritime University" 346 "Control Solutions" 347 "Honeywell" 348 "Amazonen Werke H. Dreyer" 349 "Suonentieto" 350 "Noris Marine Systems GmbH & Co KG" 351 "Thrane & Thrane" 352 "SAME DEUTZ-FAHR GROUP S.p.A." 353 "Hegemon Electronics, Inc." 354 "Junkkari OY" 355 "Mastervolt International B.V." 356 "Fischer Panda Generators, Inc" 357 "Hardi International A/S" 358 "Victron Energy B.V." 359 "Ludwig Bergmann GmbH" 360 "HJS Emission Technology GmbH & Co KG (formerly HJS Fahrzeugtechnik GmbH & Co KG)" 361 "InMach" 362 "Poettinger Landtechnik GmbH (formerly Alois Poettinger Maschinenfabrik GmbH)" 363 "BEI Duncan" 364 "OEM Controls Inc." 365 "Digi-Star, LLC" 366 "Viewnyx Corp." 367 "Fliegl Agrartechnik" 368 "HANSENHOF_electronic" 369 "Power Torque Engineering Ltd" 370 "Rolls-Royce Marine AS" 371 "Heinzmann GmbH & Co. KG" 372 "Delphi" 373 "Electronic Design Inc." 374 "Northern Lights, Inc." 375 "Williams Controls Inc." 376 "Quake Global" 377 "ifm electronic gmbh" 378 "Glendinning Marine Products" 379 "Yamabiko Corporation" 380 "Suntech International Ltd." 381 "B & G" 382 "National Agriculture and Food Research Organization" 383 "MCL Industries" 384 "Camano Light" 385 "Johnson Outdoor Marine Electronics" 386 "JLG Automation BVBA" 387 "Orscheln Products, LLC" 388 "Innomatix, LLC" 389 "Benchmark Electronics, Minnesota Division" 390 "Partech Inc." 391 "Electronic Design for Industry, Inc" 392 "Tianyuan Technology Co Ltd." 393 "Harvest Tec, Inc" 394 "Capi 2 Nederland B.V." 395 "GENTEC S.R.L." 396 "Beyond Measure" 397 "Sanyo-kiki Co Ltd." 398 "Hilite International" 399 "ISEKI & Co., Ltd." 400 "Livorsi Marine" 401 "Torqeedo GmbH" 402 "Simma Software, Inc." 403 "Trackwell ADS, Inc." 404 "Com Nav Marine Ltd" 405 "Wema System AS" 406 "Vecima Networks Inc." 407 "Comtech Mobile Datacom" 408 "Corvus Energy Ltd." 409 "Transfluid S.r.L." 410 "COBO S.p.A. Divisione 3B6" 411 "Hy-Drive Technologies Ltd." 412 "WebTech Wireless Inc." 413 "Datapross Nijbroek bv" 414 "Cattron Group International" 415 "Valid Manufacturing Ltd." 416 "Kubota Corporation" 417 "KZValve" 418 "Intellistick Inc" 419 "Fusion Electronics Ltd" 420 "Vermeer Corporation, ACS Group" 421 "Vertex Standard Co, Ltd" 422 "True Heading AB" 423 "BSM Wireless, Inc." 424 "Odyne LLC" 425 "Methode Electronics Inc, MDI" 429 "Rota Engineering Ltd." 430 "Auteq Telematica S.A." 431 "Tohatsu Corporation" 432 "S&A Systems, Inc." 433 "Rowe Electronics" 434 "Stored Energy Systems" 435 "Zunhammer GmbH" 436 "Kinze Manufacturing" 437 "Digital Yacht Limited" 438 "Comar Systems Ltd" 439 "HD Hyundai (formerly Hyundai Heavy Industries)" 440 "Cummins Power Generation" 441 "PTG Reifendruckregelsysteme GmbH" 442 "HORSCH Maschinen SE & Co. KG (formerly HORSCH Maschinen GmbH)" 443 "SignalQuest, Inc." 444 "ITT Power Solutions" 445 "KAT MECHATRONIC, Electronic Product Division" 446 "CertTech, L.L.C." 447 "Great Plains Mfg." 448 "Stanadyne Corporation, Electronics Systems" 449 "Polaris Industries Inc" 450 "Dycor Technologies Ltd." 451 "Parker Hannifin Corp" 452 "WIKA Alexander Wiegand SE & Co. KG" 453 "Cooper Bussmann" 454 "NGK Spark Plug Co. Ltd" 455 "ADZ NAGANO GmbH" 456 "General Kinetics" 457 "RUSELPROM-ElectricDrive Ltd" 458 "Control Solutions, Inc." 459 "Alltek Marine Electronics Corp" 460 "San Giorgio S.E.I.N." 461 "HAWE Hydraulik SE" 462 "IHI Shibaura Machinery Corporation" 463 "PROBOTIQ" 464 "Leach International Corporation" 465 "Ashcroft Inc" 466 "Veethree Electronics and Marine LLC" 467 "Lely Industries N.V." 468 "Tyco Fire Protection Products" 469 "RA Consulting GmbH" 470 "SI-TEX Marine Electronics" 471 "Sea Cross Marine AB" 472 "Tenneco Inc." 473 "Boss Industries, Inc." 474 "Persen Technologies Inc." 475 "GME" 476 "Hummingbird Marine Electronics" 477 "OilQuick AB" 478 "OceanSat B.V." 479 "Vapor Bus International" 480 "EnerDel, Inc." 481 "Chetco Digital Instruments" 482 "Tricon Electronics" 483 "Valeo" 484 "Headsight Inc." 485 "MATT automotive" 486 "Westport Innovations Inc." 487 "DSE Test Solutions A/S" 488 "The Charles Machine Works, Inc." 489 "Appareo Systems, LLC" 490 "QuikQ" 491 "Penny and Giles Ltd" 492 "Inergy Automotive Systems" 493 "Watcheye" 494 "Synerject" 495 "HOLMER Maschinenbau GmbH" 496 "W. Gessmann GmbH" 497 "SENTRON Sistemas Embarcados" 498 "Innovative Design Solutions, Inc." 499 "LCJ Capteurs" 500 "Oxbo International Corporation" 501 "Agrotronix S.A." 502 "Attwood Corporation" 503 "Naviop S.R.L." 504 "Vesper Marine" 505 "Yetter Farm Equipment" 506 "IHI STAR Machinery Corporation" 507 "ISOBUS Test Center" 508 "Transtech Innovations" 509 "MOTORTECH GmbH" 510 "Marinesoft Co. Ltd" 511 "Sulky" 512 "Inpower LLC" 513 "Precision Technology" 514 "DISTek Integration, Inc." 515 "GINAF Trucks Nederland B.V." 516 "AVAT Automation GmbH" 517 "Noland Engineering" 518 "Transas USA Inc." 519 "Peeters Landbouwmachines b.v." 520 "Trapeze" 521 "Clever Devices Ltd." 522 "Nebraska Tractor Test Laboratory" 523 "Reggio Emilia Innovazione" 524 "Vomax Instrumentation Pty. Ltd." 525 "Rust Sales INC" 526 "LOFA Industries, Inc" 527 "GKN Walterscheid GmbH" 528 "Hoganas AB, Electric Drive Systems" 529 "National Instruments Korea" 530 "NMEA" 531 "Genge & Thoma AG" 532 "Onwa Marine Electronics Co Ltd." 533 "Doran Manufacturing, LLC" 534 "Webasto Thermo & Comfort SE" 535 "MOTORPAL, a.s." 536 "SSI Technologies" 537 "Schrader Electronics Ltd." 538 "Crop Ventures, Inc." 539 "Mobileview" 540 "Dinex A/S" 541 "Total Fire Systems, Inc." 542 "Dinamica Generale s.p.a." 543 "BAUER Maschinen GmbH" 544 "Au Group Electronics" 545 "GS Global Resources (formerly GS Hydraulics)" 546 "Maruyama Mfg Co, Inc." 547 "Thomson Linear LLC" 548 "TM4 Inc." 549 "ROAD Deutschland GmbH" 550 "SUN-A Corporation" 551 "Wexler CSD Ltd." 552 "Matsuyama Plow Mfg Co, Ltd" 553 "KIB Electronics" 554 "iris-GmbH infrared & intelligent sensors" 555 "Sasaki Corporation" 556 "HD Hyundai Infracore Norway (formerly Doosan Infracore Norway)" 557 "Rockson Automation GmbH" 558 "Davis Instruments Corp." 559 "Four Peaks Navigation" 560 "Iowa State University, Agricultural and Biosystems Engineering" 561 "b-plus GmbH" 562 "Bombardier Transportation GmbH" 563 "LOHR Sistemas Eletronicos LTDA" 564 "Auto Power Electronic" 565 "Micro-Trak Systems, Inc." 566 "Geode Technology, Inc." 567 "Lithiumstart LLC" 568 "Makersan Ltd. Co." 569 "LORD MicroStrain Sensing Systems" 570 "frenzel + berg electronic GmbH & Co. KG" 571 "Marinecraft Co., Ltd." 572 "Fasse Valves" 573 "Orolia Ltd" 574 "Vishay Precision Group" 575 "Lytx" 576 "Vectia" 577 "Denchi Power Ltd (formerly ABSL Power Solutions Limited)" 578 "advanSea" 579 "KVH Industries, Inc." 580 "San Jose Technology, Inc." 581 "Väderstad AB" 582 "Innovative Software Engineering" 583 "Yachtcontrol" 584 "CarMedialab GmbH" 585 "Industrial Electronic Controls" 586 "Suzuki Motor Corp" 587 "JCA Electronics" 588 "Vignal Systems" 589 "MICO, Inc." 590 "ARGO-HYTOS GMBH" 591 "United States Coast Guard" 592 "tecsis GmbH" 593 "Sensata Technologies" 594 "Kongsberg Automotive" 595 "CustomWare" 596 "Brunelco Electronic Innovators B.V." 597 "Hydac Filter Systems GmbH" 598 "ABB Turbo Systems Ltd" 599 "Spudnik Equipment Co, LLC" 600 "Aquatic AV" 601 "Navitas Systems" 602 "Nomad Digital Ltd." 603 "Kereval" 604 "Rototilt Group AB (formerly Indexator Rototilt Systems AB)" 605 "Aventics GmbH" 606 "Intellian Technologies" 607 "Knappco/Civacon" 608 "Gale Banks Engineering" 609 "Walvoil S.p.A." 610 "Trail Tech" 611 "Esterline" 612 "Samwon IT" 613 "HKS Co., Ltd." 614 "ARLT Technologies GmbH" 615 "Networkfleet, Verizon Telematics" 616 "SMART-TEC s.r.o." 617 "Zero Emission Vehicles" 618 "Evrard SA" 619 "Right Weigh Load Scales" 620 "BorgWarner Inc. (formerly Sevcon Ltd.)" 621 "Hagie Manufacturing Company" 622 "Floyd Bell Inc" 623 "Xirgo Technologies" 624 "Blackbox Machine Control Pty Ltd" 625 "Global MRV Inc." 626 "AVL DiTEST GmbH" 627 "Radio Ocean" 628 "Falck Schmidt Defence Systems" 629 "Agri Info Design, Ltd." 630 "SmartDrive Systems Inc." 631 "Reltima" 632 "Pepperl+Fuchs GmbH" 633 "TORC Robotics" 634 "Rocky Research" 635 "Argo Tractors S.p.A." 636 "Divelbiss Corporation" 637 "Bavaria Yachtbau GmbH" 638 "KVH Industries, Inc." 639 "Startec s.r.l." 640 "Power Solutions International" 641 "Diverse Yacht Services" 642 "Moog / Aspen Motion Technologies" 643 "Bogballe A/S" 644 "KUS USA" 645 "esd electronic system design gmbh" 646 "Veenhuis Machines B.V." 647 "Siloking" 648 "OJSC Ekran" 649 "Control-Q B.V." 650 "Seiko Epson Corp." 651 "Takakita Co, Ltd." 652 "MicroControl GmbH & Co. KG" 653 "AEV, spol. s r. o." 654 "Kohler Power Systems, Detroit Engine Development Center (DEDC)" 655 "Genge & Thoma AG" 656 "PRO SOLUS do Brasil" 657 "Terzo Power Systems" 658 "Shenzhen Jiuzhou Himunication Technology Co., Ltd" 659 "Data Panel Corp." 660 "Auto-Gaz Centrum" 661 "SPAL Automotive S.r.l." 662 "Kissling Elektrotechnik GmbH" 663 "Delta Systems, Inc" 664 "Level Developments Ltd" 665 "Gebr. Bode GmbH & Co. KG" 666 "Schaeffler Technologies AG & Co., KG" 667 "Bartec" 668 "MacDon Industries Ltd." 669 "Quantum Fuel Systems Technologies Worldwide, Inc" 670 "STEMCO LP" 671 "Innovative Controls Inc." 672 "OPTIMA Concept" 673 "Caruelle Nicolas" 674 "Yara International ASA" 675 "Kawasaki Motors, Ltd. (formerly Kawasaki Motors Corp., USA)" 676 "Danfoss IXA A/S" 677 "DSA Daten- und Systemtechnik GmbH" 678 "KeepTruckin, Inc." 679 "OXE Marine AB (formerly Cimco Marine AB)" 680 "AMVAC Chemical Corporation" 681 "BEDIA Motorentechnik GmbH & Co. KG" 682 "Eckelmann AG" 683 "Fosen Elektro" 684 "KEB" 685 "ANEDO (formerly ANEDO Ltd.)" 686 "Taigene Electric Machinery Corp." 687 "Flight Systems, Inc." 688 "Rockford Corp" 689 "Aarcomm Systems Inc" 690 "LINAK A/S" 691 "Digitroll Agricultural Electronics" 692 "Tanhay Corporation" 693 "Agility Fuel Solutions (formerly Agility Fuel Systems)" 694 "GasTOPS Ltd." 695 "Weldon Technologies" 696 "DRS Network & Imaging Systems, LLC (DRS Technologies)" 697 "JOST Umeå AB (formerly Ålö AB)" 698 "Scorpion Technologies Ltd." 699 "Harman International (formerly Harman International Industries)" 700 "K-Tec Earthmovers Inc." 701 "BigRoad Inc." 702 "Weichai Power Co., Ltd." 703 "Hydro Tab Marine Engineering" 704 "JL Audio, Inc." 705 "SVAB Hydraulik AB" 706 "Shanghai Diesel Engine Corporation Limited" 707 "Rochester Gauges Inc" 708 "Lars Thrane A/S" 709 "Marquardt GmbH" 710 "Greentronics Ltd." 711 "DAS Co., LTD" 712 "LOR Manufacturing Company Inc." 713 "US Hybrid Corporation" 714 "Kobashi Kogyo Co., Ltd." 715 "Autonnic Research Ltd" 716 "Eaton Control & Power Conversion Division (CPCD)" 717 "Yacht Devices Ltd" 718 "Micronet Inc" 719 "Cojali S. L." 720 "WITZ Corporation" 721 "Hypro" 722 "Contelec AG" 723 "Jabil Inc." 724 "Electronic Applications, Inc." 725 "Hitachi Construction Machinery Co., Ltd." 726 "MIDORI PRECISIONS" 727 "Dhoot Transmission Pvt Ltd." 728 "Streumaster (formerly Streumaster / Panien)" 729 "Liebherr" 730 "BERTHOUD AGRICOLE" 731 "Modine Manufacturing Company" 732 "Gefran S.p.A." 733 "Intendia S.L." 734 "REAPsystems" 735 "AEM Performance Electronics" 736 "Terex Aerial Work Platforms - Genie" 737 "Balluff GmbH" 738 "Blue Ink Technologies" 739 "LXNAV d.o.o." 740 "e-Traction" 741 "Carling Technologies" 742 "EROAD" 743 "Daemyung Elevator Co., Ltd." 744 "Woosung Engineering Co., Ltd." 745 "Cidra Corporate Services Inc." 746 "SurePoint Ag Systems (formerly SureFire Ag Systems, Inc.)" 747 "Agratronix" 748 "ISOTTA" 749 "Chart Inc." 750 "Joskin SA" 751 "Pacific Track" 752 "Deep Sea Electronics Plc" 753 "AIROD Technologies" 754 "Parker Hannifin Corp., Automation Group" 755 "Firefly Integrations" 756 "Maschio Gaspardo S.P.A." 757 "IMPCO Technologies" 758 "Banner Engineering Corp." 759 "Hydro-Gear" 760 "Bernecker + Rainer Industrie Elektronik GmbH" 761 "MITA OLEODINAMICA S.p.A." 762 "ROJ s.r.l." 763 "AT-Systems BVBA" 764 "Bednar FMT s.r.o." 765 "GIGAVAC" 766 "Epec Oy" 767 "Alliance Wireless Technologies Inc." 768 "Flores Automation, LLC" 769 "Trombetta" 770 "MONOSEM" 771 "Shaw Development, LLC" 772 "Blink Marine" 773 "Clarion Corporation of America" 774 "Taisho Corporation" 775 "ZIEHL-ABEGG Automotive GmbH" 776 "HMI Systems LLC" 777 "Ocean Signal Ltd" 778 "Seakeeper Inc." 779 "RLC Electronic Systems" 780 "Turntide Transport Limited (formerly AVID Technology Ltd)" 781 "Poly-Planar LLC" 782 "AVR nv" 783 "Loup Electronics Inc." 784 "CM Automotive Systems, Inc." 785 "Fischer Panda GmbH" 786 "Johnson Matthey Battery Systems" 787 "Abertax Technologies Limited" 788 "MoTeC Pty Ltd" 789 "GRADALL" 790 "VACALL" 791 "AUTEC" 792 "Kostal Mexicana" 793 "James Fisher Prolec" 794 "Shihlin Electric & Engineering Corporation" 795 "Broyda Enterprises Pty Ltd" 796 "Canadian Automotive Industries Ltd" 797 "Tides Marine" 798 "Lumishore Ltd" 799 "Stillwater Designs and Audio, Inc. - KICKER" 800 "Delta-Q Technologies" 801 "LOR Manufacturing Company Inc." 802 "SPBI (Bj Technologie)" 803 "Gill Sensors & Controls Limited" 804 "ASA Electronics" 805 "Gundersen & Løken AS" 806 "Charge Automotive Ltd" 807 "Schneider-Electric" 808 "RIMEX Supply Ltd." 809 "HMS Industrial Networks AB" 810 "Dutch Power Company" 811 "Blue Water Desalination" 812 "Torch Technologies" 813 "Thales Suisse SA" 814 "Kronotech Srl (formerly Soltec Soluzioni Tecnologiche Srl)" 815 "FLIR Systems, Inc." 816 "UniStrong" 817 "TE Connectivity Sensor Solutions" 818 "HGNSS" 819 "Preco Electronics" 820 "DIaLOGIKa Gesellschaft fuer angewandte Informatik mbH" 821 "Thorsen Teknik A/S" 822 "Bren-Tronics, Inc." 823 "ACEINNA, Inc (formerly MEMSIC, Inc)" 824 "Undheim Systems AS" 825 "BPW Hungária" 826 "Lewmar Marine Inc" 827 "INmatix Technology Group Ltd" 828 "AgriBrink Inc." 829 "Drov Technologies, Inc." 830 "Ultra Motion LLC" 831 "DOK-ING Ltd." 832 "Heizomat Gerätebau-Energiesysteme GmbH" 833 "Electrum Automation AB" 834 "Pioneer Microsystems, Inc." 835 "PetTrack Ltd." 836 "Signature4" 837 "Famic Technologies Inc." 838 "Teamsurv Ltd" 839 "Indexator Rotator Systems AB" 840 "E.S.T.E. srl" 841 "Agra-GPS" 842 "DigiDevice Srl" 843 "Hendrickson Truck Commercial Vehicle Systems" 844 "FELL AS" 845 "GMB Güstrower Maschinenbau GmbH" 846 "L3 Magnet-Motor" 847 "Oceanvolt" 848 "ningupex" 849 "MTS Maschinentechnik Schrode AG" 850 "Geoprospectors GmbH" 851 "Novotechnik Messwertaufnehmer OHG" 852 "Velvac Inc" 853 "Teledyne RESON B.V." 854 "GEMAC Chemnitz GmbH" 855 "Toshiba Infrastructure Systems & Solutions Corporation" 856 "FarmFacts GmbH" 857 "Zoomlion Heavy Industry NA, Inc" 858 "Littelfuse" 859 "Valor" 860 "Michelin" 861 "Adel System S.r.l." 862 "Prospec Electronics" 863 "SMAG" 864 "Streamline Transportation Technologies Inc." 865 "MyEasyFarm" 866 "Netradyne, Inc." 867 "Skeleton Technologies" 868 "Data Panel Corp" 869 "Intercomp" 870 "Textron Fleet Management" 871 "Agri-Fab (formerly Superior Tech Inc)" 872 "Kählig Antriebstechnik GmbH" 873 "Garnet Instruments Ltd." 874 "MTA S.p.A." 875 "Salvarani S.r.l." 876 "SUCO Robert Scheuffele GmbH & Co. KG" 877 "SICK ATech GmbH" 878 "FOTON" 879 "PG Trionic, Inc." 880 "Revision Military" 881 "Sovema" 882 "BHTronik GmbH & Co. KG" 883 "Swift Navigation, Inc." 884 "Sure Grip Controls Inc." 885 "SICK AG (formerly SICK Stegmann GmbH)" 886 "Hitachi Zosen Corporation" 887 "Turntide Transport Limited (formerly Hyperdrive Innovation Limited)" 888 "Carma Systems Inc" 889 "SANY America Inc" 890 "L3 Technologies, Inc." 891 "CarrierWeb" 892 "Mectronx Corp" 893 "KlinkTechnics Ltd." 894 "Rhodan Marine Systems of Florida LLC (Duplicate entry; use MFR ID 1012)" 895 "Peloton Technology" 896 "NextFour Solutions Ltd" 897 "Dot Technology Corp." 898 "Josef Kotte Landtechnik GmbH & Co. KG" 899 "Lippert Components, Inc" 900 "OSB connagtive GmbH (formerly OSB AG)" 901 "Zivan Srl" 902 "Bucher Hydraulics" 903 "InMotion" 904 "Equipment Safety Systems Pty. Ltd. (EQSS)" 905 "ASA Electronics" 906 "MOBA AG" 907 "strautmann" 908 "Chonbuk National University Department of Electronics" 909 "Marines Co., Ltd." 910 "Hermann Paus Maschinenfabrik GmbH" 911 "Nautic-On" 912 "Steyr Motors GmbH" 913 "Toyota Motor Corporation" 914 "ZETOR TRACTORS a.s." 915 "Dosificacion y sistemas electronicos S.L. (DSE)" 916 "Hans Turck GmbH & Co. KG (formerly Turck Inc.)" 917 "Sentinel d.o.o." 918 "AMW Machine Control, Inc" 919 "Furrion LLC" 920 "MTD Consumer Group Inc." 921 "ROPA Fahrzeug- und Maschinenbau GmbH" 922 "Terberg Benschop B.V." 923 "ELTEK S.p.A." 924 "PAS Peschak Autonome Systeme GmbH" 925 "GW Lisk Company" 926 "Buhler Industries Inc." 927 "Saicon" 928 "EAO Automotive GmbH & Co. KG" 929 "Jl Marine Systems, Inc." 930 "Ecotronix Corp." 931 "Enertec Marine Ltd" 932 "Discover Battery" 933 "Delta Mobile Systems, Inc." 934 "Farmobile, Inc." 935 "Meels GmbH & Co. KG" 936 "Hi-tech Millennium" 937 "Precision Circuits Inc" 938 "LEVEL Systems" 939 "Warn Industries, Inc." 940 "Dometal Oy" 941 "Navya" 942 "Vogelsang GmbH & Co. KG" 943 "FISCHER AG Präzisionspindeln" 944 "ZONTISA Marine SL" 945 "Equalizer AG" 946 "Hydac Tecnologia Ltda" 947 "Gerd Bär GmbH" 948 "Donix" 949 "Škoda Electric a.s." 950 "RE:Lab s.r.l." 951 "Exor International S.p.A." 952 "Tan Delta Systems Ltd" 953 "Curtiss-Wright" 954 "Setec Pty Ltd" 955 "Hottinger Baldwin (Suzhou) Electronic Measurement Technology Co., Ltd." 956 "Piher Sensors & Controls S.A." 957 "Sierra Wireless Inc" 958 "NHK MEC Corporation" 959 "Cascade Corporation" 960 "Vemcon GmbH" 961 "POK SAS" 962 "Timbolier Industries, Inc." 963 "Thomason Jones Company, LLC" 964 "AgroVIR Kft" 965 "Ro-Sys Software" 966 "VisibleFarm" 967 "Moteck Electric Corp." 968 "Cox Powertrain Limited" 969 "Blue Sea Systems" 970 "Jaboni Power Products, LLC" 971 "B+B Smartworx" 972 "Axion AG" 973 "Zasso GmbH" 974 "Pico Technology Limited" 975 "Siemens AG" 976 "Derive Systems, Inc." 977 "Copeland LP (formerly Emerson Electric Co.)" 978 "Canfield Connector" 979 "McHale" 980 "Gussi Italia S.R.L." 981 "Kobelt Manufacturing Co. Ltd" 982 "Briggs & Stratton Corporation" 983 "Dezwaef NV" 984 "E-T-A Elektrotechnische Apparate GmbH" 985 "NLR, LLC" 986 "AAMP Global" 987 "Baltic Car Equipment" 988 "Voith Turbo" 989 "Flux-Geräte GmbH" 990 "SAMSUNG SDI Co., Ltd." 991 "Deutronic Elektronik GmbH" 992 "MarineIOT LLC" 993 "Alelion Energy Systems AB" 994 "Morris Industries Ltd." 995 "Circuitlink Pty Ltd." 996 "Eniquest Pty Ltd" 997 "Xenta Systems Srl" 998 "Transcell Technology Inc" 999 "TerraTroniq B.V." 1000 "Landmaschinen Wienhoff GmbH" 1001 "Cleral Inc." 1002 "Kussmaul Electronics Co." 1003 "technotrans SE" 1004 "Ultraflex SpA" 1005 "TSE Brakes, Inc." 1006 "Proterra" 1007 "Maschinenfabrik Meyer-Lohne GmbH" 1008 "Lintest Systems LLC" 1009 "TouchTronics, Inc." 1010 "Agricultural Industry Electronics Foundation e.V." 1011 "Soundmax Electronics Ltd" 1012 "Rhodan Marine Systems of Florida LLC" 1013 "Allochis E-Tec" 1014 "Briri Maschinenbau GmbH" 1015 "SECURITAG SAS" 1016 "Röhren- und Pumpenwerk BAUER GmbH" 1017 "Caldaro AB" 1018 "Flex TTS" 1019 "Codek Foundries" 1020 "Onyx Marine Automation s.r.l." 1021 "Entratech Systems LLC" 1022 "ITC Inc" 1023 "PEAK-System Technik GmbH" 1024 "Inventus Power" 1025 "eze System, Inc." 1026 "ZTR Control Systems, LLC" 1027 "Goldacres PTY LTD" 1028 "Autel Intelligent Technology Corp., Ltd" 1029 "The Marine Guardian LLC" 1030 "Tume-Agri Oy" 1031 "Flintec UK Ltd." 1032 "SIMOL S.p.A." 1033 "ECCO Safety Group" 1034 "Siren Marine" 1035 "Agres" 1036 "Bender GmbH & Co. KG" 1037 "Dragonfly Energy Corp." 1038 "EMIT Technologies, Inc." 1039 "Liugong Dressta Machinery" 1040 "BPE Electronics Srl" 1041 "EZ Lynk" 1042 "engcon group" 1043 "Hyva" 1044 "Xee" 1045 "CMR Group" 1046 "Praxidyn" 1047 "Sonic Corporation" 1048 "Agrivation UG" 1049 "S&S Cycle" 1050 "Spacenus GmbH" 1051 "ProNav AS" 1052 "Pfreundt" 1053 "Vetus Maxwell, Inc." 1054 "Schmotzer Hacktechnik GmbH & Co. KG" 1055 "EXA Computing GmbH" 1056 "Lithium Pros" 1057 "EquipmentShare" 1058 "Bondioli & Pavesi SpA" 1059 "Boatrax" 1060 "Scale-Tec" 1061 "Volvo Construction Equipment" 1062 "Marol Co Ltd" 1063 "SolSteer" 1064 "Omnitech Robotics Inc." 1065 "CALYPSO Instruments" 1066 "Spot Zero Water" 1067 "Tecomec S.r.l." 1068 "Zapi S.p.A." 1069 "Lithionics Battery LLC" 1070 "Quick-teck Electronics Ltd" 1071 "MACH SYSTEMS s.r.o." 1072 "La Marche Manufacturing Company" 1073 "Manitou Equipment America LLC" 1074 "Kindhelm / Navigs Oy" 1075 "Uniden America Corporation" 1076 "DOGA S.A." 1077 "Ymer Technology" 1078 "GE Appliances" 1079 "Carl Zeiss Spectroscopy GmbH" 1080 "Epsilor-Electric Fuel Ltd." 1081 "Imcon Electronics, s.r.o." 1082 "TÜMOSAN Engine and Tractor Co." 1083 "Nauticoncept" 1084 "Shadow-Caster LED lighting LLC" 1085 "Wet Sounds, LLC" 1086 "Life Racing Ltd" 1087 "ITPhotonics S.r.l." 1088 "E-T-A Circuit Breakers" 1089 "Carrosserie HESS AG" 1090 "E-T-A Circuit Breakers Ltd" 1091 "Wheel Monitor Inc." 1092 "Scheiber" 1093 "innolectric" 1094 "Tokushu Denki" 1095 "WEG Drives and Controls - Automação Ltda" 1096 "Texense Sensors" 1097 "M2M Craft Co., Ltd" 1098 "Preh GmbH" 1099 "MadgeTech, Inc" 1100 "LINK Marine Technologies (formerly Smart Yachts International Limited)" 1101 "DIS Sensors B.V." 1102 "Carl Geringhoff GmbH & Co. KG" 1103 "Diesel Laptops" 1104 "The Toro Company" 1105 "Redekop Manufacturing" 1106 "Great Dane LLC" 1107 "Dräger Safety" 1108 "ORBCOMM" 1109 "Dockmate" 1110 "Analytic Systems Ware (1993) Ltd." 1111 "SEPPI M." 1112 "Bollinger Motors" 1113 "iVolve Pty Ltd" 1114 "Bob's Machine" 1115 "Gems Sensors & Controls" 1116 "HR Agrartechnik GmbH" 1117 "LG Chem, Ltd" 1118 "L3Harris ASV" 1119 "Balmar LLC" 1120 "Elettromedia s.r.l." 1121 "Platform Science" 1122 "GT Inc." 1123 "QP Hydraulics" 1124 "Fortron Agriculture" 1125 "Griffith-Elder & Co. Ltd." 1126 "Auralix" 1127 "ElectroMaax" 1128 "Citoon Electronic Technology (Tianjin) Co., Ltd." 1129 "Spectrolytic GmbH" 1130 "Vitesco Technologies" 1131 "Guliwer electronics s.r.o." 1132 "Tokachi Zaidan" 1133 "MEGATRON Elektronik GmbH & Co. KG" 1134 "Master Schools at Ostbahnhof" 1135 "Japan Aviation Electronics Industry, Limited" 1136 "Primosensor GmbH" 1137 "SIKO GmbH" 1138 "Micro-Sensor GmbH" 1139 "ASP Technology" 1140 "Across Oceans Systems Ltd." 1141 "MRS Electronic GmbH & Co. KG" 1142 "Truma" 1143 "Elektro-Szoft 2000" 1144 "Troo Corporation" 1145 "Kiwi Yachting" 1146 "Rometron" 1147 "Dana Inc." 1148 "Stercom Power Solutions GmbH" 1149 "Wuxi Shengbang Electronics Co., Ltd" 1150 "BSB Artificial Intelligence GmbH" 1151 "Orca Technologies AS" 1152 "Vredo Dodewaard B.V." 1153 "Kawasaki Heavy Industries, Ltd." 1154 "TBS Electronics BV" 1155 "LACOS GmbH (formerly LACOS Computerservice GmbH)" 1156 "Nokian Tyres" 1157 "Carriergistics" 1158 "Technoton Electronics" 1159 "Bel Power Solutions" 1160 "MG Energy Systems B.V." 1161 "Griessbach GmbH" 1162 "PEL-tuote Oy" 1163 "DFX Technologies LLC" 1164 "SEG Automotive" 1165 "InnoTotal AB" 1166 "Wachendorff Automation GmbH & Co. KG" 1167 "Tevva Motors" 1168 "Masats S.A." 1169 "Sea Machine Robotics Inc." 1170 "Poseidon Ocean Systems Ltd." 1171 "Vista Manufacturing" 1172 "Hyzon Motors" 1173 "philippi elektrische systeme gmbh" 1174 "Agricon GmbH" 1175 "MAGTEC Products, Inc." 1176 "Asuns Corp." 1177 "RNG International Inc." 1178 "ERO GmbH" 1179 "QS Control srl" 1180 "Murata Power Solutions Inc." 1181 "Banjo Corporation" 1182 "Rottmann Automation" 1183 "Zipwake AB" 1184 "AMA S.p.A." 1185 "WFCO Electronics" 1186 "Sailmon BV" 1187 "TiTAN-Project LLC" 1188 "G-SNS" 1189 "Autotrasporti Cavallo G&V" 1190 "Sirros IoT" 1191 "Pacoma USA, Inc." 1192 "Airmoniq Pro Kft." 1193 "emotas embedded communication GmbH" 1194 "Sierra Marine" 1195 "düvelsdorf" 1196 "Terra Care GmbH" 1197 "SOLGE Corporation" 1198 "ComLink Equipamentos Eletrônicos Ltda" 1199 "ELEO Technologies B.V." 1200 "Xinuo Information Technology (Xiamen) Corporation Limited" 1201 "Emisense Technologies, LLC" 1202 "OSCAR ELECTRONICS SRL (formerly OSCAR Elettronica)" 1203 "Equipment Technologies, Inc." 1204 "Miller Technology Incorporated" 1205 "Carbon Autonomous Robotic Systems" 1206 "STE Solutions B.V." 1207 "UEC Electronics" 1208 "Afflield Kft. (MachineryGuide)" 1209 "Bauser GmbH & Co. KG" 1210 "Ambra Solutions" 1211 "Kiwon Electronics Co., Ltd." 1212 "TAO Performance Limited" 1213 "Apollo Tyres Ltd" 1214 "Element 1" 1215 "Power Control Systems" 1216 "SMP Poland sp. z o.o." 1217 "FSG Fernsteuergeräte Kurt Oelsch GmbH" 1218 "Septentrio" 1219 "Weidmueller Interface GmbH & Co. KG" 1220 "Catamaran Electronics LLC" 1221 "Norcold Inc." 1222 "Tough Tech Ltd." 1223 "Toyo Agricultural Machinery Manufacturing Co., Ltd." 1224 "Neuser Elektrotechnik GmbH" 1225 "SeedMaster Manufacturing Ltd." 1226 "Piippo Hydraulic" 1227 "YAHATA Co., Ltd." 1228 "INTILION GmbH" 1229 "Arcon Designs, LLC" 1230 "Nick Abbey Digital Agriculture Ltd" 1231 "Excidor AB" 1232 "Treffler Maschinenbau GmbH & Co. KG" 1233 "nke Marine Electronics" 1234 "American Battery Solutions" 1235 "NESAN Automotive Inc." 1236 "Agrosystem" 1237 "Changzhou Lambda Electronic Co., Ltd" 1238 "Honda Electronics Co., Ltd" 1239 "SuperTrack Aps" 1240 "TiMOTION" 1241 "Ineo Systrans" 1242 "Super Start Batteries" 1243 "AvMap S.r.l." 1244 "Planti Center" 1245 "Raritan Engineering Company, Inc" 1246 "Rother Industries & Technology" 1247 "GRIFA" 1248 "O.M.F.B. S.p.A. Hydraulic Components" 1249 "Integrated Power Solutions AG" 1250 "ELHO" 1251 "Valmet Automotive EV Power Ltd" 1252 "APV - Technische Produkte GmbH" 1253 "Trafag AG" 1254 "ARADEX AG" 1255 "Altec Industries, Inc." 1256 "Dimensions Agri Technologies AS" 1257 "KOSTAL" 1258 "AGC Technologies" 1259 "Grayson Automotive Services Limited" 1260 "Interactive Technologies, Inc." 1261 "AgXeed" 1262 "Fort Robotics" 1263 "BOS Balance of Storage Systems AG" 1264 "Microelect" 1265 "IPETRONIK GmbH & Co KG" 1266 "Hyundai Doosan Infracore" 1267 "Wacker Neuson SE" 1268 "Back 40 Precision Inc." 1269 "VIS Hydraulics s.r.l." 1270 "Versalift Denmark A/S" 1271 "Raven Connected" 1272 "Samsara Inc." 1273 "Clearflame Engines Inc" 1274 "LDL Technology" 1275 "O.M.P. Officine Mazzocco Pagnoni S.r.l." 1276 "Aspin Kemp & Associates" 1277 "BMZ Germany GmbH" 1278 "Comrod Communication Group" 1279 "Ognibene Power S.p.A." 1280 "SANTEST CO., LTD." 1281 "iQuus" 1282 "COTEK ELECTRONIC IND. CO., LTD" 1283 "LTG Tech" 1284 "Robot Makers GmbH" 1285 "Graco Inc." 1286 "NEXAT GmbH" 1287 "Spartan Radar" 1288 "ANELLO Photonics" 1289 "Loadrite (Auckland) Ltd." 1290 "WaveTamer Partners LLC" 1291 "Forward Thinking Systems LLC" 1292 "SUMITOMO CONSTRUCTION MACHINERY Co., Ltd." 1293 "POSITAL" 1294 "TR-Electronic GmbH" 1295 "SIP d.d." 1296 "Hexagon" 1297 "Micro-Epsilon Messtechnik GmbH & Co. KG" 1298 "SFOGGIA Agriculture Division S.r.l." 1299 "Energy Solutions" 1300 "Watt Fuel Cell Corporation" 1301 "Tecumseh do Brasil Ltda" 1302 "ProMariner" 1303 "Carbon Bee AgTech" 1304 "Palfinger Europe GmbH" 1305 "dragonfly Energy" 1306 "Koden Electronics Co., Ltd." 1307 "Smart AG Systems" 1308 "Agtecnic" 1309 "Shanghai Zhichuan Electronic Tech Co., Ltd." 1310 "LPL Systems (formerly Loughborough Projects Ltd)" 1311 "Humphree AB" 1312 "Control Devices Pty Ltd" 1313 "United States Army - Ground Vehicle Systems Center" 1314 "Newton Crouch Company, LLC" 1315 "SMPC Technologies Ltd." 1316 "Hinkley Yachts" 1317 "GMM - Global Maritime Management GmbH" 1318 "Atlis Motor Vehicles" 1319 "I/O Controls Corporation" 1320 "Triskel Marine Ltd" 1321 "PATLITE Corporation" 1322 "Movimatica" 1323 "Briter Products, Inc." 1324 "Bourgault Industries" 1325 "OPW (formerly BASE Engineering Inc.)" 1326 "HBC-radiomatic GmbH" 1327 "Frans Vervaet B.V." 1328 "PerPlant ApS" 1329 "IDM S.r.l." 1330 "Warwick Control Technologies" 1331 "Dolphin Charger" 1332 "Fairbanks Scales, Inc." 1333 "xFarm Technologies SA" 1334 "Greer Company" 1335 "CPDEVICE" 1336 "Aegis Power Systems, Inc." 1337 "Barnacle Systems Inc." 1338 "Volta Trucks AB" 1339 "Tillett and Hague Technology Limited" 1340 "ORELTEK Elektronik ve Yazılım Teknolojileri" 1341 "Ag Express Electronics" 1342 "DKE-Data GmbH & Co. KG" 1343 "Heavy Data GmbH" 1344 "Haulotte Group" 1345 "PRIGNITZ Mikrosystemtechnik GmbH" 1346 "Einboeck GmbH" 1347 "Munckhof Fruit Tech Innovators" 1348 "Radian IoT, Inc." 1349 "ANNABURGER Nutzfahrzeug GmbH" 1350 "AGRONETIC" 1351 "Motorenfabrik Hatz GmbH & Co. KG" 1352 "NISHIYAMA Corporation" 1353 "Ocean LED Marine Ltd" 1354 "Técnicas de Electrónica y Automatismos, S.A." 1355 "DROP Agricultura Ltda" 1356 "Nordic Lights Ltd" 1357 "TireCheck" 1358 "Fontaine Fifth Wheel" 1359 "BlueNav" 1360 "Lemca Vision" 1361 "Nantong Saiyang Electronics Co., Ltd." 1362 "Zparq AB" 1363 "Calix AB" 1364 "Yashu Systems" 1365 "JVCKENWOOD Corporation" 1366 "Telemecanique Sensors & Switches" 1367 "Dewulf NV" 1368 "RAD Propulsion Ltd" 1369 "Electric Yacht" 1370 "Emtech S.A." 1371 "First Mode" 1372 "Elco Motor Yachts" 1373 "Centek Industries" 1374 "CASAPPA S.p.A." 1375 "ŠKODA ELECTRIC a.s." 1376 "SUNS International, LLC" 1377 "ABD Solutions" 1378 "Bertini SA" 1379 "Novag SAS" 1380 "ADVES GmbH & Co. KG" 1381 "Dr. Diesel Technologies" 1382 "Thornwave Labs Inc." 1383 "Alpego S.p.A." 1384 "Tecnoseal Foundry S.r.l." 1385 "Pro Charging Systems, LLC" 1386 "Smart Eye AB" 1387 "Radel (Pty) Ltd" 1388 "Nira Technology" 1389 "EVEX Co., LTD" 1390 "FJ Dynamics International Limited" 1391 "AriensCo" 1392 "Phoenix America LLC" 1393 "Powerland Technology Inc" 1394 "Zhejiang Ruixing Electromechanical Technology Co., Ltd." 1395 "MLB Industrial" 1396 "Fast Ag Solutions, LLC" 1397 "SaMASZ Sp. Z o.o." 1398 "Gobius Sensor Technology AB" 1399 "Hans Brantner & Sohn Fahrzeugbaugesellschaft mbH" 1400 "IWN GmbH & Co. KG" 1401 "ROM Communications Inc." 1402 "ComNav Technology Ltd." 1403 "Arco Marine" 1404 "BRUSA HyPower AG" 1405 "TELIG Electronics" 1406 "Lumilex ALT SRL" 1407 "Open-Agriculture" 1408 "Lenco Marine Inc." 1409 "Z Elektronika Kft." 1410 "Allan Equipment Manufacturing Ltd." 1411 "Shanghai Huace Navigation Technology Ltd." 1412 "Naocontrol S.L." 1413 "OHNOH2O LLC" 1414 "INTRACOM DEFENSE S.A." 1415 "Máquinas Agrícolas Jacto S.A." 1416 "Wavetronix LLC" 1417 "Revatek LLC" 1418 "Karluna Engineering" 1419 "iPatch Marine" 1420 "TALOS - Precision Measurement Technologies" 1421 "Clarios, LLC" 1422 "xTCU AG" 1423 "AC S.A." 1424 "Bewis" 1425 "Electronics in Agriculture, School of Engineering, University of Galway" 1426 "Samson Group" 1427 "REITER RESPIRO" 1428 "Samo Maschinenbau GmbH" 1429 "Nikola Corporation" 1430 "Mantracourt Electronics Ltd" 1431 "Nauto Inc." 1432 "MDH Defence Ltd." 1433 "Unicontrol ApS" 1434 "eSurvey GNSS Ltd." 1435 "Heilongjiang Huida Technology Co., Ltd" 1436 "M-extend" 1437 "DOKEN Technology Co. Ltd." 1438 "Aeolionics" 1439 "PredictWind Ltd" 1440 "Egis Mobile Electric" 1441 "Shanghai Allynav Technology Co.,Ltd." 1442 "EVYTRA GmbH" 1443 "SoilEssentials Limited" 1444 "Micropower Group" 1445 "Starboard Yacht Group" 1446 "Roswell Marine" 1447 "Innotag Distributions Inc." 1448 "Elmer's Manufacturing" 1449 "Bontaz Centre" 1450 "Agrivaux" 1451 "Guangdong ePropulsion Technology Ltd." 1452 "Micro-Air LLC" 1453 "Vital Battery" 1454 "QTIS B.V." 1455 "Eberspächer Climate Control Systems International GmbH" 1456 "Krampe Fahrzeugbau GmbH" 1457 "Albach Maschinenbau AG" 1458 "RideController LLC" 1459 "Advanced Input Systems" 1460 "Tocaro Blue" 1461 "Vanquish Yachts" 1462 "Trackunit ApS" 1463 "STOK Electric" 1464 "Hi-Target Surveying Instrument Co., Ltd." 1465 "Watteco" 1466 "Sveaverken Svea Agri AB" 1467 "S.A.E.T. s.r.l." 1468 "Senquip" 1469 "LS Mtron" 1470 "GemOne NV" 1471 "FT Technologies" 1472 "Acculon Energy" 1473 "Cranesmart Systems, Inc." 1474 "Calex Electronics Limited" 1475 "DSP Solutions, Inc." 1476 "Wilhelm Stoll Maschinenfabrik GmbH" 1477 "TOBROCO-GIANT" 1478 "Alps Alpine Co., Ltd." 1479 "A-Electronix" 1480 "Thermo King" 1481 "E-Force Marine" 1482 "CMC Marine" 1483 "Nanjing Sandemarine Information Technology Co., Ltd." 1484 "AgroOSA" 1485 "Lester Electrical" 1486 "Xpanner" 1487 "Geosoft" 1488 "Boetkin Technology Co., LTD" 1489 "Lite-Check LLC" 1490 "Clean Republic SODO, LLC" 1491 "Power Pollen" 1492 "Softivert" 1493 "Jantop Oy" 1494 "RAPITRONICS" 1495 "FlyAgData" 1496 "AgriRobot" 1497 "ERMO Spa" 1498 "PM Pfanzelt Maschinenbau GmbH" 1499 "Hydrasystem SP. Z O.O." 1500 "Scanstrut Inc." 1501 "Reverso Pumps LLC" 1502 "Barantech" 1503 "Rosemount Specialty Products" 1504 "Nimbus Power Systems, Inc." 1505 "BC Motion" 1506 "Expion360" 1507 "Apex.AI, Inc." 1508 "Xwatch Safety Solutions Ltd. part of Hexagon" 1509 "Bondioli & Pavesi" 1510 "Austin Motor Works" 1511 "APATOR METRA s.r.o." 1512 "Lumitec LLC" 1513 "Sy-Klone International" 1514 "SYMX.ai" 1515 "Ingeniería y Sistemas Cerea" 1516 "THERMIS spol. s r.o." 1517 "Daedong Corporation" 1518 "Nova Kool Manufacturing ULC" 1519 "Volboff Electron Science and Technology Co., Ltd." 1520 "SRT Marine Systems PLC" 1521 "Agricolmeccanica" 1522 "American Thermal Instruments" 1523 "Carlson Software" 1524 "Ocean Infinity Solutions Limited" 1525 "Emsiso-emDrive" 1526 "MITSUBISHI MAHINDRA AGRICULTURAL MACHINERY CO.,LTD." 1527 "Richardt Steuer- und Regelgeraete GmbH" 1528 "Savant Technology" 1529 "Industrie Elektronik Brilon GmbH" 1530 "Roelama B.V." 1531 "Kobelco Construction Machinery Co.,Ltd." 1532 "E-Switch, Inc." 1533 "Rieker Inc." 1534 "BluVein" 1535 "LOX Container Technology AB" 1536 "Tatra Trucks a.s." 1537 "Anyload Weigh & Measure Inc." 1538 "Quick S.p.A." 1539 "Ceday Information Technologies" 1540 "Ideas & Motion" 1541 "Solid State Marine" 1542 "Global Digital Instruments" 1543 "GT Joysticks AG" 1544 "Geophysical Survey Systems, Inc." 1545 "RoadEazy" 1546 "ESMART" 1547 "Weichai Lovol Intelligent Agricultural Technology Co., Ltd." 1549 "AM Co., Ltd." 1550 "Mario Tanzi S.A." 1551 "LMCE Group" 1552 "Antoniosi Tecnologia Agroindustrial Ltda" 1553 "Boughton Engineering LTD" 1554 "Frigus AB" 1555 "Safiery" 1556 "B. Kaufmann AG Landmaschinen" 1557 "Interfacom S.A.U." 1558 "Intangles Lab Private Limited" 1559 "Kar-Tech, Inc." 1560 "MACOME CORPORATION" 1561 "Fox Marine" 1562 "Kingsat Communications Co., Ltd" 1563 "Wabtec Graham White" 1564 "Pro-Guide Batteries" 1565 "Livemac Co., Ltd." 1566 "OUTSET" 1567 "Hagedorn Software Engineering GmbH" 1568 "Aigro" 1569 "621 Technologies Inc." 1570 "Unverferth Manufacturing Company Inc." 1571 "Super B" 1572 "SMARTLINE Co., Ltd." 1573 "R.H. Sheppard" 1574 "SIGMA4 SRL" 1575 "DieselHeat" 1576 "RB International S.r.l." 1577 "Ironstone AG" 1578 "MidNite Solar Inc." 1579 "Hydro Engineering" 1580 "Nabtesco Corporation" 1581 "Metro Marine LLC" 1582 "Samsung Heavy Industries Co., Ltd." 1583 "MULTI-WING GROUP A/S" 1584 "TWK-ELEKTRONIK GmbH" 1585 "Qianxun Spatial Intelligence (Zhejiang) Inc." 1586 "XAG CO., LTD." 1587 "BURGER GROUP" 1588 "MORESIL" 1589 "HÜBNER GmbH & Co. KG" 1590 "Monpaineis" 1591 "WaterWorld Electronics" 1592 "Incomagri Máquinas Agrícolas Ltda" 1593 "Cordon Technologies" 1594 "Elwell Corporation" 1595 "Pruefrex engineering e motion gmbh" 1596 "Neosens" 1597 "S.A.S. Desvoys & Fils" 1598 "Di Goro" 1599 "Kamtec" 1600 "Consolidated Metco, Inc." 1601 "T/CCI Manufacturing, LLC" 1602 "Norcross Marine Products" 1603 "Rockville Audio" 1604 "RoverSense Technologies" 1605 "Blue Wolf" 1606 "SENSAR MARINE INC." 1607 "Micro-Key" 1608 "Quectel" 1609 "NanoNord A/S" 1610 "Simarine d.o.o." 1611 "Ningbo Haibo Group Co., Ltd." 1612 "BLUETTI" 1613 "Whisperpower" 1614 "Risseeuw Techniek" 1615 "J.Assy" 1616 "Satel Oy" 1617 "DRUDLES s.r.o." 1618 "The Carlisle and Finch Co." 1619 "Clemens GmbH & Co. KG" 1620 "BlueNav" 1621 "Mach Inc." 1622 "Brettmeister Elektronik" 1623 "PRO Charging Systems, LLC" 1624 "CrossControl" 1625 "DMX Power LLC" 1626 "SMP STABIL GmbH" 1627 "Roter Italia" 1628 "Vanemar, Inc." 1629 "dSPACE SE & Co. KG" 1630 "Rainer Meyer Landmaschinen GmbH" 1631 "Leidos" 1632 "Zocon" 1633 "Zydro Marine Technologies, Inc." 1634 "IBISUL ELETRÔNICA LTDA" 1635 "Saframax Industrial" 1636 "TBB POWER (XIAMEN) Co., Ltd." 1637 "Scherzinger Pumpen GmbH & Co. KG" 1638 "TEMPA TEKNIK" 1639 "GEA Farm Technologies Canada Inc." 1650 "Shanghai Infipax Technology Co., Ltd." 1653 "Schaffer Farming Technologies" 1850 "Seastar Solutions (formerly Teleflex)" 1851 "RayMarine" 1852 "Navionics" 1853 "Japan Radio Co" 1854 "Northstar Technologies" 1855 "Furuno USA" 1856 "Trimble" 1857 "Simrad" 1858 "Litton" 1859 "Kvasar AB" 1860 "MMP" 1861 "Vector North America (formerly Vector Cantech)" 1862 "Sanshin" 1863 "Thomas G. Faria Co." ;
VAL_ 2582577152 Industry_Code 0 "Global" 1 "Highway" 2 "Agriculture" 3 "Construction" 4 "Marine Industry" 5 "Industrial" ;

BA_DEF_ BO_ "GenMsgCycleTime" INT 0 60000;
BA_DEF_ BO_ "ProtocolType" STRING;

BA_DEF_ BO_ "J1939PGN" INT 0 262143;
BA_ "J1939PGN" BO_ 2566779904 65012;
BA_ "J1939PGN" BO_ 2566780160 65013;
BA_ "J1939PGN" BO_ 2566780416 65014;
BA_ "J1939PGN" BO_ 2566780672 65015;
BA_ "J1939PGN" BO_ 2566780928 65016;
BA_ "J1939PGN" BO_ 2566781184 65017;
BA_ "J1939PGN" BO_ 2566781440 65018;
BA_ "J1939PGN" BO_ 2566781696 65019;
BA_ "J1939PGN" BO_ 2566781952 65020;
BA_ "J1939PGN" BO_ 2566782208 65021;
BA_ "J1939PGN" BO_ 2566782464 65022;
BA_ "J1939PGN" BO_ 2566782720 65023;
BA_ "J1939PGN" BO_ 2566782976 65024;
BA_ "J1939PGN" BO_ 2566783232 65025;
BA_ "J1939PGN" BO_ 2566783488 65026;
BA_ "J1939PGN" BO_ 2566783744 65027;
BA_ "J1939PGN" BO_ 2566784000 65028;
BA_ "J1939PGN" BO_ 2566784256 65029;
BA_ "J1939PGN" BO_ 2566784512 65030;
BA_ "J1939PGN" BO_ 2566784768 65031;
BA_ "GenMsgCycleTime" BO_ 2566784768 1000;
BA_ "J1939PGN" BO_ 2566810112 65130;
BA_ "GenMsgCycleTime" BO_ 2566810112 500;
BA_ "J1939PGN" BO_ 2566824960 65188;
BA_ "GenMsgCycleTime" BO_ 2566824960 500;
BA_ "J1939PGN" BO_ 2566825216 65189;
BA_ "GenMsgCycleTime" BO_ 2566825216 500;
BA_ "J1939PGN" BO_ 2566825472 65190;
BA_ "GenMsgCycleTime" BO_ 2566825472 500;
BA_ "J1939PGN" BO_ 2566828288 65201;
BA_ "GenMsgCycleTime" BO_ 2566828288 1000;
BA_ "J1939PGN" BO_ 2566831360 65213;
BA_ "GenMsgCycleTime" BO_ 2566831360 1000;
BA_ "J1939PGN" BO_ 2566831616 65214;
BA_ "J1939PGN" BO_ 2566834688 65226;
BA_ "J1939PGN" BO_ 2566838272 65240;
BA_ "J1939PGN" BO_ 2566839040 65243;
BA_ "GenMsgCycleTime" BO_ 2566839040 500;
BA_ "J1939PGN" BO_ 2566839296 65244;
BA_ "GenMsgCycleTime" BO_ 2566839296 1000;
BA_ "J1939PGN" BO_ 2566840064 65247;
BA_ "GenMsgCycleTime" BO_ 2566840064 250;
BA_ "J1939PGN" BO_ 2566841600 65253;
BA_ "GenMsgCycleTime" BO_ 2566841600 10000;
BA_ "J1939PGN" BO_ 2566842624 65257;
BA_ "GenMsgCycleTime" BO_ 2566842624 1000;
BA_ "J1939PGN" BO_ 2566843904 65262;
BA_ "GenMsgCycleTime" BO_ 2566843904 1000;
BA_ "J1939PGN" BO_ 2566844928 65266;
BA_ "GenMsgCycleTime" BO_ 2566844928 100;
BA_ "J1939PGN" BO_ 2566845696 65269;
BA_ "J1939PGN" BO_ 2566845952 65270;
BA_ "GenMsgCycleTime" BO_ 2566845952 500;
BA_ "J1939PGN" BO_ 2566846208 65271;
BA_ "J1939PGN" BO_ 2566846464 65272;
BA_ "GenMsgCycleTime" BO_ 2566846464 1000;
BA_ "J1939PGN" BO_ 2566848512 65280;
BA_ "J1939PGN" BO_ 2582446080 126208;
BA_ "J1939PGN" BO_ 2582577152 126720;
BA_ "J1939PGN" BO_ 2582642688 126976;
BA_ "J1939PGN" BO_ 2583625728 130816;
BA_ "J1939PGN" BO_ 2566844672 65265;
BA_ "GenMsgCycleTime" BO_ 2566844672 100;
